VERSION ""

NS_ :

BS_:

BU_: CAMERA_ALL ALM_DX ALM_SX CAMERA_DEFAULT LOGBOX CAMERA_POS0 CAMERA_POS1 CAMERA_POS2 CAMERA_POS3 CAMERA_POS4 CAMERA_POS5 CAMERA_POS6 CAMERA_POS7 SVS RUR RUF RUC BC _TESTER BMS3_ADB BMS0_ADB BMS4_ADB BMS5_ADB BMS6_ADB

BO_ 2566850046 _BMS0_ADB_BatterySummaryStatus: 8 BMS0_ADB
 SG_ BMS0_ADB_BatSumS_serial_number : 0|24@1+ (1,0) [0|16777214] "-"  BC,LOGBOX
 SG_ BMS0_ADB_BatSumS_Reserved_01 : 24|8@1+ (1,0) [0|255] "-"  LOGBOX
 SG_ BMS0_ADB_BatSumS_State_of_Charge : 32|8@1+ (1,0) [0|100] "%"  LOGBOX,BC
 SG_ BMS0_ADB_BatSumS_State_of_Health : 40|8@1+ (1,0) [0|2] "-"  LOGBOX,BC
 SG_ BMS0_ADB_BatSumS_Temp_Alarm : 48|2@1+ (1,0) [0|3] "-"  LOGBOX,BC
 SG_ BMS0_ADB_BatSumS_DischargeDis : 50|1@1+ (1,0) [0|1] "-"  LOGBOX,BC
 SG_ BMS0_ADB_BatSumS_ChargingDisable : 51|1@1+ (1,0) [0|1] "-"  LOGBOX,BC
 SG_ BMS0_ADB_BatSumS_HeaterEnabled : 52|1@1+ (1,0) [0|1] "-"  LOGBOX,BC
 SG_ BMS0_ADB_BatSumS_BypassEnabled : 53|1@1+ (1,0) [0|1] "-"  LOGBOX,BC
 SG_ BMS0_ADB_BatSumS_Voltage_Alarm : 56|1@1+ (1,0) [0|1] "-"  LOGBOX,BC
 SG_ BMS0_ADB_BatSumS_Reserved_04 : 54|2@1+ (1,0) [0|3] "-"  LOGBOX
 SG_ BMS0_ADB_BatSumS_Reserved_05 : 57|1@1+ (1,0) [0|1] "-"  LOGBOX,BC
 SG_ BMS0_ADB_BatSumS_Reserved_06 : 58|1@1+ (1,0) [0|1] "-"  LOGBOX
 SG_ BMS0_ADB_BatSumS_Reserved_07 : 59|1@1+ (1,0) [0|1] "-"  LOGBOX
 SG_ BMS0_ADB_BatSumS_Reserved_08 : 60|1@1+ (1,0) [0|1] "-"  LOGBOX
 SG_ BMS0_ADB_BatSumS_Reserved_09 : 61|1@1+ (1,0) [0|1] "-"  LOGBOX
 SG_ BMS0_ADB_BatSumS_Reserved_10 : 62|1@1+ (1,0) [0|1] "-"  LOGBOX
 SG_ BMS0_ADB_BatSumS_Reserved_11 : 63|1@1+ (1,0) [0|1] "-"  LOGBOX

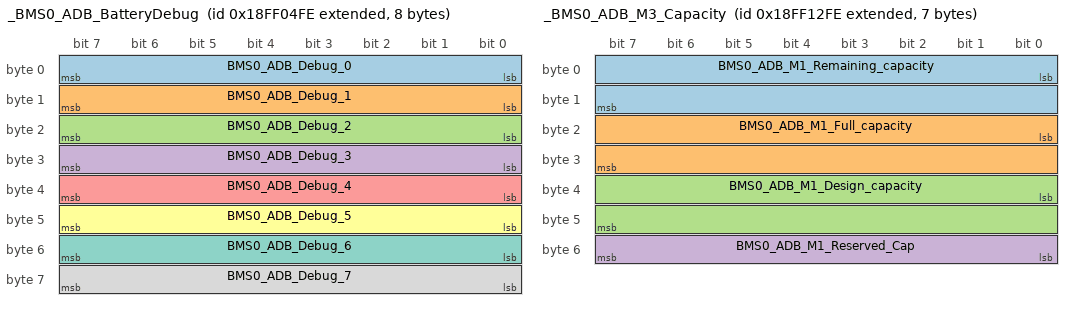
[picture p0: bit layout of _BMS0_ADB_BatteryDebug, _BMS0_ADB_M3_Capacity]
BO_ 2566849790 _BMS0_ADB_BatteryDebug: 8 BMS0_ADB
 SG_ BMS0_ADB_Debug_0 : 0|8@1+ (1,0) [0|255] "-"  LOGBOX
 SG_ BMS0_ADB_Debug_1 : 8|8@1+ (1,0) [0|255] "-"  LOGBOX
 SG_ BMS0_ADB_Debug_2 : 16|8@1+ (1,0) [0|255] "-"  LOGBOX
 SG_ BMS0_ADB_Debug_3 : 24|8@1+ (1,0) [0|255] "-"  LOGBOX
 SG_ BMS0_ADB_Debug_4 : 32|8@1+ (1,0) [0|255] "-"  LOGBOX
 SG_ BMS0_ADB_Debug_5 : 40|8@1+ (1,0) [0|255] "-"  LOGBOX
 SG_ BMS0_ADB_Debug_6 : 48|8@1+ (1,0) [0|255] "-"  LOGBOX
 SG_ BMS0_ADB_Debug_7 : 56|8@1+ (1,0) [0|255] "-"  LOGBOX

BO_ 2566853374 _BMS0_ADB_M3_Capacity: 7 BMS0_ADB
 SG_ BMS0_ADB_M1_Remaining_capacity : 0|16@1+ (0.01,0) [0|642.55] "Ah"  LOGBOX
 SG_ BMS0_ADB_M1_Full_capacity : 16|16@1+ (0.01,0) [0|642.55] "Ah"  LOGBOX
 SG_ BMS0_ADB_M1_Design_capacity : 32|16@1+ (0.01,0) [0|642.55] "Ah"  LOGBOX
 SG_ BMS0_ADB_M1_Reserved_Cap : 48|8@1+ (1,0) [255|255] "-"  LOGBOX

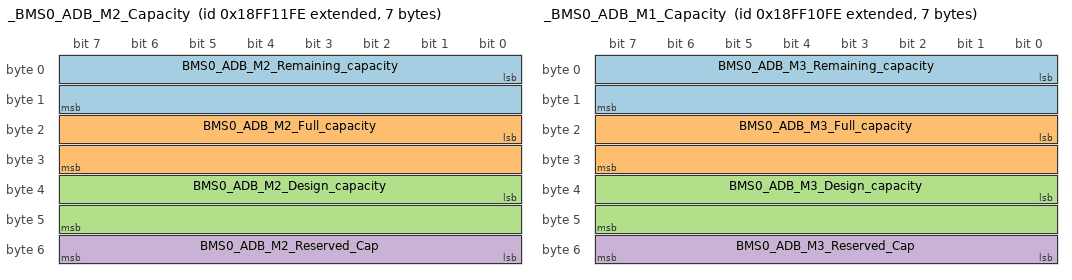
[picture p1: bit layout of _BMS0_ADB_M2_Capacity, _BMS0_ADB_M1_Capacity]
BO_ 2566853118 _BMS0_ADB_M2_Capacity: 7 BMS0_ADB
 SG_ BMS0_ADB_M2_Remaining_capacity : 0|16@1+ (0.01,0) [0|642.55] "Ah"  LOGBOX
 SG_ BMS0_ADB_M2_Full_capacity : 16|16@1+ (0.01,0) [0|642.55] "Ah"  LOGBOX
 SG_ BMS0_ADB_M2_Design_capacity : 32|16@1+ (0.01,0) [0|642.55] "Ah"  LOGBOX
 SG_ BMS0_ADB_M2_Reserved_Cap : 48|8@1+ (1,0) [255|255] "-"  LOGBOX

BO_ 2566852862 _BMS0_ADB_M1_Capacity: 7 BMS0_ADB
 SG_ BMS0_ADB_M3_Remaining_capacity : 0|16@1+ (0.01,0) [0|642.55] "Ah"  LOGBOX
 SG_ BMS0_ADB_M3_Full_capacity : 16|16@1+ (0.01,0) [0|642.55] "Ah"  LOGBOX
 SG_ BMS0_ADB_M3_Design_capacity : 32|16@1+ (0.01,0) [0|642.55] "Ah"  LOGBOX
 SG_ BMS0_ADB_M3_Reserved_Cap : 48|8@1+ (1,0) [255|255] "-"  LOGBOX

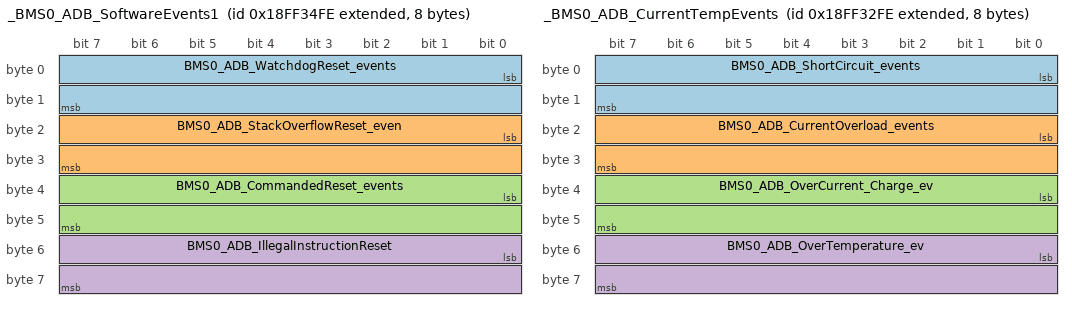
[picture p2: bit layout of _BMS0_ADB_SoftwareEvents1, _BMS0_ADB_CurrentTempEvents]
BO_ 2566862078 _BMS0_ADB_SoftwareEvents1: 8 BMS0_ADB
 SG_ BMS0_ADB_WatchdogReset_events : 0|16@1+ (1,0) [0|64255] "-"  LOGBOX
 SG_ BMS0_ADB_StackOverflowReset_even : 16|16@1+ (1,0) [0|64255] "-"  LOGBOX
 SG_ BMS0_ADB_CommandedReset_events : 32|16@1+ (1,0) [0|64255] "-"  LOGBOX
 SG_ BMS0_ADB_IllegalInstructionReset : 48|16@1+ (1,0) [0|64255] "-"  LOGBOX

BO_ 2566861822 _BMS0_ADB_VoltageEvents: 4 BMS0_ADB
 SG_ BMS0_ADB_OverVoltage_events : 0|16@1+ (1,0) [0|64255] "-"  LOGBOX
 SG_ BMS0_ADB_UnderVoltage_events : 16|16@1+ (1,0) [0|64255] "-"  LOGBOX

BO_ 2566861566 _BMS0_ADB_CurrentTempEvents: 8 BMS0_ADB
 SG_ BMS0_ADB_ShortCircuit_events : 0|16@1+ (1,0) [0|64255] "-"  LOGBOX
 SG_ BMS0_ADB_CurrentOverload_events : 16|16@1+ (1,0) [0|64255] "-"  LOGBOX
 SG_ BMS0_ADB_OverCurrent_Charge_ev : 32|16@1+ (1,0) [0|64255] "-"  LOGBOX
 SG_ BMS0_ADB_OverTemperature_ev : 48|16@1+ (1,0) [0|64255] "-"  LOGBOX

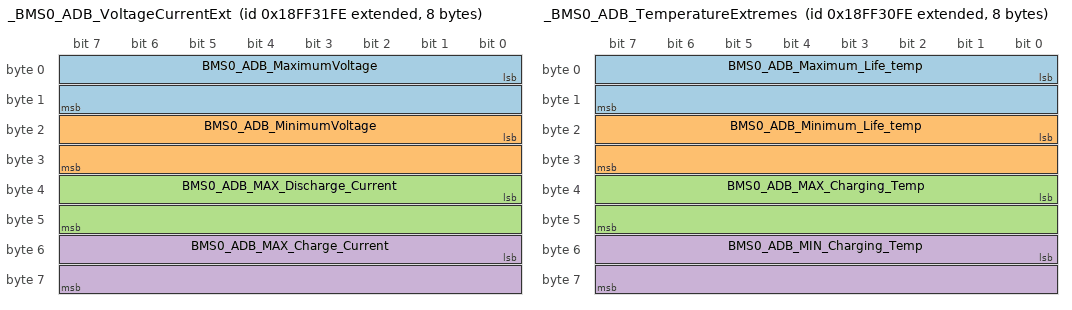
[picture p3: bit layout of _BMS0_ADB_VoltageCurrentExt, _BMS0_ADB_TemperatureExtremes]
BO_ 2566861310 _BMS0_ADB_VoltageCurrentExt: 8 BMS0_ADB
 SG_ BMS0_ADB_MaximumVoltage : 0|16@1+ (0.001,0) [0|64255] "V"  LOGBOX
 SG_ BMS0_ADB_MinimumVoltage : 16|16@1+ (0.001,0) [0|64255] "V"  LOGBOX
 SG_ BMS0_ADB_MAX_Discharge_Current : 32|16@1+ (0.1,0) [0|6425.5] "A"  LOGBOX
 SG_ BMS0_ADB_MAX_Charge_Current : 48|16@1+ (0.1,0) [0|6425.5] "A"  LOGBOX

BO_ 2566861054 _BMS0_ADB_TemperatureExtremes: 8 BMS0_ADB
 SG_ BMS0_ADB_Maximum_Life_temp : 0|16@1+ (0.1,-100) [-100|200] "°C"  LOGBOX
 SG_ BMS0_ADB_Minimum_Life_temp : 16|16@1+ (0.1,-100) [-100|200] "°C"  LOGBOX
 SG_ BMS0_ADB_MAX_Charging_Temp : 32|16@1+ (0.1,-100) [-100|200] "°C"  LOGBOX
 SG_ BMS0_ADB_MIN_Charging_Temp : 48|16@1+ (0.1,-100) [-100|200] "°C"  LOGBOX

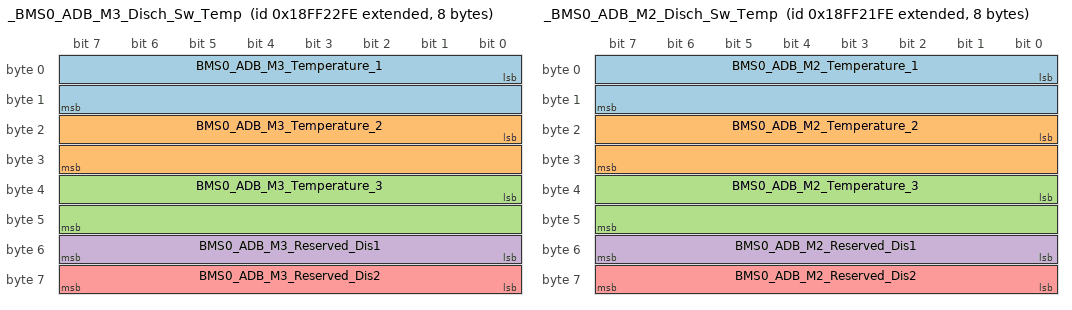
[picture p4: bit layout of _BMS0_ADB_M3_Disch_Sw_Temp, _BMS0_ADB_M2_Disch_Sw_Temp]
BO_ 2566857470 _BMS0_ADB_M3_Disch_Sw_Temp: 8 BMS0_ADB
 SG_ BMS0_ADB_M3_Temperature_1 : 0|16@1+ (0.1,-100) [-100|200] "°C"  LOGBOX
 SG_ BMS0_ADB_M3_Temperature_2 : 16|16@1+ (0.1,-100) [-100|200] "°C"  LOGBOX
 SG_ BMS0_ADB_M3_Temperature_3 : 32|16@1+ (0.1,-100) [-100|200] "°C"  LOGBOX
 SG_ BMS0_ADB_M3_Reserved_Dis1 : 48|8@1+ (1,0) [255|255] "-"  LOGBOX
 SG_ BMS0_ADB_M3_Reserved_Dis2 : 56|8@1+ (1,0) [255|255] "-"  LOGBOX

BO_ 2566857214 _BMS0_ADB_M2_Disch_Sw_Temp: 8 BMS0_ADB
 SG_ BMS0_ADB_M2_Temperature_1 : 0|16@1+ (0.1,-100) [-100|200] "°C"  LOGBOX
 SG_ BMS0_ADB_M2_Temperature_2 : 16|16@1+ (0.1,-100) [-100|200] "°C"  LOGBOX
 SG_ BMS0_ADB_M2_Temperature_3 : 32|16@1+ (0.1,-100) [-100|200] "°C"  LOGBOX
 SG_ BMS0_ADB_M2_Reserved_Dis1 : 48|8@1+ (1,0) [255|255] "-"  LOGBOX
 SG_ BMS0_ADB_M2_Reserved_Dis2 : 56|8@1+ (1,0) [255|255] "-"  LOGBOX

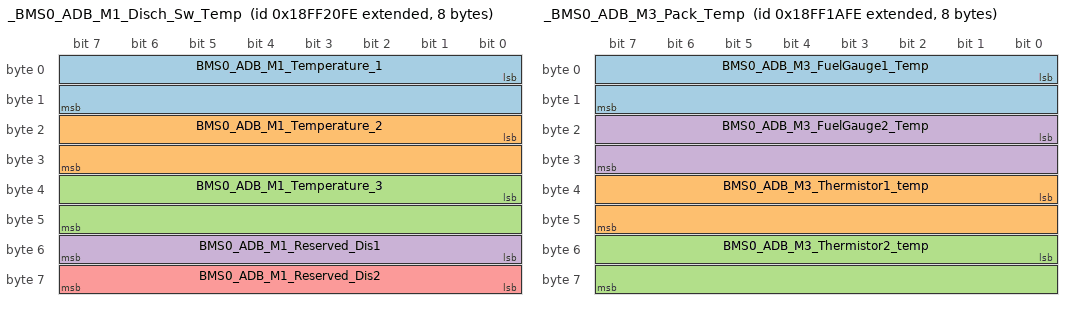
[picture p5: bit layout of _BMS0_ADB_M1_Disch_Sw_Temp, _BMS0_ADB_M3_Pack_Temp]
BO_ 2566856958 _BMS0_ADB_M1_Disch_Sw_Temp: 8 BMS0_ADB
 SG_ BMS0_ADB_M1_Temperature_1 : 0|16@1+ (0.1,-100) [-100|200] "°C"  LOGBOX
 SG_ BMS0_ADB_M1_Temperature_2 : 16|16@1+ (0.1,-100) [-100|200] "°C"  LOGBOX
 SG_ BMS0_ADB_M1_Temperature_3 : 32|16@1+ (0.1,-100) [-100|200] "°C"  LOGBOX
 SG_ BMS0_ADB_M1_Reserved_Dis1 : 48|8@1+ (1,0) [255|255] "-"  LOGBOX
 SG_ BMS0_ADB_M1_Reserved_Dis2 : 56|8@1+ (1,0) [255|255] "-"  LOGBOX

BO_ 2566855422 _BMS0_ADB_M3_Pack_Temp: 8 BMS0_ADB
 SG_ BMS0_ADB_M3_FuelGauge1_Temp : 0|16@1+ (0.1,-100) [-100|200] "°C"  LOGBOX
 SG_ BMS0_ADB_M3_Thermistor1_temp : 32|16@1+ (0.1,-100) [-100|200] "-"  LOGBOX
 SG_ BMS0_ADB_M3_Thermistor2_temp : 48|16@1+ (0.1,-100) [-100|200] "-"  LOGBOX
 SG_ BMS0_ADB_M3_FuelGauge2_Temp : 16|16@1+ (0.1,-100) [-100|200] "°C"  LOGBOX

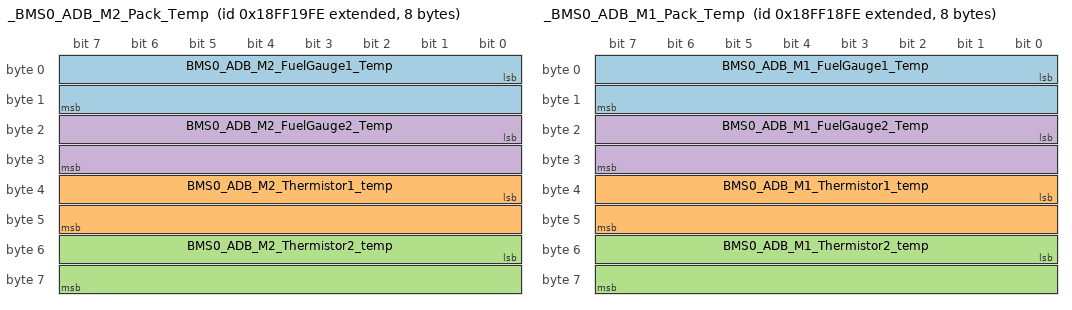
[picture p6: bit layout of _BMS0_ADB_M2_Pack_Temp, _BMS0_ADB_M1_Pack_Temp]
BO_ 2566855166 _BMS0_ADB_M2_Pack_Temp: 8 BMS0_ADB
 SG_ BMS0_ADB_M2_FuelGauge1_Temp : 0|16@1+ (0.1,-100) [-100|200] "°C"  LOGBOX
 SG_ BMS0_ADB_M2_Thermistor1_temp : 32|16@1+ (0.1,-100) [-100|200] "-"  LOGBOX
 SG_ BMS0_ADB_M2_Thermistor2_temp : 48|16@1+ (0.1,-100) [-100|200] "-"  LOGBOX
 SG_ BMS0_ADB_M2_FuelGauge2_Temp : 16|16@1+ (0.1,-100) [-100|200] "°C"  LOGBOX

BO_ 2566854910 _BMS0_ADB_M1_Pack_Temp: 8 BMS0_ADB
 SG_ BMS0_ADB_M1_FuelGauge1_Temp : 0|16@1+ (0.1,-100) [-100|200] "°C"  LOGBOX
 SG_ BMS0_ADB_M1_Thermistor1_temp : 32|16@1+ (0.1,-100) [-100|200] "-"  LOGBOX
 SG_ BMS0_ADB_M1_Thermistor2_temp : 48|16@1+ (0.1,-100) [-100|200] "-"  LOGBOX
 SG_ BMS0_ADB_M1_FuelGauge2_Temp : 16|16@1+ (0.1,-100) [-100|200] "°C"  LOGBOX

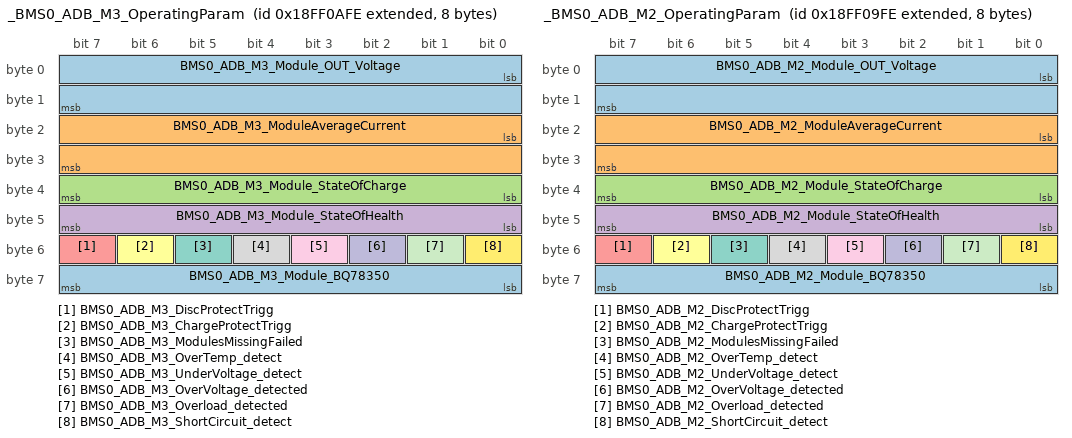
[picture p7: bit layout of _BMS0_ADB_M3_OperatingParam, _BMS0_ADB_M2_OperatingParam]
BO_ 2566851326 _BMS0_ADB_M3_OperatingParam: 8 BMS0_ADB
 SG_ BMS0_ADB_M3_Module_OUT_Voltage : 0|16@1+ (0.001,0) [0|64255] "V"  LOGBOX
 SG_ BMS0_ADB_M3_ModuleAverageCurrent : 16|16@1+ (0.1,-5500) [-5500|925.5] "A"  LOGBOX
 SG_ BMS0_ADB_M3_Module_StateOfCharge : 32|8@1+ (1,0) [0|100] "%"  LOGBOX
 SG_ BMS0_ADB_M3_Module_StateOfHealth : 40|8@1+ (1,0) [0|2] "-"  LOGBOX
 SG_ BMS0_ADB_M3_DiscProtectTrigg : 55|1@1+ (1,0) [0|1] "-"  LOGBOX
 SG_ BMS0_ADB_M3_ChargeProtectTrigg : 54|1@1+ (1,0) [0|1] "-"  LOGBOX
 SG_ BMS0_ADB_M3_ModulesMissingFailed : 53|1@1+ (1,0) [0|1] "-"  LOGBOX
 SG_ BMS0_ADB_M3_OverTemp_detect : 52|1@1+ (1,0) [0|1] "-"  LOGBOX
 SG_ BMS0_ADB_M3_UnderVoltage_detect : 51|1@1+ (1,0) [0|1] "-"  LOGBOX
 SG_ BMS0_ADB_M3_OverVoltage_detected : 50|1@1+ (1,0) [0|1] "-"  LOGBOX
 SG_ BMS0_ADB_M3_Overload_detected : 49|1@1+ (1,0) [0|1] "-"  LOGBOX
 SG_ BMS0_ADB_M3_ShortCircuit_detect : 48|1@1+ (1,0) [0|1] "-"  LOGBOX
 SG_ BMS0_ADB_M3_Module_BQ78350 : 56|8@1+ (1,0) [0|2] "-"  LOGBOX

BO_ 2566851070 _BMS0_ADB_M2_OperatingParam: 8 BMS0_ADB
 SG_ BMS0_ADB_M2_Module_OUT_Voltage : 0|16@1+ (0.001,0) [0|64255] "V"  LOGBOX
 SG_ BMS0_ADB_M2_ModuleAverageCurrent : 16|16@1+ (0.1,-5500) [-5500|925.5] "A"  LOGBOX
 SG_ BMS0_ADB_M2_Module_StateOfCharge : 32|8@1+ (1,0) [0|100] "%"  LOGBOX
 SG_ BMS0_ADB_M2_Module_StateOfHealth : 40|8@1+ (1,0) [0|2] "-"  LOGBOX
 SG_ BMS0_ADB_M2_DiscProtectTrigg : 55|1@1+ (1,0) [0|1] "-"  LOGBOX
 SG_ BMS0_ADB_M2_ChargeProtectTrigg : 54|1@1+ (1,0) [0|1] "-"  LOGBOX
 SG_ BMS0_ADB_M2_ModulesMissingFailed : 53|1@1+ (1,0) [0|1] "-"  LOGBOX
 SG_ BMS0_ADB_M2_OverTemp_detect : 52|1@1+ (1,0) [0|1] "-"  LOGBOX
 SG_ BMS0_ADB_M2_UnderVoltage_detect : 51|1@1+ (1,0) [0|1] "-"  LOGBOX
 SG_ BMS0_ADB_M2_OverVoltage_detected : 50|1@1+ (1,0) [0|1] "-"  LOGBOX
 SG_ BMS0_ADB_M2_Overload_detected : 49|1@1+ (1,0) [0|1] "-"  LOGBOX
 SG_ BMS0_ADB_M2_ShortCircuit_detect : 48|1@1+ (1,0) [0|1] "-"  LOGBOX
 SG_ BMS0_ADB_M2_Module_BQ78350 : 56|8@1+ (1,0) [0|2] "-"  LOGBOX

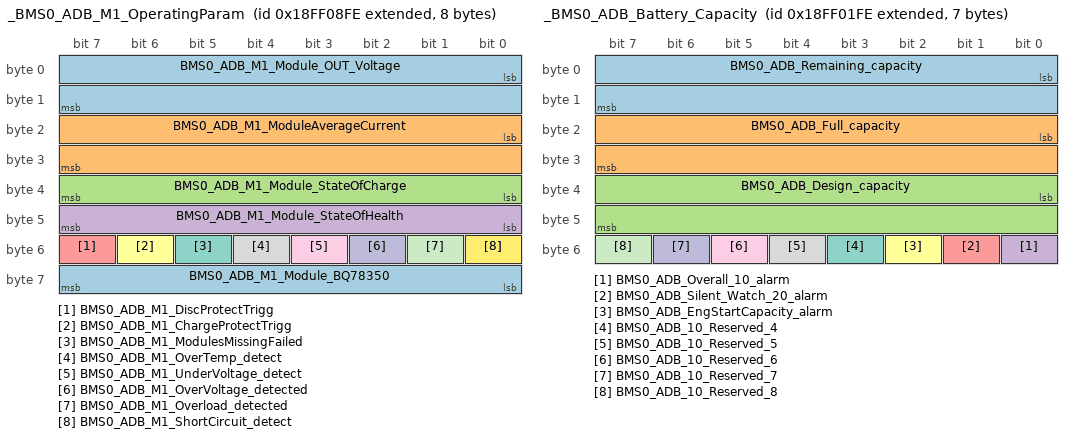
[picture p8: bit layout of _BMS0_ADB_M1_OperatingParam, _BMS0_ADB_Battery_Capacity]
BO_ 2566850814 _BMS0_ADB_M1_OperatingParam: 8 BMS0_ADB
 SG_ BMS0_ADB_M1_Module_OUT_Voltage : 0|16@1+ (0.001,0) [0|64255] "V"  LOGBOX
 SG_ BMS0_ADB_M1_ModuleAverageCurrent : 16|16@1+ (0.1,-5500) [-5500|925.5] "A"  LOGBOX
 SG_ BMS0_ADB_M1_Module_StateOfCharge : 32|8@1+ (1,0) [0|100] "%"  LOGBOX
 SG_ BMS0_ADB_M1_Module_StateOfHealth : 40|8@1+ (1,0) [0|2] "-"  LOGBOX
 SG_ BMS0_ADB_M1_DiscProtectTrigg : 55|1@1+ (1,0) [0|1] "-"  LOGBOX
 SG_ BMS0_ADB_M1_ChargeProtectTrigg : 54|1@1+ (1,0) [0|1] "-"  LOGBOX
 SG_ BMS0_ADB_M1_ModulesMissingFailed : 53|1@1+ (1,0) [0|1] "-"  LOGBOX
 SG_ BMS0_ADB_M1_OverTemp_detect : 52|1@1+ (1,0) [0|1] "-"  LOGBOX
 SG_ BMS0_ADB_M1_UnderVoltage_detect : 51|1@1+ (1,0) [0|1] "-"  LOGBOX
 SG_ BMS0_ADB_M1_OverVoltage_detected : 50|1@1+ (1,0) [0|1] "-"  LOGBOX
 SG_ BMS0_ADB_M1_Overload_detected : 49|1@1+ (1,0) [0|1] "-"  LOGBOX
 SG_ BMS0_ADB_M1_ShortCircuit_detect : 48|1@1+ (1,0) [0|1] "-"  LOGBOX
 SG_ BMS0_ADB_M1_Module_BQ78350 : 56|8@1+ (1,0) [0|2] "-"  LOGBOX

BO_ 2566849534 _BMS0_ADB_BatteryID: 6 BMS0_ADB
 SG_ BMS0_ADB_Battery_serial_number : 0|24@1+ (1,0) [0|16777214] "-"  LOGBOX
 SG_ BMS0_ADB_FirmwareVersionMajor : 24|8@1+ (1,0) [0|255] "-"  LOGBOX
 SG_ BMS0_ADB_FirmwareVersionMinor : 32|8@1+ (1,0) [0|255] "-"  LOGBOX
 SG_ BMS0_ADB_Firmware_Revision : 40|8@1+ (1,0) [0|255] "-"  LOGBOX

BO_ 2566849278 _BMS0_ADB_BatteryTemperature: 6 BMS0_ADB
 SG_ BMS0_ADB_Maximum_Temperature : 0|16@1+ (0.1,-100) [-100|200] "°C"  LOGBOX
 SG_ BMS0_ADB_Minimum_Temperature : 16|16@1+ (0.1,-100) [-100|200] "°C"  LOGBOX
 SG_ BMS0_ADB_Average_Temperature : 32|16@1+ (0.1,-100) [-100|200] "°C"  LOGBOX

BO_ 2566849022 _BMS0_ADB_Battery_Capacity: 7 BMS0_ADB
 SG_ BMS0_ADB_Remaining_capacity : 0|16@1+ (0.01,0) [0|642.55] "Ah"  LOGBOX
 SG_ BMS0_ADB_Full_capacity : 16|16@1+ (0.01,0) [0|642.55] "Ah"  LOGBOX
 SG_ BMS0_ADB_Design_capacity : 32|16@1+ (0.01,0) [0|642.55] "Ah"  LOGBOX
 SG_ BMS0_ADB_Overall_10_alarm : 48|1@1+ (1,0) [0|1] "-"  LOGBOX
 SG_ BMS0_ADB_Silent_Watch_20_alarm : 49|1@1+ (1,0) [0|1] "-"  LOGBOX
 SG_ BMS0_ADB_EngStartCapacity_alarm : 50|1@1+ (1,0) [0|1] "-"  LOGBOX
 SG_ BMS0_ADB_10_Reserved_4 : 51|1@1+ (1,0) [0|0] "-"  LOGBOX
 SG_ BMS0_ADB_10_Reserved_5 : 52|1@1+ (1,0) [0|0] "-"  LOGBOX
 SG_ BMS0_ADB_10_Reserved_6 : 53|1@1+ (1,0) [0|0] "-"  LOGBOX
 SG_ BMS0_ADB_10_Reserved_7 : 54|1@1+ (1,0) [0|0] "-"  LOGBOX
 SG_ BMS0_ADB_10_Reserved_8 : 55|1@1+ (1,0) [0|0] "-"  LOGBOX

BO_ 2566848766 _BMS0_ADB_BatteryOperatingParam: 8 BMS0_ADB
 SG_ BMS0_ADB_Batt_OUT_Voltage : 0|16@1+ (0.001,0) [0|64255] "V"  LOGBOX
 SG_ BMS0_ADB_Batt_Average_Current : 16|16@1+ (0.1,-5500) [-5500|925.5] "A"  LOGBOX
 SG_ BMS0_ADB_Batt_StsOfCharge : 32|8@1+ (1,0) [0|100] "%"  LOGBOX
 SG_ BMS0_ADB_Batt_StsOfHealth : 40|8@1+ (1,0) [0|2] "-"  LOGBOX
 SG_ BMS0_ADB_Batt_PS8_discharge_prot : 55|1@1+ (1,0) [0|1] "-"  LOGBOX
 SG_ BMS0_ADB_Batt_PS7_charge_prot : 54|1@1+ (1,0) [0|1] "-"  LOGBOX
 SG_ BMS0_ADB_Batt_PS6_mod_failed : 53|1@1+ (1,0) [0|1] "-"  LOGBOX
 SG_ BMS0_ADB_Batt_PS5_over_temp : 52|1@1+ (1,0) [0|1] "-"  LOGBOX
 SG_ BMS0_ADB_Batt_PS4_under_voltage : 51|1@1+ (1,0) [0|1] "-"  LOGBOX
 SG_ BMS0_ADB_Batt_PS3_over_voltage : 50|1@1+ (1,0) [0|1] "-"  LOGBOX
 SG_ BMS0_ADB_Batt_PS2_overload : 49|1@1+ (1,0) [0|1] "-"  LOGBOX
 SG_ BMS0_ADB_Batt_PS1_short_circuit : 48|1@1+ (1,0) [0|1] "-"  LOGBOX
 SG_ BMS0_ADB_Batt_OS_8_sleep_mode : 63|1@1+ (1,0) [0|1] "-"  LOGBOX
 SG_ BMS0_ADB_Batt_OS_7_emerg_used : 62|1@1+ (1,0) [0|1] "-"  LOGBOX
 SG_ BMS0_ADB_Batt_OS_6_emergency : 61|1@1+ (1,0) [0|1] "-"  LOGBOX
 SG_ BMS0_ADB_Batt_OS_45_charge_level : 59|2@1+ (1,0) [0|3] "-"  LOGBOX
 SG_ BMS0_ADB_Batt_OS_3_charge_cont : 58|1@1+ (1,0) [0|1] "-"  LOGBOX
 SG_ BMS0_ADB_Batt_OS_2_heater_cont : 57|1@1+ (1,0) [0|1] "-"  LOGBOX
 SG_ BMS0_ADB_Batt_OS_1_master_prot : 56|1@1+ (1,0) [0|1] "-"  LOGBOX

BO_ 2566804222 _BMS0_ADB_VEP_3: 8 BMS0_ADB
 SG_ _nu_BMS0_ADB_AlternatorCurrent : 0|16@1+ (0.05,-1600) [-1600|1612.75] "A"  LOGBOX
 SG_ BMS0_ADB_NetBattery_Current : 16|16@1+ (0.05,-1600) [-1600|1612.75] "A"  LOGBOX

BO_ 2566803710 _BMS0_ADB_Battery_1_Temp: 8 BMS0_ADB
 SG_ BMS0_ADB_Battery1_Temperature : 0|8@1+ (1,-40) [-40|210] "°C"  LOGBOX
 SG_ _nu_BMS0_ADB_Battery2_Temp : 8|8@1+ (1,-40) [-40|210] "°C"  LOGBOX

BO_ 2566698750 _BMS0_ADB_VEP_5: 8 BMS0_ADB
 SG_ BMS0_ADB_SLI_BattPack_StOfCharge : 0|16@1+ (0.0025,0) [0|1606375] "%"  LOGBOX
 SG_ BMS0_ADB_SLI_BattPack_Capacity : 16|16@1+ (1,0) [0|64255] "Ah"  LOGBOX
 SG_ BMS0_ADB_SLI_BattPack_Health : 32|8@1+ (0.5,0) [0|100] "%"  LOGBOX

BO_ 2566862334 _BMS0_ADB_SoftwareEvents2: 8 BMS0_ADB
 SG_ BMS0_ADB_HardMCLRReset_events : 0|16@1+ (1,0) [0|64255] "-"  LOGBOX
 SG_ BMS0_ADB_LowVoltageReset_events : 16|16@1+ (1,0) [0|64255] "-"  LOGBOX
 SG_ BMS0_ADB_PORReset_events : 32|16@1+ (1,0) [0|64255] "-"  LOGBOX
 SG_ BMS0_ADB_BrownOutReset_events : 48|16@1+ (1,0) [0|64255] "-"  LOGBOX

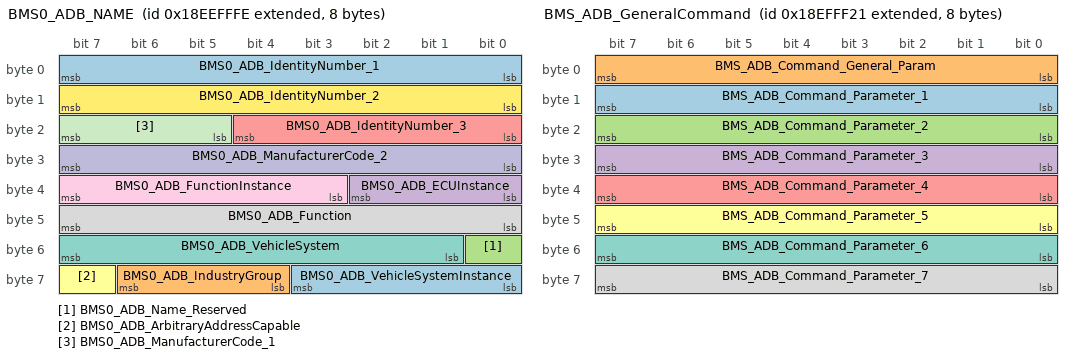
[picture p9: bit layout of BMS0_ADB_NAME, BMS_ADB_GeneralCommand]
BO_ 2565799934 BMS0_ADB_NAME: 8 BMS0_ADB
 SG_ BMS0_ADB_VehicleSystemInstance : 56|4@1+ (1,0) [0|15] "-"  LOGBOX,BC
 SG_ BMS0_ADB_IndustryGroup : 60|3@1+ (1,0) [0|7] "-"  LOGBOX,BC
 SG_ BMS0_ADB_Name_Reserved : 48|1@1+ (1,0) [0|1] "-"  LOGBOX,BC
 SG_ BMS0_ADB_ECUInstance : 32|3@1+ (1,0) [0|7] "-"  LOGBOX,BC
 SG_ BMS0_ADB_IdentityNumber_3 : 16|5@1+ (1,0) [0|31] "-"  LOGBOX,BC
 SG_ BMS0_ADB_ArbitraryAddressCapable : 63|1@1+ (1,0) [0|1] "-"  LOGBOX,BC
 SG_ BMS0_ADB_VehicleSystem : 49|7@1+ (1,0) [0|127] "-"  LOGBOX,BC
 SG_ BMS0_ADB_Function : 40|8@1+ (1,0) [0|255] "-"  LOGBOX,BC
 SG_ BMS0_ADB_FunctionInstance : 35|5@1+ (1,0) [0|31] "-"  LOGBOX,BC
 SG_ BMS0_ADB_ManufacturerCode_2 : 24|8@1+ (1,0) [0|255] "-"  LOGBOX,BC
 SG_ BMS0_ADB_ManufacturerCode_1 : 21|3@1+ (1,0) [0|7] "-"  LOGBOX,BC
 SG_ BMS0_ADB_IdentityNumber_2 : 8|8@1+ (1,0) [0|255] "-"  LOGBOX,BC
 SG_ BMS0_ADB_IdentityNumber_1 : 0|8@1+ (1,0) [0|255] "-"  LOGBOX,BC

BO_ 2566838305 BMS_ADB_CommandedAddress: 9 BC
 SG_ BMS_ADB_VehicleSystemInstance : 56|4@1+ (1,0) [0|15] "-"  BMS6_ADB,BMS5_ADB,BMS4_ADB,BMS3_ADB,LOGBOX,BMS0_ADB
 SG_ BMS_ADB_IndustryGroup : 60|3@1+ (1,0) [0|7] "-"  BMS6_ADB,BMS5_ADB,BMS4_ADB,BMS3_ADB,LOGBOX,BMS0_ADB
 SG_ BMS_ADB_Reserved : 48|1@1+ (1,0) [0|1] "-"  BMS6_ADB,BMS5_ADB,BMS4_ADB,BMS3_ADB,LOGBOX,BMS0_ADB
 SG_ BMS_ADB_ECUInstance : 32|3@1+ (1,0) [0|7] "-"  BMS6_ADB,BMS5_ADB,BMS4_ADB,BMS3_ADB,LOGBOX,BMS0_ADB
 SG_ BMS_ADB_IdentityNumber_3 : 16|5@1+ (1,0) [0|31] "-"  BMS6_ADB,BMS5_ADB,BMS4_ADB,BMS3_ADB,LOGBOX,BMS0_ADB
 SG_ BMS_ADB_NewSourceAddress : 64|8@1+ (1,0) [0|255] "-"  BMS6_ADB,BMS5_ADB,BMS4_ADB,BMS3_ADB,LOGBOX,BMS0_ADB
 SG_ BMS_ADB_ArbitraryAddressCapable : 63|1@1+ (1,0) [0|1] "-"  BMS6_ADB,BMS5_ADB,BMS4_ADB,BMS3_ADB,LOGBOX,BMS0_ADB
 SG_ BMS_ADB_VehicleSystem : 49|7@1+ (1,0) [0|127] "-"  BMS6_ADB,BMS5_ADB,BMS4_ADB,BMS3_ADB,LOGBOX,BMS0_ADB
 SG_ BMS_ADB_Function : 40|8@1+ (1,0) [0|255] "-"  BMS6_ADB,BMS5_ADB,BMS4_ADB,BMS3_ADB,LOGBOX,BMS0_ADB
 SG_ BMS_ADB_FunctionInstance : 35|5@1+ (1,0) [0|31] "-"  BMS6_ADB,BMS5_ADB,BMS4_ADB,BMS3_ADB,LOGBOX,BMS0_ADB
 SG_ BMS_ADB_ManufacturerCode_2 : 24|8@1+ (1,0) [0|255] "-"  BMS6_ADB,BMS5_ADB,BMS4_ADB,BMS3_ADB,LOGBOX,BMS0_ADB
 SG_ BMS_ADB_ManufacturerCode_1 : 21|3@1+ (1,0) [0|7] "-"  BMS6_ADB,BMS5_ADB,BMS4_ADB,BMS3_ADB,LOGBOX,BMS0_ADB
 SG_ BMS_ADB_IdentityNumber_2 : 8|8@1+ (1,0) [0|255] "-"  BMS6_ADB,BMS5_ADB,BMS4_ADB,BMS3_ADB,LOGBOX,BMS0_ADB
 SG_ BMS_ADB_IdentityNumber_1 : 0|8@1+ (1,0) [0|255] "-"  BMS6_ADB,BMS5_ADB,BMS4_ADB,BMS3_ADB,LOGBOX,BMS0_ADB

BO_ 2582642465 _BMS_ADB_ResetCommand: 1 BC
 SG_ BMS_ADB_ResetCommand : 0|8@1+ (1,0) [52|52] "-"  BMS6_ADB,BMS5_ADB,BMS4_ADB,BMS3_ADB,LOGBOX,BMS0_ADB

BO_ 2565865249 BMS_ADB_GeneralCommand: 8 BC
 SG_ BMS_ADB_Command_Parameter_1 : 8|8@1+ (1,0) [0|3] "-"  BMS6_ADB,BMS5_ADB,BMS4_ADB,BMS3_ADB,LOGBOX,BMS0_ADB
 SG_ BMS_ADB_Command_General_Param : 0|8@1+ (1,0) [1|3] "-"  BMS6_ADB,BMS5_ADB,BMS4_ADB,BMS3_ADB,LOGBOX,BMS0_ADB
 SG_ BMS_ADB_Command_Parameter_2 : 16|8@1+ (1,0) [0|0] "-"  BMS6_ADB,BMS5_ADB,BMS4_ADB,BMS3_ADB,LOGBOX,BMS0_ADB
 SG_ BMS_ADB_Command_Parameter_3 : 24|8@1+ (1,0) [0|0] "-"  BMS6_ADB,BMS5_ADB,BMS4_ADB,BMS3_ADB,LOGBOX,BMS0_ADB
 SG_ BMS_ADB_Command_Parameter_4 : 32|8@1+ (1,0) [0|0] "-"  BMS6_ADB,BMS5_ADB,BMS4_ADB,BMS3_ADB,LOGBOX,BMS0_ADB
 SG_ BMS_ADB_Command_Parameter_5 : 40|8@1+ (1,0) [0|0] "-"  BMS6_ADB,BMS5_ADB,BMS4_ADB,BMS3_ADB,LOGBOX,BMS0_ADB
 SG_ BMS_ADB_Command_Parameter_6 : 48|8@1+ (1,0) [0|0] "-"  BMS6_ADB,BMS5_ADB,BMS4_ADB,BMS3_ADB,LOGBOX,BMS0_ADB
 SG_ BMS_ADB_Command_Parameter_7 : 56|8@1+ (1,0) [0|0] "-"  BMS6_ADB,BMS5_ADB,BMS4_ADB,BMS3_ADB,LOGBOX,BMS0_ADB

BO_ 2565537569 BMS_ADB_PGN_REQ: 3 BC
 SG_ BMS_ADB_Pgn_Req_Byte_2 : 16|8@1+ (1,0) [0|255] "-"  BMS6_ADB,BMS5_ADB,BMS4_ADB,BMS3_ADB,LOGBOX,BMS0_ADB
 SG_ BMS_ADB_Pgn_Req_Byte_1 : 8|8@1+ (1,0) [0|255] "-"  BMS6_ADB,BMS5_ADB,BMS4_ADB,BMS3_ADB,LOGBOX,BMS0_ADB
 SG_ BMS_ADB_Pgn_Req_Byte_0 : 0|8@1+ (1,0) [0|255] "-"  BMS6_ADB,BMS5_ADB,BMS4_ADB,BMS3_ADB,LOGBOX,BMS0_ADB

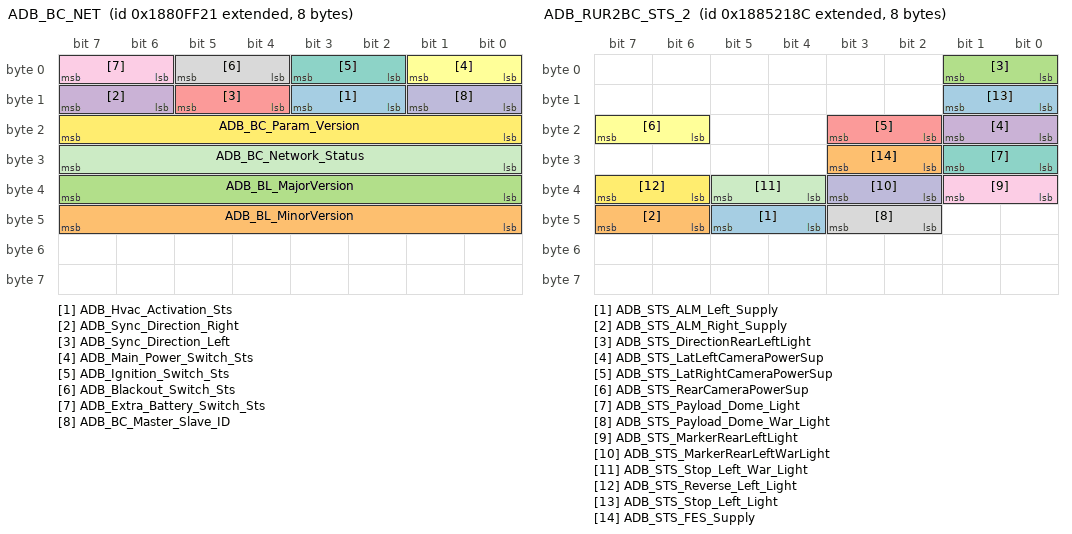
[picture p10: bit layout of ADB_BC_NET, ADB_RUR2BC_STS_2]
BO_ 2558590753 ADB_BC_NET: 8 BC
 SG_ ADB_Hvac_Activation_Sts : 10|2@1+ (1,0) [0|3] "-" Vector__XXX
 SG_ ADB_BL_MinorVersion : 40|8@1+ (1,0) [0|255] ""  RUR,LOGBOX,RUF,RUC
 SG_ ADB_BL_MajorVersion : 32|8@1+ (1,0) [0|255] ""  RUR,LOGBOX,RUF,RUC
 SG_ ADB_Sync_Direction_Right : 14|2@1+ (1,0) [0|3] "-"  RUR,LOGBOX,RUF,RUC
 SG_ ADB_Sync_Direction_Left : 12|2@1+ (1,0) [0|3] "-"  RUR,LOGBOX,RUF,RUC
 SG_ ADB_Main_Power_Switch_Sts : 0|2@1+ (1,0) [0|3] "-"  RUR,LOGBOX,RUF,RUC
 SG_ ADB_Ignition_Switch_Sts : 2|2@1+ (1,0) [0|3] "-"  RUR,LOGBOX,RUF,RUC
 SG_ ADB_Blackout_Switch_Sts : 4|2@1+ (1,0) [0|3] "-"  RUR,LOGBOX,RUF,RUC
 SG_ ADB_Extra_Battery_Switch_Sts : 6|2@1+ (1,0) [0|3] "-"  RUR,LOGBOX,RUF,RUC
 SG_ ADB_BC_Master_Slave_ID : 8|2@1+ (1,0) [0|3] "-"  RUR,LOGBOX,RUF,RUC
 SG_ ADB_BC_Network_Status : 24|8@1+ (1,0) [0|1] "-"  RUR,LOGBOX,RUF,RUC
 SG_ ADB_BC_Param_Version : 16|8@1+ (1,0) [0|255] "-"  RUR,LOGBOX,RUF,RUC

BO_ 2558861708 ADB_RUR2BC_STS_2: 8 RUR
 SG_ ADB_STS_ALM_Left_Supply : 44|2@1+ (1,0) [0|3] "-"  LOGBOX
 SG_ ADB_STS_ALM_Right_Supply : 46|2@1+ (1,0) [0|3] "-"  LOGBOX
 SG_ ADB_STS_DirectionRearLeftLight : 0|2@1+ (1,0) [0|3] "-"  LOGBOX
 SG_ ADB_STS_LatLeftCameraPowerSup : 16|2@1+ (1,0) [0|3] "-"  LOGBOX
 SG_ ADB_STS_LatRightCameraPowerSup : 18|2@1+ (1,0) [0|3] "-"  LOGBOX
 SG_ ADB_STS_RearCameraPowerSup : 22|2@1+ (1,0) [0|3] "-"  LOGBOX
 SG_ ADB_STS_Payload_Dome_Light : 24|2@1+ (1,0) [0|3] "-"  LOGBOX
 SG_ ADB_STS_Payload_Dome_War_Light : 42|2@1+ (1,0) [0|3] "-"  LOGBOX
 SG_ ADB_STS_MarkerRearLeftLight : 32|2@1+ (1,0) [0|3] "-"  LOGBOX
 SG_ ADB_STS_MarkerRearLeftWarLight : 34|2@1+ (1,0) [0|3] "-"  LOGBOX
 SG_ ADB_STS_Stop_Left_War_Light : 36|2@1+ (1,0) [0|3] "-"  LOGBOX
 SG_ ADB_STS_Reverse_Left_Light : 38|2@1+ (1,0) [0|3] "-"  LOGBOX
 SG_ ADB_STS_Stop_Left_Light : 8|2@1+ (1,0) [0|3] "-"  LOGBOX
 SG_ ADB_STS_FES_Supply : 26|2@1+ (1,0) [0|3] "-"  LOGBOX

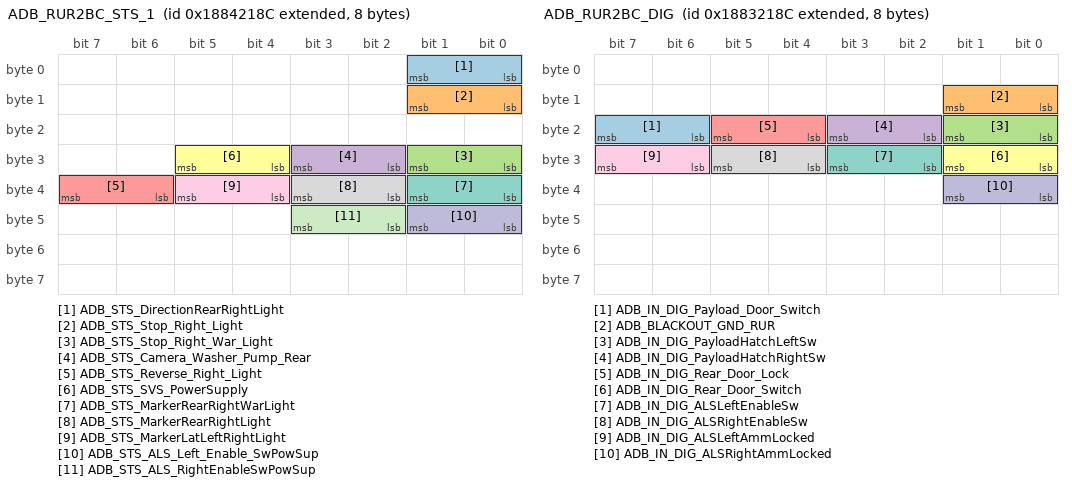
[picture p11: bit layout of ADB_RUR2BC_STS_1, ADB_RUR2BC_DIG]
BO_ 2558796172 ADB_RUR2BC_STS_1: 8 RUR
 SG_ ADB_STS_DirectionRearRightLight : 0|2@1+ (1,0) [0|3] "-"  LOGBOX
 SG_ ADB_STS_Stop_Right_Light : 8|2@1+ (1,0) [0|3] "-"  LOGBOX
 SG_ ADB_STS_Stop_Right_War_Light : 24|2@1+ (1,0) [0|3] "-"  LOGBOX
 SG_ ADB_STS_Camera_Washer_Pump_Rear : 26|2@1+ (1,0) [0|3] "-"  LOGBOX
 SG_ ADB_STS_Reverse_Right_Light : 38|2@1+ (1,0) [0|3] "-"  LOGBOX
 SG_ ADB_STS_SVS_PowerSupply : 28|2@1+ (1,0) [0|3] "-"  LOGBOX
 SG_ ADB_STS_MarkerRearRightWarLight : 32|2@1+ (1,0) [0|3] "-"  LOGBOX
 SG_ ADB_STS_MarkerRearRightLight : 34|2@1+ (1,0) [0|3] "-"  LOGBOX
 SG_ ADB_STS_MarkerLatLeftRightLight : 36|2@1+ (1,0) [0|3] "-"  LOGBOX
 SG_ ADB_STS_ALS_Left_Enable_SwPowSup : 40|2@1+ (1,0) [0|3] "-"  LOGBOX
 SG_ ADB_STS_ALS_RightEnableSwPowSup : 42|2@1+ (1,0) [0|3] "-"  LOGBOX

BO_ 2558730636 ADB_RUR2BC_DIG: 8 RUR
 SG_ ADB_IN_DIG_Payload_Door_Switch : 22|2@1+ (1,0) [0|3] "-"  SVS,LOGBOX,BC
 SG_ ADB_BLACKOUT_GND_RUR : 8|2@1+ (1,0) [0|3] "-"  LOGBOX,BC
 SG_ ADB_IN_DIG_PayloadHatchLeftSw : 16|2@1+ (1,0) [0|3] "-"  SVS,LOGBOX,BC
 SG_ ADB_IN_DIG_PayloadHatchRightSw : 18|2@1+ (1,0) [0|3] "-"  SVS,LOGBOX,BC
 SG_ ADB_IN_DIG_Rear_Door_Lock : 20|2@1+ (1,0) [0|3] "-"  LOGBOX,BC
 SG_ ADB_IN_DIG_Rear_Door_Switch : 24|2@1+ (1,0) [0|3] "-"  LOGBOX,BC
 SG_ ADB_IN_DIG_ALSLeftEnableSw : 26|2@1+ (1,0) [0|3] "-"  LOGBOX,BC
 SG_ ADB_IN_DIG_ALSRightEnableSw : 28|2@1+ (1,0) [0|3] "-"  LOGBOX,BC
 SG_ ADB_IN_DIG_ALSLeftAmmLocked : 30|2@1+ (1,0) [0|3] "-"  LOGBOX,BC
 SG_ ADB_IN_DIG_ALSRightAmmLocked : 32|2@1+ (1,0) [0|3] "-"  LOGBOX,BC

BO_ 2558665100 ADB_RUR2BC_ANA_2: 8 RUR
 SG_ ADB_IN_ANA_FuelLevelLeftRear : 40|8@1+ (4,0) [0|1000] "ohm"  LOGBOX,BC
 SG_ ADB_IN_ANA_FuelLevelRightRear : 48|8@1+ (4,0) [0|1000] "ohm"  LOGBOX,BC

BO_ 2558599564 ADB_RUR2BC_ANA_1: 8 RUR

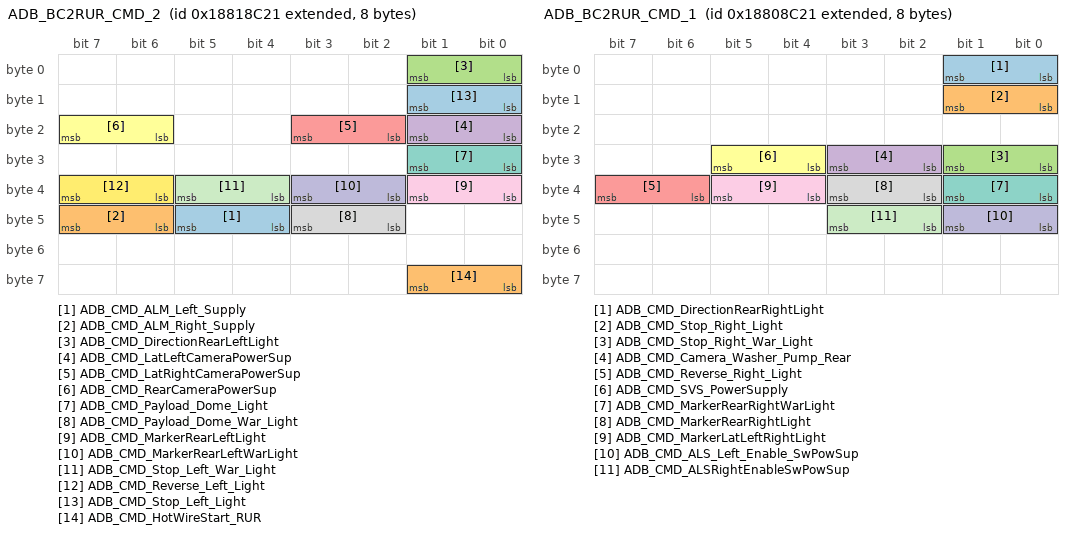
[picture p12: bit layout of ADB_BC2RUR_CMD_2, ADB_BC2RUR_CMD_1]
BO_ 2558626849 ADB_BC2RUR_CMD_2: 8 BC
 SG_ ADB_CMD_ALM_Left_Supply : 44|2@1+ (1,0) [0|3] "-"  LOGBOX,RUR
 SG_ ADB_CMD_ALM_Right_Supply : 46|2@1+ (1,0) [0|3] "-"  LOGBOX,RUR
 SG_ ADB_CMD_DirectionRearLeftLight : 0|2@1+ (1,0) [0|3] "-"  LOGBOX,RUR
 SG_ ADB_CMD_LatLeftCameraPowerSup : 16|2@1+ (1,0) [0|3] "-"  LOGBOX,RUR
 SG_ ADB_CMD_LatRightCameraPowerSup : 18|2@1+ (1,0) [0|3] "-"  LOGBOX,RUR
 SG_ ADB_CMD_RearCameraPowerSup : 22|2@1+ (1,0) [0|3] "-"  LOGBOX,RUR
 SG_ ADB_CMD_Payload_Dome_Light : 24|2@1+ (1,0) [0|3] "-"  LOGBOX,RUR
 SG_ ADB_CMD_Payload_Dome_War_Light : 42|2@1+ (1,0) [0|3] "-"  LOGBOX,RUR
 SG_ ADB_CMD_MarkerRearLeftLight : 32|2@1+ (1,0) [0|3] "-"  LOGBOX,RUR
 SG_ ADB_CMD_MarkerRearLeftWarLight : 34|2@1+ (1,0) [0|3] "-"  LOGBOX,RUR
 SG_ ADB_CMD_Stop_Left_War_Light : 36|2@1+ (1,0) [0|3] "-"  LOGBOX,RUR
 SG_ ADB_CMD_Reverse_Left_Light : 38|2@1+ (1,0) [0|3] "-"  LOGBOX,RUR
 SG_ ADB_CMD_Stop_Left_Light : 8|2@1+ (1,0) [0|3] "-"  LOGBOX,RUR
 SG_ ADB_CMD_HotWireStart_RUR : 56|2@1+ (1,0) [0|3] "-"  LOGBOX,RUR

BO_ 2558561313 ADB_BC2RUR_CMD_1: 8 BC
 SG_ ADB_CMD_DirectionRearRightLight : 0|2@1+ (1,0) [0|3] "-"  LOGBOX,RUR
 SG_ ADB_CMD_Stop_Right_Light : 8|2@1+ (1,0) [0|3] "-"  LOGBOX,RUR
 SG_ ADB_CMD_Stop_Right_War_Light : 24|2@1+ (1,0) [0|3] "-"  LOGBOX,RUR
 SG_ ADB_CMD_Camera_Washer_Pump_Rear : 26|2@1+ (1,0) [0|3] "-"  LOGBOX,RUR
 SG_ ADB_CMD_Reverse_Right_Light : 38|2@1+ (1,0) [0|3] "-"  LOGBOX,RUR
 SG_ ADB_CMD_SVS_PowerSupply : 28|2@1+ (1,0) [0|3] "-"  LOGBOX,RUR
 SG_ ADB_CMD_MarkerRearRightWarLight : 32|2@1+ (1,0) [0|3] "-"  LOGBOX,RUR
 SG_ ADB_CMD_MarkerRearRightLight : 34|2@1+ (1,0) [0|3] "-"  LOGBOX,RUR
 SG_ ADB_CMD_MarkerLatLeftRightLight : 36|2@1+ (1,0) [0|3] "-"  LOGBOX,RUR
 SG_ ADB_CMD_ALS_Left_Enable_SwPowSup : 40|2@1+ (1,0) [0|3] "-"  LOGBOX,RUR
 SG_ ADB_CMD_ALSRightEnableSwPowSup : 42|2@1+ (1,0) [0|3] "-"  LOGBOX,RUR

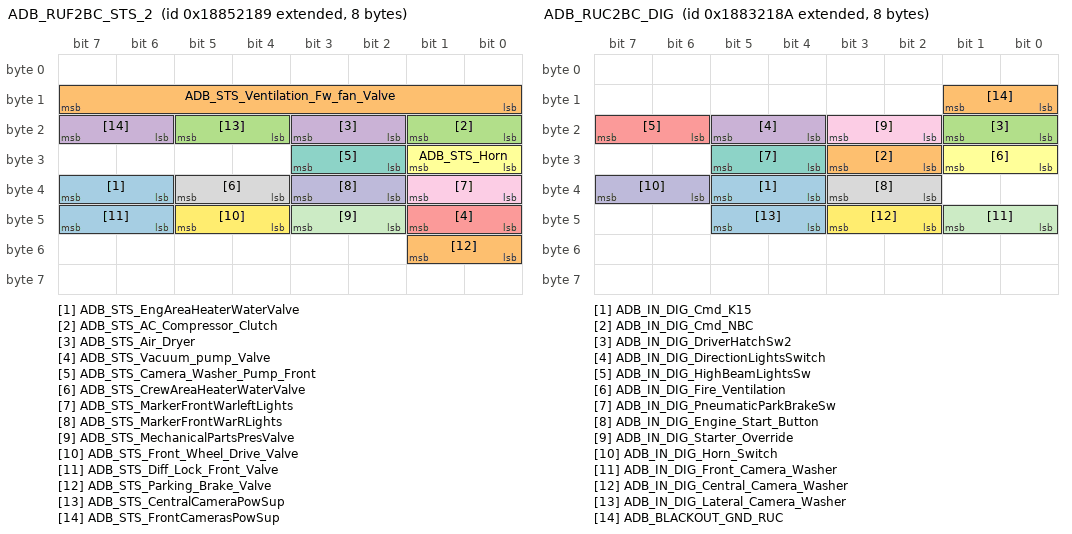
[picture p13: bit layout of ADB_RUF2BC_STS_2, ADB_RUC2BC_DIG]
BO_ 2558861705 ADB_RUF2BC_STS_2: 8 RUF
 SG_ ADB_STS_EngAreaHeaterWaterValve : 38|2@1+ (1,0) [0|3] "-"  LOGBOX
 SG_ ADB_STS_Ventilation_Fw_fan_Valve : 8|8@1+ (0.4,0) [0|100] "%"  LOGBOX
 SG_ ADB_STS_AC_Compressor_Clutch : 16|2@1+ (1,0) [0|3] "-"  LOGBOX
 SG_ ADB_STS_Air_Dryer : 18|2@1+ (1,0) [0|3] "-"  LOGBOX
 SG_ ADB_STS_Vacuum_pump_Valve : 40|2@1+ (1,0) [0|3] "-"  LOGBOX
 SG_ ADB_STS_Horn : 24|2@1+ (1,0) [0|3] "-"  LOGBOX
 SG_ ADB_STS_Camera_Washer_Pump_Front : 26|2@1+ (1,0) [0|3] "-"  LOGBOX
 SG_ ADB_STS_CrewAreaHeaterWaterValve : 36|2@1+ (1,0) [0|3] "-"  LOGBOX
 SG_ ADB_STS_MarkerFrontWarleftLights : 32|2@1+ (1,0) [0|3] "-"  LOGBOX
 SG_ ADB_STS_MarkerFrontWarRLights : 34|2@1+ (1,0) [0|3] "-"  LOGBOX
 SG_ ADB_STS_MechanicalPartsPresValve : 42|2@1+ (1,0) [0|3] "-"  LOGBOX
 SG_ ADB_STS_Front_Wheel_Drive_Valve : 44|2@1+ (1,0) [0|3] "-"  LOGBOX
 SG_ ADB_STS_Diff_Lock_Front_Valve : 46|2@1+ (1,0) [0|3] "-"  LOGBOX
 SG_ ADB_STS_Parking_Brake_Valve : 48|2@1+ (1,0) [0|3] "-"  LOGBOX
 SG_ ADB_STS_CentralCameraPowSup : 20|2@1+ (1,0) [0|3] "-"  LOGBOX
 SG_ ADB_STS_FrontCamerasPowSup : 22|2@1+ (1,0) [0|3] "-"  LOGBOX

BO_ 2558796169 ADB_RUF2BC_STS_1: 8 RUF
 SG_ ADB_STS_SteeringValve : 0|8@1+ (0.4,0) [0|100] "%"  LOGBOX
 SG_ ADB_STS_Front_Fuel_Pump_1 : 16|2@1+ (1,0) [0|3] "-"  LOGBOX
 SG_ ADB_STS_Front_Fuel_Pump_2 : 18|2@1+ (1,0) [0|3] "-"  LOGBOX
 SG_ ADB_STS_LowBeam_Left_Light : 20|2@1+ (1,0) [0|3] "-"  LOGBOX
 SG_ ADB_STS_HighBeam_Left_Light : 22|2@1+ (1,0) [0|3] "-"  LOGBOX
 SG_ ADB_STS_LowBeam_Right_Light : 24|2@1+ (1,0) [0|3] "-"  LOGBOX
 SG_ ADB_STS_HighBeam_Right_Light : 26|2@1+ (1,0) [0|3] "-"  LOGBOX
 SG_ ADB_STS_ProjectorWarLeftLights : 28|2@1+ (1,0) [0|3] "-"  LOGBOX
 SG_ ADB_STS_Fuel_Circuit_Valve : 50|2@1+ (1,0) [0|3] "-"  LOGBOX
 SG_ ADB_STS_LockAlignRelValve : 38|2@1+ (1,0) [0|3] "-"  LOGBOX
 SG_ ADB_STS_DirectionRightLatLigh : 8|2@1+ (1,0) [0|3] "-"  LOGBOX
 SG_ ADB_STS_DirectionLeftLatLight : 44|2@1+ (1,0) [0|3] "-"  LOGBOX
 SG_ ADB_STS_DirectionRightFrontLight : 32|2@1+ (1,0) [0|3] "-"  LOGBOX
 SG_ ADB_STS_DirectionLeftFrontLight : 34|2@1+ (1,0) [0|3] "-"  LOGBOX
 SG_ ADB_STS_MarkerFrontleftLights : 40|2@1+ (1,0) [0|3] "-"  LOGBOX
 SG_ ADB_STS_MarkerFrontRightLights : 42|2@1+ (1,0) [0|3] "-"  LOGBOX
 SG_ ADB_STS_Dust_Extraction_Fan : 48|2@1+ (1,0) [0|3] "-"  LOGBOX
 SG_ ADB_STS_Engine_Bay_Bilge_Pump : 52|2@1+ (1,0) [0|3] "-"  LOGBOX
 SG_ ADB_STS_Fuel_Prefilter_Heater : 54|2@1+ (1,0) [0|3] "-"  LOGBOX

BO_ 2558730634 ADB_RUC2BC_DIG: 8 RUC
 SG_ ADB_IN_DIG_Cmd_K15 : 36|2@1+ (1,0) [0|3] "-"  LOGBOX,BC
 SG_ ADB_IN_DIG_Cmd_NBC : 26|2@1+ (1,0) [0|3] "-"  LOGBOX,BC
 SG_ ADB_IN_DIG_DriverHatchSw2 : 16|2@1+ (1,0) [0|3] "-"  SVS,LOGBOX,BC
 SG_ ADB_IN_DIG_DirectionLightsSwitch : 20|2@1+ (1,0) [0|3] "-"  LOGBOX,BC
 SG_ ADB_IN_DIG_HighBeamLightsSw : 22|2@1+ (1,0) [0|3] "-"  LOGBOX,BC
 SG_ ADB_IN_DIG_Fire_Ventilation : 24|2@1+ (1,0) [0|3] "-"  LOGBOX,BC
 SG_ ADB_IN_DIG_PneumaticParkBrakeSw : 28|2@1+ (1,0) [0|3] "-"  LOGBOX,BC
 SG_ ADB_IN_DIG_Engine_Start_Button : 34|2@1+ (1,0) [0|3] "-"  SVS,LOGBOX,BC
 SG_ ADB_IN_DIG_Starter_Override : 18|2@1+ (1,0) [0|3] "-"  LOGBOX,BC
 SG_ ADB_IN_DIG_Horn_Switch : 38|2@1+ (1,0) [0|3] "-"  LOGBOX,BC
 SG_ ADB_IN_DIG_Front_Camera_Washer : 40|2@1+ (1,0) [0|3] "-"  LOGBOX,BC
 SG_ ADB_IN_DIG_Central_Camera_Washer : 42|2@1+ (1,0) [0|3] "-"  LOGBOX,BC
 SG_ ADB_IN_DIG_Lateral_Camera_Washer : 44|2@1+ (1,0) [0|3] "-"  LOGBOX,BC
 SG_ ADB_BLACKOUT_GND_RUC : 8|2@1+ (1,0) [0|3] "-"  LOGBOX,BC

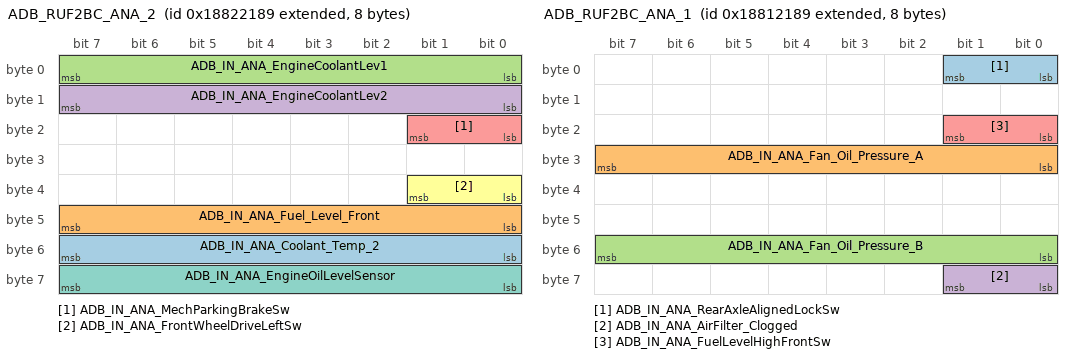
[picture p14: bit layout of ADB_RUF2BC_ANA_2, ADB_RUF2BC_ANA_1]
BO_ 2558665097 ADB_RUF2BC_ANA_2: 8 RUF
 SG_ ADB_IN_ANA_Coolant_Temp_2 : 48|8@1+ (4,0) [0|1000] "ohm"  LOGBOX,BC
 SG_ ADB_IN_ANA_Fuel_Level_Front : 40|8@1+ (4,0) [0|1000] "ohm"  LOGBOX,BC
 SG_ ADB_IN_ANA_EngineCoolantLev1 : 0|8@1+ (1,0) [0|255] "-"  LOGBOX,BC
 SG_ ADB_IN_ANA_EngineCoolantLev2 : 8|8@1+ (1,0) [0|255] "-"  LOGBOX,BC
 SG_ ADB_IN_ANA_MechParkingBrakeSw : 16|2@1+ (1,0) [0|3] "-"  LOGBOX,BC
 SG_ ADB_IN_ANA_FrontWheelDriveLeftSw : 32|2@1+ (1,0) [0|3] "-"  LOGBOX,BC
 SG_ ADB_IN_ANA_EngineOilLevelSensor : 56|8@1+ (2,0) [0|500] "mV"  LOGBOX,BC

BO_ 2558599561 ADB_RUF2BC_ANA_1: 8 RUF
 SG_ ADB_IN_ANA_RearAxleAlignedLockSw : 0|2@1+ (1,0) [0|3] "-"  LOGBOX,BC
 SG_ ADB_IN_ANA_Fan_Oil_Pressure_A : 24|8@1+ (20,0) [0|5000] "mV"  LOGBOX,BC
 SG_ ADB_IN_ANA_Fan_Oil_Pressure_B : 48|8@1+ (20,0) [0|5000] "mV"  LOGBOX,BC
 SG_ ADB_IN_ANA_AirFilter_Clogged : 56|2@1+ (1,0) [0|3] "-"  LOGBOX,BC
 SG_ ADB_IN_ANA_FuelLevelHighFrontSw : 16|2@1+ (1,0) [0|3] "-"  LOGBOX,BC

BO_ 2558626081 ADB_BC2RUF_CMD_2: 8 BC
 SG_ ADB_CMD_Ventilation_Fw_fan_Valve : 8|8@1+ (0.4,0) [0|100] "%"  LOGBOX,RUF
 SG_ ADB_CMD_AC_Compressor_Clutch : 16|2@1+ (1,0) [0|3] "-"  LOGBOX,RUF
 SG_ ADB_CMD_Air_Dryer : 18|2@1+ (1,0) [0|3] "-"  LOGBOX,RUF
 SG_ ADB_CMD_Vacuum_pump_Valve : 40|2@1+ (1,0) [0|3] "-"  LOGBOX,RUF
 SG_ ADB_CMD_Horn : 24|2@1+ (1,0) [0|3] "-"  LOGBOX,RUF
 SG_ ADB_CMD_Camera_Washer_Pump_Front : 26|2@1+ (1,0) [0|3] "-"  LOGBOX,RUF
 SG_ ADB_CMD_EngAreaHeaterWaterValve : 38|2@1+ (1,0) [0|3] "-"  LOGBOX,RUF
 SG_ ADB_CMD_CrewAreaHeaterWaterValve : 36|2@1+ (1,0) [0|3] "-"  LOGBOX,RUF
 SG_ ADB_CMD_MarkerFrontWarLeftLights : 32|2@1+ (1,0) [0|3] "-"  LOGBOX,RUF
 SG_ ADB_CMD_MarkerFrontWarRLights : 34|2@1+ (1,0) [0|3] "-"  LOGBOX,RUF
 SG_ ADB_CMD_MechanicalPartsPresValve : 42|2@1+ (1,0) [0|3] "-"  LOGBOX,RUF
 SG_ ADB_CMD_Front_Wheel_Drive_Valve : 44|2@1+ (1,0) [0|3] "-"  LOGBOX,RUF
 SG_ ADB_CMD_Diff_Lock_Front_Valve : 46|2@1+ (1,0) [0|3] "-"  LOGBOX,RUF
 SG_ ADB_CMD_MechParking_Brake_Valve : 48|2@1+ (1,0) [0|3] "-"  LOGBOX,RUF
 SG_ ADB_CMD_HotWireStart_RUF : 56|2@1+ (1,0) [0|3] "-"  LOGBOX,RUF
 SG_ ADB_CMD_CentralCameraPowSup : 20|2@1+ (1,0) [0|3] "-"  LOGBOX,RUF
 SG_ ADB_CMD_FrontCamerasPowSup : 22|2@1+ (1,0) [0|3] "-"  LOGBOX,RUF

BO_ 2558560545 ADB_BC2RUF_CMD_1: 8 BC
 SG_ ADB_CMD_SteeringValve : 0|8@1+ (1,0) [0|3] "-"  LOGBOX,RUF
 SG_ ADB_CMD_Front_Fuel_Pump_1 : 16|2@1+ (1,0) [0|3] "-"  LOGBOX,RUF
 SG_ ADB_CMD_Front_Fuel_Pump_2 : 18|2@1+ (1,0) [0|3] "-"  LOGBOX,RUF
 SG_ ADB_CMD_LowBeam_Left_Light : 20|2@1+ (1,0) [0|3] "-"  LOGBOX,RUF
 SG_ ADB_CMD_HighBeam_Left_Light : 22|2@1+ (1,0) [0|3] "-"  LOGBOX,RUF
 SG_ ADB_CMD_LowBeam_Right_Light : 24|2@1+ (1,0) [0|3] "-"  LOGBOX,RUF
 SG_ ADB_CMD_HighBeam_Right_Light : 26|2@1+ (1,0) [0|3] "-"  LOGBOX,RUF
 SG_ ADB_CMD_ProjectorWarLights : 28|2@1+ (1,0) [0|3] "-"  LOGBOX,RUF
 SG_ ADB_CMD_Fuel_Circuit_Valve : 50|2@1+ (1,0) [0|3] "-"  LOGBOX,RUF
 SG_ ADB_CMD_LockAlignRelValve : 38|2@1+ (1,0) [0|3] "-"  LOGBOX,RUF
 SG_ ADB_CMD_DirectionRightLatLigh : 8|8@1+ (1,0) [0|3] "-"  LOGBOX,RUF
 SG_ ADB_CMD_DirectionLeftLatLight : 44|2@1+ (1,0) [0|3] "-"  LOGBOX,RUF
 SG_ ADB_CMD_DirectionRightFrontLight : 32|2@1+ (1,0) [0|3] "-"  LOGBOX,RUF
 SG_ ADB_CMD_DirectionLeftFrontLight : 34|2@1+ (1,0) [0|3] "-"  LOGBOX,RUF
 SG_ ADB_CMD_MarkerFrontLeftLights : 40|2@1+ (1,0) [0|3] "-"  LOGBOX,RUF
 SG_ ADB_CMD_MarkerFrontRightLights : 42|2@1+ (1,0) [0|3] "-"  LOGBOX,RUF
 SG_ ADB_CMD_Dust_Extraction_Fan : 48|2@1+ (1,0) [0|3] "-"  LOGBOX,RUF
 SG_ ADB_CMD_Engine_Bay_Bilge_Pump : 52|2@1+ (1,0) [0|3] "-"  LOGBOX,RUF
 SG_ ADB_CMD_Fuel_Prefilter_Heater : 54|2@1+ (1,0) [0|3] "-"  LOGBOX,RUF

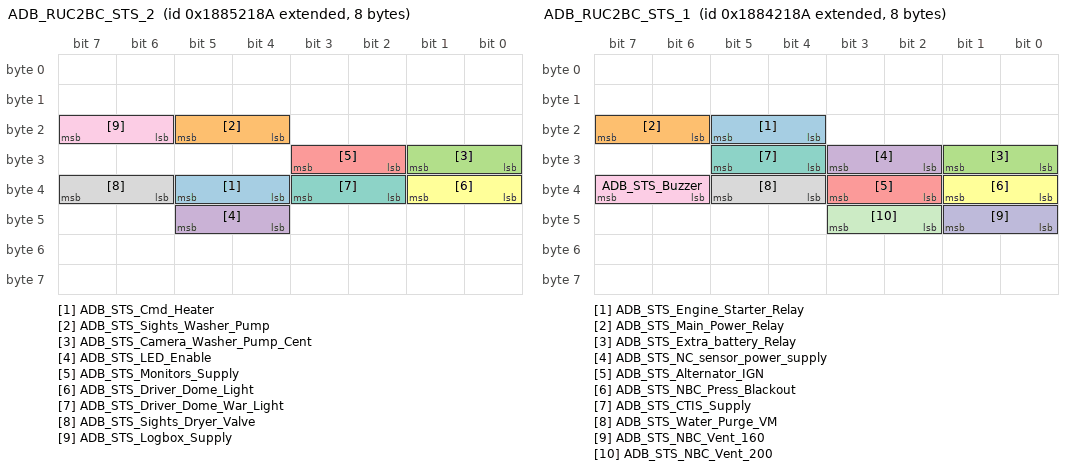
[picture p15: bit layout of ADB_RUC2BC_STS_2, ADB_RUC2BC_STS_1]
BO_ 2558861706 ADB_RUC2BC_STS_2: 8 RUC
 SG_ ADB_STS_Cmd_Heater : 36|2@1+ (1,0) [0|3] "-"  LOGBOX
 SG_ ADB_STS_Sights_Washer_Pump : 20|2@1+ (1,0) [0|3] "-"  LOGBOX
 SG_ ADB_STS_Camera_Washer_Pump_Cent : 24|2@1+ (1,0) [0|3] "-"  LOGBOX
 SG_ ADB_STS_LED_Enable : 44|2@1+ (1,0) [0|3] "-"  LOGBOX
 SG_ ADB_STS_Monitors_Supply : 26|2@1+ (1,0) [0|3] "-"  LOGBOX
 SG_ ADB_STS_Driver_Dome_Light : 32|2@1+ (1,0) [0|3] "-"  LOGBOX
 SG_ ADB_STS_Driver_Dome_War_Light : 34|2@1+ (1,0) [0|3] "-"  LOGBOX
 SG_ ADB_STS_Sights_Dryer_Valve : 38|2@1+ (1,0) [0|3] "-"  LOGBOX
 SG_ ADB_STS_Logbox_Supply : 22|2@1+ (1,0) [0|3] "-"  LOGBOX

BO_ 2558796170 ADB_RUC2BC_STS_1: 8 RUC
 SG_ ADB_STS_Engine_Starter_Relay : 20|2@1+ (1,0) [0|3] "-"  LOGBOX
 SG_ ADB_STS_Main_Power_Relay : 22|2@1+ (1,0) [0|3] "-"  LOGBOX
 SG_ ADB_STS_Extra_battery_Relay : 24|2@1+ (1,0) [0|3] "-"  LOGBOX
 SG_ ADB_STS_NC_sensor_power_supply : 26|2@1+ (1,0) [0|3] "-"  LOGBOX
 SG_ ADB_STS_Alternator_IGN : 34|2@1+ (1,0) [0|3] "-"  LOGBOX
 SG_ ADB_STS_NBC_Press_Blackout : 32|2@1+ (1,0) [0|3] "-"  LOGBOX
 SG_ ADB_STS_CTIS_Supply : 28|2@1+ (1,0) [0|3] "-"  LOGBOX
 SG_ ADB_STS_Water_Purge_VM : 36|2@1+ (1,0) [0|3] "-"  LOGBOX
 SG_ ADB_STS_Buzzer : 38|2@1+ (1,0) [0|3] "-"  LOGBOX
 SG_ ADB_STS_NBC_Vent_160 : 40|2@1+ (1,0) [0|3] "-"  LOGBOX
 SG_ ADB_STS_NBC_Vent_200 : 42|2@1+ (1,0) [0|3] "-"  LOGBOX

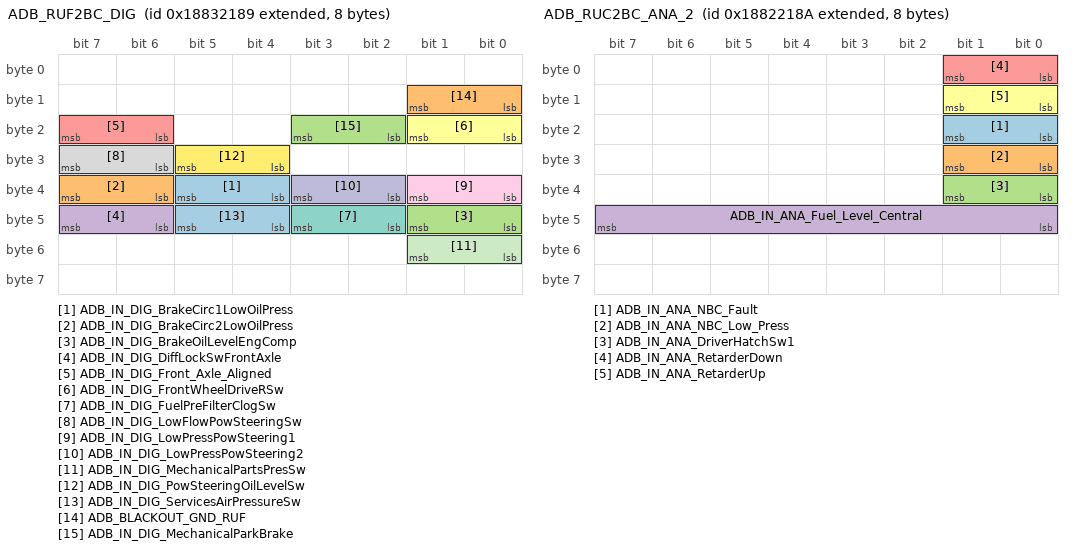
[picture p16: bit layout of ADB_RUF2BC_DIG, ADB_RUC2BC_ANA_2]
BO_ 2558730633 ADB_RUF2BC_DIG: 8 RUF
 SG_ ADB_IN_DIG_BrakeCirc1LowOilPress : 36|2@1+ (1,0) [0|3] "-"  LOGBOX,BC
 SG_ ADB_IN_DIG_BrakeCirc2LowOilPress : 38|2@1+ (1,0) [0|3] "-"  LOGBOX,BC
 SG_ ADB_IN_DIG_BrakeOilLevelEngComp : 40|2@1+ (1,0) [0|3] "-"  LOGBOX,BC
 SG_ ADB_IN_DIG_DiffLockSwFrontAxle : 46|2@1+ (1,0) [0|3] "-"  LOGBOX,BC
 SG_ ADB_IN_DIG_Front_Axle_Aligned : 22|2@1+ (1,0) [0|3] "-"  LOGBOX,BC
 SG_ ADB_IN_DIG_FrontWheelDriveRSw : 16|2@1+ (1,0) [0|3] "-"  LOGBOX,BC
 SG_ ADB_IN_DIG_FuelPreFilterClogSw : 42|2@1+ (1,0) [0|3] "-"  LOGBOX,BC
 SG_ ADB_IN_DIG_LowFlowPowSteeringSw : 30|2@1+ (1,0) [0|3] "-"  LOGBOX,BC
 SG_ ADB_IN_DIG_LowPressPowSteering1 : 32|2@1+ (1,0) [0|3] "-"  LOGBOX,BC
 SG_ ADB_IN_DIG_LowPressPowSteering2 : 34|2@1+ (1,0) [0|3] "-"  LOGBOX,BC
 SG_ ADB_IN_DIG_MechanicalPartsPresSw : 48|2@1+ (1,0) [0|3] "-"  LOGBOX,BC
 SG_ ADB_IN_DIG_PowSteeringOilLevelSw : 28|2@1+ (1,0) [0|3] "-"  LOGBOX,BC
 SG_ ADB_IN_DIG_ServicesAirPressureSw : 44|2@1+ (1,0) [0|3] "-"  LOGBOX,BC
 SG_ ADB_BLACKOUT_GND_RUF : 8|2@1+ (1,0) [0|3] "-"  LOGBOX,BC
 SG_ ADB_IN_DIG_MechanicalParkBrake : 18|2@1+ (1,0) [0|3] "-"  LOGBOX,BC

BO_ 2558665098 ADB_RUC2BC_ANA_2: 8 RUC
 SG_ ADB_IN_ANA_NBC_Fault : 16|2@1+ (1,0) [0|3] "-"  LOGBOX,BC
 SG_ ADB_IN_ANA_NBC_Low_Press : 24|2@1+ (1,0) [0|3] "-"  LOGBOX,BC
 SG_ ADB_IN_ANA_DriverHatchSw1 : 32|2@1+ (1,0) [0|3] "-"  SVS,LOGBOX,BC
 SG_ ADB_IN_ANA_Fuel_Level_Central : 40|8@1+ (4,0) [0|1000] "ohm"  LOGBOX,BC
 SG_ ADB_IN_ANA_RetarderDown : 0|2@1+ (1,0) [0|3] "-"  LOGBOX,BC
 SG_ ADB_IN_ANA_RetarderUp : 8|2@1+ (1,0) [0|3] "-"  LOGBOX,BC

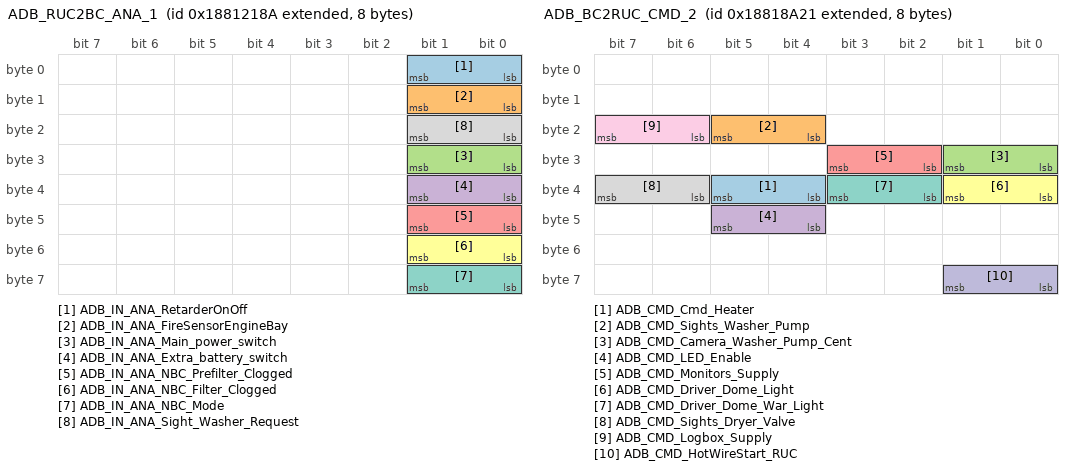
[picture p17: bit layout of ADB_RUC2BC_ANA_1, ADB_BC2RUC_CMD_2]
BO_ 2558599562 ADB_RUC2BC_ANA_1: 8 RUC
 SG_ ADB_IN_ANA_RetarderOnOff : 0|2@1+ (1,0) [0|3] "-"  LOGBOX,BC
 SG_ ADB_IN_ANA_FireSensorEngineBay : 8|2@1+ (1,0) [0|3] "-"  LOGBOX,BC
 SG_ ADB_IN_ANA_Main_power_switch : 24|2@1+ (1,0) [0|3] "-"  SVS,LOGBOX,BC
 SG_ ADB_IN_ANA_Extra_battery_switch : 32|2@1+ (1,0) [0|3] "-"  SVS,LOGBOX,BC
 SG_ ADB_IN_ANA_NBC_Prefilter_Clogged : 40|2@1+ (1,0) [0|3] "-"  LOGBOX,BC
 SG_ ADB_IN_ANA_NBC_Filter_Clogged : 48|2@1+ (1,0) [0|3] "-"  LOGBOX,BC
 SG_ ADB_IN_ANA_NBC_Mode : 56|2@1+ (1,0) [0|3] "-"  LOGBOX,BC
 SG_ ADB_IN_ANA_Sight_Washer_Request : 16|2@1+ (1,0) [0|3] "-"  LOGBOX,BC

BO_ 2558626337 ADB_BC2RUC_CMD_2: 8 BC
 SG_ ADB_CMD_Cmd_Heater : 36|2@1+ (1,0) [0|3] "-"  LOGBOX,RUC
 SG_ ADB_CMD_Sights_Washer_Pump : 20|2@1+ (1,0) [0|3] "-"  LOGBOX,RUC
 SG_ ADB_CMD_Camera_Washer_Pump_Cent : 24|2@1+ (1,0) [0|3] "-"  LOGBOX,RUC
 SG_ ADB_CMD_LED_Enable : 44|2@1+ (1,0) [0|3] "-"  LOGBOX,RUC
 SG_ ADB_CMD_Monitors_Supply : 26|2@1+ (1,0) [0|3] "-"  LOGBOX,RUC
 SG_ ADB_CMD_Driver_Dome_Light : 32|2@1+ (1,0) [0|3] "-"  LOGBOX,RUC
 SG_ ADB_CMD_Driver_Dome_War_Light : 34|2@1+ (1,0) [0|3] "-"  LOGBOX,RUC
 SG_ ADB_CMD_Sights_Dryer_Valve : 38|2@1+ (1,0) [0|3] "-"  LOGBOX,RUC
 SG_ ADB_CMD_Logbox_Supply : 22|2@1+ (1,0) [0|3] "-"  LOGBOX,RUC
 SG_ ADB_CMD_HotWireStart_RUC : 56|2@1+ (1,0) [0|3] "-"  LOGBOX,RUC

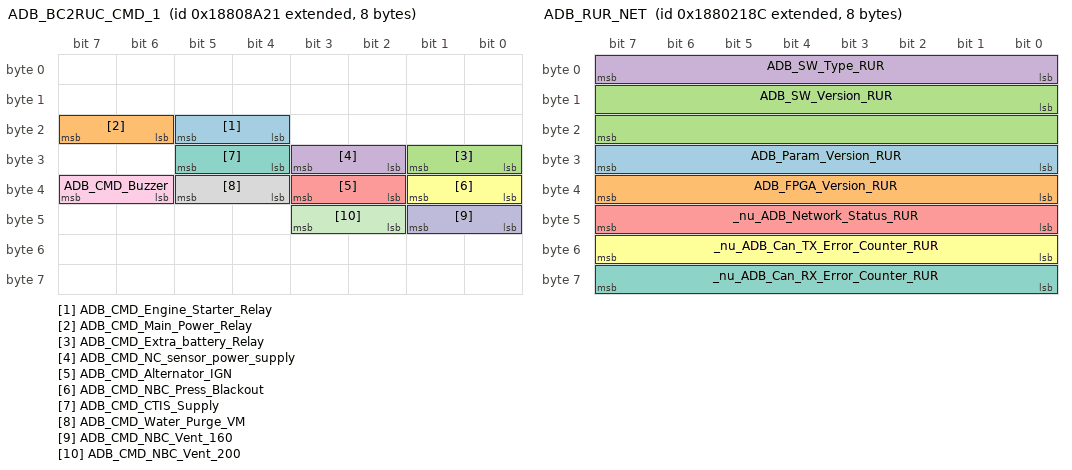
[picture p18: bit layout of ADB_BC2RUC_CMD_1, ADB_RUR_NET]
BO_ 2558560801 ADB_BC2RUC_CMD_1: 8 BC
 SG_ ADB_CMD_Engine_Starter_Relay : 20|2@1+ (1,0) [0|3] "-"  LOGBOX,RUC
 SG_ ADB_CMD_Main_Power_Relay : 22|2@1+ (1,0) [0|3] "-"  LOGBOX,RUC
 SG_ ADB_CMD_Extra_battery_Relay : 24|2@1+ (1,0) [0|3] "-"  LOGBOX,RUC
 SG_ ADB_CMD_NC_sensor_power_supply : 26|2@1+ (1,0) [0|3] "-"  LOGBOX,RUC
 SG_ ADB_CMD_Alternator_IGN : 34|2@1+ (1,0) [0|3] "-"  LOGBOX,RUC
 SG_ ADB_CMD_NBC_Press_Blackout : 32|2@1+ (1,0) [0|3] "-"  LOGBOX,RUC
 SG_ ADB_CMD_CTIS_Supply : 28|2@1+ (1,0) [0|3] "-"  LOGBOX,RUC
 SG_ ADB_CMD_Water_Purge_VM : 36|2@1+ (1,0) [0|3] "-"  LOGBOX,RUC
 SG_ ADB_CMD_Buzzer : 38|2@1+ (1,0) [0|3] "-"  LOGBOX,RUC
 SG_ ADB_CMD_NBC_Vent_160 : 40|2@1+ (1,0) [0|3] "-"  LOGBOX,RUC
 SG_ ADB_CMD_NBC_Vent_200 : 42|2@1+ (1,0) [0|3] "-"  LOGBOX,RUC

BO_ 2558534028 ADB_RUR_NET: 8 RUR
 SG_ ADB_Param_Version_RUR : 24|8@1+ (1,0) [0|255] "-"  LOGBOX,BC
 SG_ ADB_FPGA_Version_RUR : 32|8@1+ (1,0) [0|255] "-"  LOGBOX,BC
 SG_ ADB_SW_Version_RUR : 8|16@1+ (1,0) [0|65535] "-"  LOGBOX,BC
 SG_ ADB_SW_Type_RUR : 0|8@1+ (1,0) [0|255] "-"  LOGBOX,BC
 SG_ _nu_ADB_Network_Status_RUR : 40|8@1+ (1,0) [0|3] "-"  LOGBOX,BC
 SG_ _nu_ADB_Can_TX_Error_Counter_RUR : 48|8@1+ (1,0) [0|255] "-"  LOGBOX,BC
 SG_ _nu_ADB_Can_RX_Error_Counter_RUR : 56|8@1+ (1,0) [0|255] "-"  LOGBOX,BC

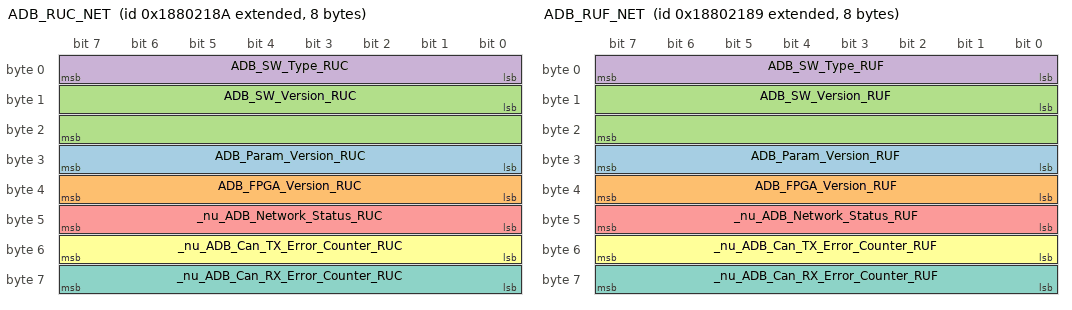
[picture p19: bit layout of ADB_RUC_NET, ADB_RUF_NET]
BO_ 2558534026 ADB_RUC_NET: 8 RUC
 SG_ ADB_Param_Version_RUC : 24|8@1+ (1,0) [0|255] "-"  LOGBOX,BC
 SG_ ADB_FPGA_Version_RUC : 32|8@1+ (1,0) [0|255] "-"  LOGBOX,BC
 SG_ ADB_SW_Version_RUC : 8|16@1+ (1,0) [0|65535] "-"  LOGBOX,BC
 SG_ ADB_SW_Type_RUC : 0|8@1+ (1,0) [0|255] "-"  LOGBOX,BC
 SG_ _nu_ADB_Network_Status_RUC : 40|8@1+ (1,0) [0|3] "-"  LOGBOX,BC
 SG_ _nu_ADB_Can_TX_Error_Counter_RUC : 48|8@1+ (1,0) [0|255] "-"  LOGBOX,BC
 SG_ _nu_ADB_Can_RX_Error_Counter_RUC : 56|8@1+ (1,0) [0|255] "-"  LOGBOX,BC

BO_ 2558534025 ADB_RUF_NET: 8 RUF
 SG_ ADB_Param_Version_RUF : 24|8@1+ (1,0) [0|255] "-"  LOGBOX,BC
 SG_ ADB_FPGA_Version_RUF : 32|8@1+ (1,0) [0|255] "-"  LOGBOX,BC
 SG_ ADB_SW_Version_RUF : 8|16@1+ (1,0) [0|65535] "-"  LOGBOX,BC
 SG_ ADB_SW_Type_RUF : 0|8@1+ (1,0) [0|255] "-"  LOGBOX,BC
 SG_ _nu_ADB_Network_Status_RUF : 40|8@1+ (1,0) [0|3] "-"  LOGBOX,BC
 SG_ _nu_ADB_Can_TX_Error_Counter_RUF : 48|8@1+ (1,0) [0|255] "-"  LOGBOX,BC
 SG_ _nu_ADB_Can_RX_Error_Counter_RUF : 56|8@1+ (1,0) [0|255] "-"  LOGBOX,BC

CM_ BO_ 2566850046 "This PGN reports a summary of the the operating parameters of the full battery: serial number, state of charge, state of health, temperature alarm, voltage alarm for the battery.";
CM_ SG_ 2566850046 BMS0_ADB_BatSumS_serial_number "This parameter contains the manufactured serial number of the battery. The lowest 21 bits of this 24 bit serial number are also used in the J1939 NAME – see 2.1.";
CM_ SG_ 2566850046 BMS0_ADB_BatSumS_Reserved_01 "Reserved";
CM_ SG_ 2566850046 BMS0_ADB_BatSumS_State_of_Charge "This parameter contains the ratio of the remaining capacity of the battery to the full capacity expressed as a percentage.";
CM_ SG_ 2566850046 BMS0_ADB_BatSumS_State_of_Health "This parameter contains a value relating to the state of health of the battery based on defined thresholds of the ratio of full capacity to design capacity.";
CM_ SG_ 2566850046 BMS0_ADB_BatSumS_Temp_Alarm "This parameter contains the temperature alarm, based on the maximum battery temperature.
0x00: No fault;
0x01: Low Temperature Alarm
0x02: High Temperature Alarm
0x03: Wrong Temperature Alarm";
CM_ SG_ 2566850046 BMS0_ADB_BatSumS_DischargeDis "This parameter indicates when the battery is not able to be discharged.
0x00: Discharge Enable;
0x01: Discharge Disable";
CM_ SG_ 2566850046 BMS0_ADB_BatSumS_ChargingDisable "This parameter indicates when the battery is not able to be discharged.
0x00: Charging Enable;
0x01: Charging Disable";
CM_ SG_ 2566850046 BMS0_ADB_BatSumS_HeaterEnabled "This parameter indicates when the heater is enabled.
0x00: Heater Disabled;
0x01: Heater Enabled";
CM_ SG_ 2566850046 BMS0_ADB_BatSumS_BypassEnabled "This parameter indicates when the bypass is enabled.
0x00: Bypass Disabled;
0x01: Bypass Enabled";
CM_ SG_ 2566850046 BMS0_ADB_BatSumS_Voltage_Alarm "This parameter indicates an over voltage condition in one or more modules.
0x00: No fault;
0x01:Over Voltage Alarm";
CM_ SG_ 2566850046 BMS0_ADB_BatSumS_Reserved_04 "Reserved";
CM_ SG_ 2566850046 BMS0_ADB_BatSumS_Reserved_05 "Reserved";
CM_ SG_ 2566850046 BMS0_ADB_BatSumS_Reserved_06 "Reserved";
CM_ SG_ 2566850046 BMS0_ADB_BatSumS_Reserved_07 "Reserved";
CM_ SG_ 2566850046 BMS0_ADB_BatSumS_Reserved_08 "Reserved";
CM_ SG_ 2566850046 BMS0_ADB_BatSumS_Reserved_09 "Reserved";
CM_ SG_ 2566850046 BMS0_ADB_BatSumS_Reserved_10 "Reserved";
CM_ SG_ 2566850046 BMS0_ADB_BatSumS_Reserved_11 "Reserved";
CM_ BO_ 2566849790 "Used for debugging purposes.";
CM_ SG_ 2566849790 BMS0_ADB_Debug_0 "Used for debugging purpose - byte 0";
CM_ SG_ 2566849790 BMS0_ADB_Debug_1 "Used for debugging purpose - byte 1";
CM_ SG_ 2566849790 BMS0_ADB_Debug_2 "Used for debugging purpose - byte 2";
CM_ SG_ 2566849790 BMS0_ADB_Debug_3 "Used for debugging purpose - byte 3";
CM_ SG_ 2566849790 BMS0_ADB_Debug_4 "Used for debugging purpose - byte 4";
CM_ SG_ 2566849790 BMS0_ADB_Debug_5 "Used for debugging purpose - byte 5";
CM_ SG_ 2566849790 BMS0_ADB_Debug_6 "Used for debugging purpose - byte 6";
CM_ SG_ 2566849790 BMS0_ADB_Debug_7 "Used for debugging purpose - byte 7";
CM_ BO_ 2566853374 "This PGN reports the remaining module capacity, the expected full module capacity and the designed module capacity for module 3.";
CM_ SG_ 2566853374 BMS0_ADB_M1_Remaining_capacity "This parameter contains the remaining capacity of the battery.";
CM_ SG_ 2566853374 BMS0_ADB_M1_Full_capacity "This parameter contains the full capacity of the battery.";
CM_ SG_ 2566853374 BMS0_ADB_M1_Design_capacity "This parameter contains the design capacity of the battery.";
CM_ SG_ 2566853374 BMS0_ADB_M1_Reserved_Cap "Reserved";
CM_ BO_ 2566853118 "This PGN reports the remaining module capacity, the expected full module capacity and the designed module capacity for module 2.";
CM_ SG_ 2566853118 BMS0_ADB_M2_Remaining_capacity "This parameter contains the remaining capacity of the battery.";
CM_ SG_ 2566853118 BMS0_ADB_M2_Full_capacity "This parameter contains the full capacity of the battery.";
CM_ SG_ 2566853118 BMS0_ADB_M2_Design_capacity "This parameter contains the design capacity of the battery.";
CM_ SG_ 2566853118 BMS0_ADB_M2_Reserved_Cap "Reserved";
CM_ BO_ 2566852862 "This PGN reports the remaining module capacity, the expected full module capacity and the designed module capacity for module 1.";
CM_ SG_ 2566852862 BMS0_ADB_M3_Remaining_capacity "This parameter contains the remaining capacity of the battery.";
CM_ SG_ 2566852862 BMS0_ADB_M3_Full_capacity "This parameter contains the full capacity of the battery.";
CM_ SG_ 2566852862 BMS0_ADB_M3_Design_capacity "This parameter contains the design capacity of the battery.";
CM_ SG_ 2566852862 BMS0_ADB_M3_Reserved_Cap "Reserved";
CM_ BO_ 2566862078 "This PGN reports the total number of software-related events that have occurred during the life of the battery.";
CM_ SG_ 2566862078 BMS0_ADB_WatchdogReset_events "This parameter contains a count of the number times the watchdog has reset the firmware due to an internal lock-up.
Data Range: 0 – 64255. A value of 64255 indicates 64255 events or more.";
CM_ SG_ 2566862078 BMS0_ADB_StackOverflowReset_even "This parameter contains a count of the number times the firmware has been reset due to a stack-overflow.
Data Range: 0 – 64255. A value of 64255 indicates 64255 events or more.";
CM_ SG_ 2566862078 BMS0_ADB_CommandedReset_events "This parameter contains a count of the number times the firmware has been reset by a CAN, USB or status button command.
Data Range: 0 – 64255. A value of 64255 indicates 64255 events or more.";
CM_ SG_ 2566862078 BMS0_ADB_IllegalInstructionReset "This parameter contains a count of the number times the firmware has been hard-reset using the status button.
Data Range: 0 – 64255. A value of 64255 indicates 64255 events or more.";
CM_ BO_ 2566861822 "This PGN reports the total number of voltage-related events that have occurred during the life of the battery.";
CM_ SG_ 2566861822 BMS0_ADB_OverVoltage_events "This parameter contains a count of the number of times an over-voltage event has occurred.";
CM_ SG_ 2566861822 BMS0_ADB_UnderVoltage_events "This parameter contains a count of the number of times an under-voltage event has occurred.";
CM_ BO_ 2566861566 "This PGN reports the total number of current and temperature-related events that have occurred during the life of the battery.";
CM_ SG_ 2566861566 BMS0_ADB_ShortCircuit_events "This parameter contains a count of the number of times the battery has been short-circuited.";
CM_ SG_ 2566861566 BMS0_ADB_CurrentOverload_events "This parameter contains a count of the number of times the battery has been overloaded.";
CM_ SG_ 2566861566 BMS0_ADB_OverCurrent_Charge_ev "This parameter contains a count of the number of times the battery’s maximum charge current has been exceeded.";
CM_ SG_ 2566861566 BMS0_ADB_OverTemperature_ev "This parameter contains a count of the number of times the battery’s maximum temperature has been exceeded.";
CM_ BO_ 2566861310 "This PGN reports on the maximum and minimum battery voltages and currents measured during the life of the battery.";
CM_ SG_ 2566861310 BMS0_ADB_MaximumVoltage "This parameter contains the maximum voltage ever measured across the battery cells.";
CM_ SG_ 2566861310 BMS0_ADB_MinimumVoltage "This parameter contains the minimum voltage ever measured across the battery cells.";
CM_ SG_ 2566861310 BMS0_ADB_MAX_Discharge_Current "This parameter contains the maximum discharge current ever measured on the battery.";
CM_ SG_ 2566861310 BMS0_ADB_MAX_Charge_Current "This parameter contains the maximum charge current ever measured on the battery.";
CM_ BO_ 2566861054 "This PGN reports on the maximum and minimum temperatures experienced during the life of the battery.";
CM_ SG_ 2566861054 BMS0_ADB_Maximum_Life_temp "This parameter contains the maximum temperature ever measured in the battery.";
CM_ SG_ 2566861054 BMS0_ADB_Minimum_Life_temp "This parameter contains the minimum temperature ever measured in the battery.";
CM_ SG_ 2566861054 BMS0_ADB_MAX_Charging_Temp "This parameter contains the maximum temperature ever measured while charging the battery.";
CM_ SG_ 2566861054 BMS0_ADB_MIN_Charging_Temp "This parameter contains the minimum temperature ever measured while charging the battery.";
CM_ BO_ 2566857470 "This PGN reports on the individual discharge switch temperatures within module 3 of the battery. The values are only valid when the discharge current exceeds 10A for the entire battery, at other times the values returned will be the J1939 unavailable value.";
CM_ SG_ 2566857470 BMS0_ADB_M3_Temperature_1 "This parameter contains the temperature of a discharge switch sensor.";
CM_ SG_ 2566857470 BMS0_ADB_M3_Temperature_2 "This parameter contains the temperature of a discharge switch sensor.";
CM_ SG_ 2566857470 BMS0_ADB_M3_Temperature_3 "This parameter contains the temperature of a discharge switch sensor.";
CM_ SG_ 2566857470 BMS0_ADB_M3_Reserved_Dis1 "Reserved";
CM_ SG_ 2566857470 BMS0_ADB_M3_Reserved_Dis2 "Reserved";
CM_ BO_ 2566857214 "This PGN reports on the individual discharge switch temperatures within module 2 of the battery. The values are only valid when the discharge current exceeds 10A for the entire battery, at other times the values returned will be the J1939 unavailable value.";
CM_ SG_ 2566857214 BMS0_ADB_M2_Temperature_1 "This parameter contains the temperature of a discharge switch sensor.";
CM_ SG_ 2566857214 BMS0_ADB_M2_Temperature_2 "This parameter contains the temperature of a discharge switch sensor.";
CM_ SG_ 2566857214 BMS0_ADB_M2_Temperature_3 "This parameter contains the temperature of a discharge switch sensor.";
CM_ SG_ 2566857214 BMS0_ADB_M2_Reserved_Dis1 "Reserved";
CM_ SG_ 2566857214 BMS0_ADB_M2_Reserved_Dis2 "Reserved";
CM_ BO_ 2566856958 "This PGN reports on the individual discharge switch temperatures within module 1 of the battery. The values are only valid when the discharge current exceeds 10A for the entire battery, at other times the values returned will be the J1939 unavailable value.";
CM_ SG_ 2566856958 BMS0_ADB_M1_Temperature_1 "This parameter contains the temperature of a discharge switch sensor.";
CM_ SG_ 2566856958 BMS0_ADB_M1_Temperature_2 "This parameter contains the temperature of a discharge switch sensor.";
CM_ SG_ 2566856958 BMS0_ADB_M1_Temperature_3 "This parameter contains the temperature of a discharge switch sensor.";
CM_ SG_ 2566856958 BMS0_ADB_M1_Reserved_Dis1 "Reserved";
CM_ SG_ 2566856958 BMS0_ADB_M1_Reserved_Dis2 "Reserved";
CM_ BO_ 2566855422 "This PGN reports on the individual temperatures measured within module 3 of the battery.";
CM_ SG_ 2566855422 BMS0_ADB_M3_FuelGauge1_Temp "This parameter contains the temperature measured by the module’s fuel gauge IC.";
CM_ SG_ 2566855422 BMS0_ADB_M3_Thermistor1_temp "This parameter contains the temperature measured by one of the module’s Thermistors.";
CM_ SG_ 2566855422 BMS0_ADB_M3_Thermistor2_temp "This parameter contains the temperature measured by one of the module’s Thermistors.";
CM_ SG_ 2566855422 BMS0_ADB_M3_FuelGauge2_Temp "This parameter contains the temperature measured by the module’s fuel gauge IC.";
CM_ BO_ 2566855166 "This PGN reports on the individual temperatures measured within module 2 of the battery.";
CM_ SG_ 2566855166 BMS0_ADB_M2_FuelGauge1_Temp "This parameter contains the temperature measured by the module’s fuel gauge IC.";
CM_ SG_ 2566855166 BMS0_ADB_M2_Thermistor1_temp "This parameter contains the temperature measured by one of the module’s Thermistors.";
CM_ SG_ 2566855166 BMS0_ADB_M2_Thermistor2_temp "This parameter contains the temperature measured by one of the module’s Thermistors.";
CM_ SG_ 2566855166 BMS0_ADB_M2_FuelGauge2_Temp "This parameter contains the temperature measured by the module’s fuel gauge IC.";
CM_ BO_ 2566854910 "This PGN reports on the individual temperatures measured within module 1 of the battery.";
CM_ SG_ 2566854910 BMS0_ADB_M1_FuelGauge1_Temp "This parameter contains the temperature measured by the module’s fuel gauge IC.";
CM_ SG_ 2566854910 BMS0_ADB_M1_Thermistor1_temp "This parameter contains the temperature measured by one of the module’s Thermistors.";
CM_ SG_ 2566854910 BMS0_ADB_M1_Thermistor2_temp "This parameter contains the temperature measured by one of the module’s Thermistors.";
CM_ SG_ 2566854910 BMS0_ADB_M1_FuelGauge2_Temp "This parameter contains the temperature measured by the module’s fuel gauge IC.";
CM_ BO_ 2566851326 "This PGN reports the operating parameters of module 3 within the battery: output voltage, average current (charge or discharge), the percentage state of charge, a state of health indication and the protection status of the module.";
CM_ SG_ 2566851326 BMS0_ADB_M3_Module_OUT_Voltage "This parameter contains the output voltage of the module.";
CM_ SG_ 2566851326 BMS0_ADB_M3_ModuleAverageCurrent "This parameter contains the charge (positive) or discharge (negative) current of the module averaged over 1 second.";
CM_ SG_ 2566851326 BMS0_ADB_M3_Module_StateOfCharge "This parameter contains the ratio of the remaining capacity of the module to the full capacity of the module expressed as a percentage.";
CM_ SG_ 2566851326 BMS0_ADB_M3_Module_StateOfHealth "This parameter contains a value relating to the state of health of the module based on defined thresholds of the ratio of full capacity to design capacity.";
CM_ SG_ 2566851326 BMS0_ADB_M3_DiscProtectTrigg "This parameter contains the current protection status of the module.
Discharge protection triggered";
CM_ SG_ 2566851326 BMS0_ADB_M3_ChargeProtectTrigg "This parameter contains the current protection status of the module.
Charge protection triggered";
CM_ SG_ 2566851326 BMS0_ADB_M3_ModulesMissingFailed "This parameter contains the current protection status of the module.
Modules missing/failed";
CM_ SG_ 2566851326 BMS0_ADB_M3_OverTemp_detect "This parameter contains the current protection status of the module.
Over-temperature detected";
CM_ SG_ 2566851326 BMS0_ADB_M3_UnderVoltage_detect "This parameter contains the current protection status of the module.
Under-voltage detected";
CM_ SG_ 2566851326 BMS0_ADB_M3_OverVoltage_detected "This parameter contains the current protection status of the module.
Over-voltage detected";
CM_ SG_ 2566851326 BMS0_ADB_M3_Overload_detected "This parameter contains the current protection status of the module.
Overload detected";
CM_ SG_ 2566851326 BMS0_ADB_M3_ShortCircuit_detect "This parameter contains the current protection status of the module.
Short circuit detected";
CM_ SG_ 2566851326 BMS0_ADB_M3_Module_BQ78350 "This parameter contains selected data from the BQ78350 status.
Each bit indicates a different alarm (bit 1 indicates extra 1, bit 2 indicates extra 2 …) where 0 indicates no fault and 1 indicates missing, failed or protection triggered";
CM_ BO_ 2566851070 "This PGN reports the operating parameters of module 2 within the battery: output voltage, average current (charge or discharge), the percentage state of charge, a state of health indication and the protection status of the module.";
CM_ SG_ 2566851070 BMS0_ADB_M2_Module_OUT_Voltage "This parameter contains the output voltage of the module.";
CM_ SG_ 2566851070 BMS0_ADB_M2_ModuleAverageCurrent "This parameter contains the charge (positive) or discharge (negative) current of the module averaged over 1 second.";
CM_ SG_ 2566851070 BMS0_ADB_M2_Module_StateOfCharge "This parameter contains the ratio of the remaining capacity of the module to the full capacity of the module expressed as a percentage.";
CM_ SG_ 2566851070 BMS0_ADB_M2_Module_StateOfHealth "This parameter contains a value relating to the state of health of the module based on defined thresholds of the ratio of full capacity to design capacity.";
CM_ SG_ 2566851070 BMS0_ADB_M2_DiscProtectTrigg "This parameter contains the current protection status of the module.
Discharge protection triggered";
CM_ SG_ 2566851070 BMS0_ADB_M2_ChargeProtectTrigg "This parameter contains the current protection status of the module.
Charge protection triggered";
CM_ SG_ 2566851070 BMS0_ADB_M2_ModulesMissingFailed "This parameter contains the current protection status of the module.
Modules missing/failed";
CM_ SG_ 2566851070 BMS0_ADB_M2_OverTemp_detect "This parameter contains the current protection status of the module.
Over-temperature detected";
CM_ SG_ 2566851070 BMS0_ADB_M2_UnderVoltage_detect "This parameter contains the current protection status of the module.
Under-voltage detected";
CM_ SG_ 2566851070 BMS0_ADB_M2_OverVoltage_detected "This parameter contains the current protection status of the module.
Over-voltage detected";
CM_ SG_ 2566851070 BMS0_ADB_M2_Overload_detected "This parameter contains the current protection status of the module.
Overload detected";
CM_ SG_ 2566851070 BMS0_ADB_M2_ShortCircuit_detect "This parameter contains the current protection status of the module.
Short circuit detected";
CM_ SG_ 2566851070 BMS0_ADB_M2_Module_BQ78350 "This parameter contains selected data from the BQ78350 status.
Each bit indicates a different alarm (bit 1 indicates extra 1, bit 2 indicates extra 2 …) where 0 indicates no fault and 1 indicates missing, failed or protection triggered";
CM_ BO_ 2566850814 "This PGN reports the operating parameters of module 1 within the battery: output voltage, average current (charge or discharge), the percentage state of charge, a state of health indication and the protection status of the module.";
CM_ SG_ 2566850814 BMS0_ADB_M1_Module_OUT_Voltage "This parameter contains the output voltage of the module.";
CM_ SG_ 2566850814 BMS0_ADB_M1_ModuleAverageCurrent "This parameter contains the charge (positive) or discharge (negative) current of the module averaged over 1 second.";
CM_ SG_ 2566850814 BMS0_ADB_M1_Module_StateOfCharge "This parameter contains the ratio of the remaining capacity of the module to the full capacity of the module expressed as a percentage.";
CM_ SG_ 2566850814 BMS0_ADB_M1_Module_StateOfHealth "This parameter contains a value relating to the state of health of the module based on defined thresholds of the ratio of full capacity to design capacity.";
CM_ SG_ 2566850814 BMS0_ADB_M1_DiscProtectTrigg "This parameter contains the current protection status of the module.
Discharge protection triggered";
CM_ SG_ 2566850814 BMS0_ADB_M1_ChargeProtectTrigg "This parameter contains the current protection status of the module.
Charge protection triggered";
CM_ SG_ 2566850814 BMS0_ADB_M1_ModulesMissingFailed "This parameter contains the current protection status of the module.
Modules missing/failed";
CM_ SG_ 2566850814 BMS0_ADB_M1_OverTemp_detect "This parameter contains the current protection status of the module.
Over-temperature detected";
CM_ SG_ 2566850814 BMS0_ADB_M1_UnderVoltage_detect "This parameter contains the current protection status of the module.
Under-voltage detected";
CM_ SG_ 2566850814 BMS0_ADB_M1_OverVoltage_detected "This parameter contains the current protection status of the module.
Over-voltage detected";
CM_ SG_ 2566850814 BMS0_ADB_M1_Overload_detected "This parameter contains the current protection status of the module.
Overload detected";
CM_ SG_ 2566850814 BMS0_ADB_M1_ShortCircuit_detect "This parameter contains the current protection status of the module.
Short circuit detected";
CM_ SG_ 2566850814 BMS0_ADB_M1_Module_BQ78350 "This parameter contains selected data from the BQ78350 status.
Each bit indicates a different alarm (bit 1 indicates extra 1, bit 2 indicates extra 2 …) where 0 indicates no fault and 1 indicates missing, failed or protection triggered";
CM_ BO_ 2566849534 "This PGN reports the battery’s serial and firmware version numbers.";
CM_ SG_ 2566849534 BMS0_ADB_Battery_serial_number "This parameter contains the manufactured serial number of the battery. The lowest 21 bits of this 24 bit serial number are also used in the J1939 NAME – see 2.1.";
CM_ SG_ 2566849534 BMS0_ADB_FirmwareVersionMajor "This parameter contains the major number of the firmware version, i.e. where the firmware has a version XX.YY.ZZZ it represents XX.";
CM_ SG_ 2566849534 BMS0_ADB_FirmwareVersionMinor "This parameter contains the major number of the firmware version, i.e. where the firmware has a version XX.YY.ZZZ it represents YY.";
CM_ SG_ 2566849534 BMS0_ADB_Firmware_Revision "This parameter contains the major number of the firmware version, i.e. where the firmware has a version XX.YY.ZZZ it represents ZZZ.";
CM_ BO_ 2566849278 "This PGN reports the battery temperature. The battery contains a number of temperature sensors which are summarised in this PGN by reporting the maximum, the minimum and the average of all the sensors.";
CM_ SG_ 2566849278 BMS0_ADB_Maximum_Temperature "This parameter contains the highest temperature currently measured within the battery.";
CM_ SG_ 2566849278 BMS0_ADB_Minimum_Temperature "This parameter contains the lowest temperature currently measured within the battery.";
CM_ SG_ 2566849278 BMS0_ADB_Average_Temperature "This parameter contains the average of all the temperatures currently measured within the battery.";
CM_ BO_ 2566849022 "This PGN reports the remaining battery capacity, the expected full battery capacity and the designed battery capacity. If the capacity falls below a defined percentage of the design capacity, the battery enters an alarm state and broadcasts this PGN within 100ms of the event and then repeatedly at 1000ms intervals until the capacity moves above the alarm threshold.";
CM_ SG_ 2566849022 BMS0_ADB_Remaining_capacity "This parameter contains the remaining capacity of the battery.";
CM_ SG_ 2566849022 BMS0_ADB_Full_capacity "This parameter contains the full capacity of the battery.";
CM_ SG_ 2566849022 BMS0_ADB_Design_capacity "This parameter contains the design capacity of the battery.";
CM_ SG_ 2566849022 BMS0_ADB_Overall_10_alarm "This parameter contains fields indicating which, if any, capacity alarm thresholds have been triggered.
Overall – less than 10% of design capacity remaining";
CM_ SG_ 2566849022 BMS0_ADB_Silent_Watch_20_alarm "This parameter contains fields indicating which, if any, capacity alarm thresholds have been triggered.
Silent watch – less than 20% silent watch threshold";
CM_ SG_ 2566849022 BMS0_ADB_EngStartCapacity_alarm "This parameter contains fields indicating which, if any, capacity alarm thresholds have been triggered.
Engine start – capacity below engine start threshold";
CM_ SG_ 2566849022 BMS0_ADB_10_Reserved_4 "Not used";
CM_ SG_ 2566849022 BMS0_ADB_10_Reserved_5 "Not used";
CM_ SG_ 2566849022 BMS0_ADB_10_Reserved_6 "Not used";
CM_ SG_ 2566849022 BMS0_ADB_10_Reserved_7 "Not used";
CM_ SG_ 2566849022 BMS0_ADB_10_Reserved_8 "Not used";
CM_ BO_ 2566848766 "This PGN reports the normal operating parameters of the battery: output voltage, average current (charge or discharge), the percentage state of charge and a state of health indication.
The PGN is broadcast at 1000ms intervals or can be requested.";
CM_ SG_ 2566848766 BMS0_ADB_Batt_OUT_Voltage "This parameter contains the output voltage of the battery.
It only specifies the voltage of the internal modules that are available for discharge: any module which is in over-temperature or under-voltage protection is not included in this figure because it has been internally disconnected.";
CM_ SG_ 2566848766 BMS0_ADB_Batt_Average_Current "This parameter contains the charge (positive) or discharge (negative) current of the battery averaged over 1 second.";
CM_ SG_ 2566848766 BMS0_ADB_Batt_StsOfCharge "This parameter contains the ratio of the remaining capacity of the battery to the full capacity expressed as a percentage.";
CM_ SG_ 2566848766 BMS0_ADB_Batt_StsOfHealth "This parameter contains a value relating to the state of health of the battery based on defined thresholds of the ratio of full capacity to design capacity.";
CM_ SG_ 2566848766 BMS0_ADB_Batt_PS8_discharge_prot "This parameter contains the current protection status of the battery.
Discharge protection triggered.";
CM_ SG_ 2566848766 BMS0_ADB_Batt_PS7_charge_prot "This parameter contains the current protection status of the battery.
Charge protection triggered.";
CM_ SG_ 2566848766 BMS0_ADB_Batt_PS6_mod_failed "This parameter contains the current protection status of the battery.
1 or more modules missing/failed.";
CM_ SG_ 2566848766 BMS0_ADB_Batt_PS5_over_temp "This parameter contains the current protection status of the battery.
Over-temperature detected.";
CM_ SG_ 2566848766 BMS0_ADB_Batt_PS4_under_voltage "This parameter contains the current protection status of the battery.
Under-voltage detected.";
CM_ SG_ 2566848766 BMS0_ADB_Batt_PS3_over_voltage "This parameter contains the current protection status of the battery.
Over-voltage detected.";
CM_ SG_ 2566848766 BMS0_ADB_Batt_PS2_overload "This parameter contains the current protection status of the battery.
Overload detected.";
CM_ SG_ 2566848766 BMS0_ADB_Batt_PS1_short_circuit "This parameter contains the current protection status of the battery.
Short circuit detected.";
CM_ SG_ 2566848766 BMS0_ADB_Batt_OS_8_sleep_mode "This parameter contains the status bits indicating the current state of the emergency load-dump, emergency override, heater and charger controls along with the master protection status bit.
Sleep mode pending (1 = sleep pending, 0 = awake)";
CM_ SG_ 2566848766 BMS0_ADB_Batt_OS_7_emerg_used "This parameter contains the status bits indicating the current state of the emergency load-dump, emergency override, heater and charger controls along with the master protection status bit.
Emergency override used (1= used, 0 = never used)";
CM_ SG_ 2566848766 BMS0_ADB_Batt_OS_6_emergency "This parameter contains the status bits indicating the current state of the emergency load-dump, emergency override, heater and charger controls along with the master protection status bit.
Emergency override (1 = active, 0 = inactive)";
CM_ SG_ 2566848766 BMS0_ADB_Batt_OS_45_charge_level "This parameter contains the status bits indicating the current state of the emergency load-dump, emergency override, heater and charger controls along with the master protection status bit.
Charge level (0 = off, 1 = 25%, 2 = 50%, 3 = full)";
CM_ SG_ 2566848766 BMS0_ADB_Batt_OS_3_charge_cont "This parameter contains the status bits indicating the current state of the emergency load-dump, emergency override, heater and charger controls along with the master protection status bit.
Charge control (1 = on, 0 = off)";
CM_ SG_ 2566848766 BMS0_ADB_Batt_OS_2_heater_cont "This parameter contains the status bits indicating the current state of the emergency load-dump, emergency override, heater and charger controls along with the master protection status bit.
Heater control (1 = on, 0 = off)";
CM_ SG_ 2566848766 BMS0_ADB_Batt_OS_1_master_prot "This parameter contains the status bits indicating the current state of the emergency load-dump, emergency override, heater and charger controls along with the master protection status bit.
Master protect (1 = protect, 0 = off)";
CM_ BO_ 2566804222 "This contains high resolution/range parameters reported from the alternator or power generation components.";
CM_ SG_ 2566804222 _nu_BMS0_ADB_AlternatorCurrent "SPN 1795 Alternator Current (High Range/Resolution)
This parameter indicates the amount of electrical current output from the alternator of the main vehicle. Alternator Current
(SPN 115) has a lower range and resolution.";
CM_ SG_ 2566804222 BMS0_ADB_NetBattery_Current "SPN 2579 Net Battery Current (High Range/Resolution)
Net flow of electrical current into/out-of the battery or batteries. This parameter is the high range and resolution of SPN
114 - Net Battery Current.";
CM_ BO_ 2566803710 "Contains battery temperature information.";
CM_ SG_ 2566803710 BMS0_ADB_Battery1_Temperature "Temperature of the battery 1. The relation to physical location is determined by the equipment manufacturer.";
CM_ SG_ 2566803710 _nu_BMS0_ADB_Battery2_Temp "Temperature of the battery 2. The relation to physical location is determined by the equipment manufacturer.";
CM_ BO_ 2566698750 "PGN containing vehicle electrical power information for the battery pack used for starting, lighting, and ignition.";
CM_ SG_ 2566698750 BMS0_ADB_SLI_BattPack_StOfCharge "5981
SLI Battery Pack State of Charge
Indicates the remaining charge of the battery pack used for starting the engine, for lighting, and for ignition (SLI). 0% means no charge remaining, 100% means full capacity at the battery pack's current state of health.   See SPN 5464 for hybrid battery pack.";
CM_ SG_ 2566698750 BMS0_ADB_SLI_BattPack_Capacity "5982
SLI Battery Pack Capacity
Original or rated total reserve capacity of the battery pack used for starting the engine, for lighting, and for ignition (SLI).";
CM_ SG_ 2566698750 BMS0_ADB_SLI_BattPack_Health "5983
SLI Battery Pack Health
Capacity of the battery pack relative to its original specification for the battery pack used for starting the engine, for lighting, and for ignition (SLI). 0% means battery pack is not capable of holding any charge, 100% means battery pack is capable of holding its original full capacity.";
CM_ BO_ 2566862334 "This PGN reports the total number of software-related events that have occurred during the life of the battery.";
CM_ SG_ 2566862334 BMS0_ADB_HardMCLRReset_events "This parameter contains a count of the number times the MCLR has reset the firmware due to a hardware reset pulse, this may be due to the external watchdog.
Data Range: 0 – 64255. A value of 64255 indicates 64255 events or more.";
CM_ SG_ 2566862334 BMS0_ADB_LowVoltageReset_events "TThis parameter contains a count of the number times the firmware has been reset due to the processor detecting a low supply voltage.
Data Range: 0 – 64255. A value of 64255 indicates 64255 events or more.";
CM_ SG_ 2566862334 BMS0_ADB_PORReset_events "This parameter contains a count of the number times the firmware has been started from a power up condition.
Data Range: 0 – 64255. A value of 64255 indicates 64255 events or more.";
CM_ SG_ 2566862334 BMS0_ADB_BrownOutReset_events "This parameter contains a count of the number times the firmware has been restarted due to a brown-out (below 2.7V).
Data Range: 0 – 64255. A value of 64255 indicates 64255 events or more.";
CM_ BO_ 2565799934 "Generic message for send the NAME
Used only for the BMS0";
CM_ SG_ 2565799934 BMS0_ADB_VehicleSystemInstance "Vehicle System Instance";
CM_ SG_ 2565799934 BMS0_ADB_IndustryGroup "Industry Group";
CM_ SG_ 2565799934 BMS0_ADB_Name_Reserved "Reserved";
CM_ SG_ 2565799934 BMS0_ADB_ECUInstance "ECU Instance";
CM_ SG_ 2565799934 BMS0_ADB_IdentityNumber_3 "Most significant 5 bits of Identity Number";
CM_ SG_ 2565799934 BMS0_ADB_ArbitraryAddressCapable "Arbitrary Address Capable";
CM_ SG_ 2565799934 BMS0_ADB_VehicleSystem "Vehicle System";
CM_ SG_ 2565799934 BMS0_ADB_Function "Function";
CM_ SG_ 2565799934 BMS0_ADB_FunctionInstance "Function Instance";
CM_ SG_ 2565799934 BMS0_ADB_ManufacturerCode_2 "Most significant 8 bits of Manufacturer Code";
CM_ SG_ 2565799934 BMS0_ADB_ManufacturerCode_1 "Least significant 3 bits of Manufacturer Code";
CM_ SG_ 2565799934 BMS0_ADB_IdentityNumber_2 "Second byte of Identity Number";
CM_ SG_ 2565799934 BMS0_ADB_IdentityNumber_1 "Least significant byte of Identity Number";
CM_ BO_ 2566838305 "Generic message for update the address";
CM_ SG_ 2566838305 BMS_ADB_VehicleSystemInstance "Vehicle System InstanceVehicle System Instance";
CM_ SG_ 2566838305 BMS_ADB_IndustryGroup "Industry GroupIndustry Group";
CM_ SG_ 2566838305 BMS_ADB_Reserved "ReservedReserved";
CM_ SG_ 2566838305 BMS_ADB_ECUInstance "ECU InstanceECU Instance";
CM_ SG_ 2566838305 BMS_ADB_IdentityNumber_3 "Most significant 5 bits of Identity NumberMost significant 5 bits of Identity Number";
CM_ SG_ 2566838305 BMS_ADB_NewSourceAddress "New source addressNew source address";
CM_ SG_ 2566838305 BMS_ADB_ArbitraryAddressCapable "Arbitrary Address CapableArbitrary Address Capable";
CM_ SG_ 2566838305 BMS_ADB_VehicleSystem "Vehicle SystemVehicle System";
CM_ SG_ 2566838305 BMS_ADB_Function "FunctionFunction";
CM_ SG_ 2566838305 BMS_ADB_FunctionInstance "Function InstanceFunction Instance";
CM_ SG_ 2566838305 BMS_ADB_ManufacturerCode_2 "Most significant 8 bits of Manufacturer CodeMost significant 8 bits of Manufacturer Code";
CM_ SG_ 2566838305 BMS_ADB_ManufacturerCode_1 "Least significant 3 bits of Manufacturer CodeLeast significant 3 bits of Manufacturer Code";
CM_ SG_ 2566838305 BMS_ADB_IdentityNumber_2 "Second byte of Identity NumberSecond byte of Identity Number";
CM_ SG_ 2566838305 BMS_ADB_IdentityNumber_1 "Least significant byte of Identity NumberLeast significant byte of Identity Number";
CM_ BO_ 2582642465 "This PGN is used as a command to reset all devices within the battery in order to clear any faults (if possible), however if the fault conditions are still present then they will recur immediately. ";
CM_ SG_ 2582642465 BMS_ADB_ResetCommand "Reset command parameters
This parameter contains the command to reset the battery. The parameter must contain the value specified otherwise the reset will not be performed.
Data Range: 52h – ASCII ‘R’, all other values reserved";
CM_ BO_ 2565865249 "This PGN is used to control features of the battery.";
CM_ SG_ 2565865249 BMS_ADB_Command_Parameter_1 "This parameter contains the control values for the General Command specified above. ";
CM_ SG_ 2565865249 BMS_ADB_Command_General_Param "This parameter contains the command to be executed by the battery.
Data Range:
1 Heater command
2 Charger current command
3 Sleep command
4 Bypass command
5-199 Reserved
200-250 Battery low level control commands (TBD e.g. charger params).";
CM_ SG_ 2565865249 BMS_ADB_Command_Parameter_2 "Reserved";
CM_ SG_ 2565865249 BMS_ADB_Command_Parameter_3 "Reserved";
CM_ SG_ 2565865249 BMS_ADB_Command_Parameter_4 "Reserved";
CM_ SG_ 2565865249 BMS_ADB_Command_Parameter_5 "Reserved";
CM_ SG_ 2565865249 BMS_ADB_Command_Parameter_6 "Reserved";
CM_ SG_ 2565865249 BMS_ADB_Command_Parameter_7 "Reserved";
CM_ BO_ 2565537569 "Message used to require the 'on request' messages";
CM_ SG_ 2565537569 BMS_ADB_Pgn_Req_Byte_2 "The signal shall be set by the BODY to define the Pgn Requets Byte 2.";
CM_ SG_ 2565537569 BMS_ADB_Pgn_Req_Byte_1 "The signal shall be set by the BODY to define the Pgn Requets Byte 1.";
CM_ SG_ 2565537569 BMS_ADB_Pgn_Req_Byte_0 "The signal shall be set by the BODY to define the Pgn Requets Byte 0.";
CM_ BO_ 2558590753 "BC_2_NET Message";
CM_ SG_ 2558590753 ADB_Hvac_Activation_Sts "This signal indicates the user's request of HVAC activation.";
CM_ SG_ 2558590753 ADB_BL_MinorVersion "This signal contains the BL minor version";
CM_ SG_ 2558590753 ADB_BL_MajorVersion "This signal contains the BL major version";
CM_ SG_ 2558590753 ADB_Sync_Direction_Right "Direction and stop blinking syncronization";
CM_ SG_ 2558590753 ADB_Sync_Direction_Left "Direction and stop blinking syncronization";
CM_ SG_ 2558590753 ADB_Main_Power_Switch_Sts "The signal shall be set by the BODY to define the user's request to system power on/off done by pressing the Main Power Switch.";
CM_ SG_ 2558590753 ADB_Ignition_Switch_Sts "This signal indicates the user's request of Ignition on/off.";
CM_ SG_ 2558590753 ADB_Blackout_Switch_Sts "The signal define whether the Blackout mode is active or not.";
CM_ SG_ 2558590753 ADB_Extra_Battery_Switch_Sts "The signal shall be set by the BODY to define the user's request to system power on/off done by pressing the Start Power Switch.";
CM_ SG_ 2558590753 ADB_BC_Master_Slave_ID "Used to indicate the BODY role: MASTER or SLAVE";
CM_ SG_ 2558590753 ADB_BC_Network_Status "Network Status
The signal shall be set by the BODY to define the status of the system.
- Normal indicates that the system is active;
- Ready To Sleep indicates that the system is ready for the shutdown;";
CM_ SG_ 2558590753 ADB_BC_Param_Version "Versione dei parametri";
CM_ BO_ 2558861708 "This message contains the feedback of the commands sent from the BC to the RUR";
CM_ SG_ 2558861708 ADB_STS_ALM_Left_Supply "J6_OUT_2A_HS_LS_0 (high side)
ALM_Left Supply";
CM_ SG_ 2558861708 ADB_STS_ALM_Right_Supply "J6_OUT_2A_HS_LS_1 (high side)
ALM_Right Supply";
CM_ SG_ 2558861708 ADB_STS_DirectionRearLeftLight "PIN = J6_OUT_2A_PWM_HS_0 (high side)
Direction_Rear_Left_Light";
CM_ SG_ 2558861708 ADB_STS_LatLeftCameraPowerSup "PIN = J6_OUT_6A_HS_0(high side)
Lateral Left Camera Power Supply";
CM_ SG_ 2558861708 ADB_STS_LatRightCameraPowerSup "PIN = J6_OUT_6A_HS_1 (high side)
Lateral Right Camera Power Supply";
CM_ SG_ 2558861708 ADB_STS_RearCameraPowerSup "PIN = J6_OUT_4A_HS_1 (high side)
Rear Camera Power Supply";
CM_ SG_ 2558861708 ADB_STS_Payload_Dome_Light "PIN = J6_OUT_4A_HS_2 (high side)
Payload_Dome_Light (0,6A x2)
P/N = 6014 9472 ";
CM_ SG_ 2558861708 ADB_STS_Payload_Dome_War_Light "PIN = J6_OUT_2A_HS_5 (high side)
Payload_Dome_War_Light (0,6A)";
CM_ SG_ 2558861708 ADB_STS_MarkerRearLeftLight "PIN = J6_OUT_2A_HS_0 (high side)
Marker_Rear_Left_Light (0,2A)";
CM_ SG_ 2558861708 ADB_STS_MarkerRearLeftWarLight "PIN = J6_OUT_2A_HS_1 (high side)
Marker_Rear_Left_War_Light (0,2A)";
CM_ SG_ 2558861708 ADB_STS_Stop_Left_War_Light "PIN = J6_OUT_2A_HS_2 (high side)
Stop_Left_War_Light (0,2A)";
CM_ SG_ 2558861708 ADB_STS_Reverse_Left_Light "PIN = J6_OUT_2A_HS_3 (high side)
Reverse_Left_Light";
CM_ SG_ 2558861708 ADB_STS_Stop_Left_Light "PIN = J6_OUT_2A_PWM_HS_1 (high side)
Stop_Left_Light (1A)";
CM_ SG_ 2558861708 ADB_STS_FES_Supply "J6_OUT_4A_HS_3 (high side)
FES Supply";
CM_ BO_ 2558796172 "This message contains the feedback of the commands sent from the BC to the RUR";
CM_ SG_ 2558796172 ADB_STS_DirectionRearRightLight "PIN = J5_OUT_2A_PWM_HS_0 (high side)
Direction_Rear_Right_Light";
CM_ SG_ 2558796172 ADB_STS_Stop_Right_Light "PIN = J5_OUT_2A_PWM_HS_1 (high side)
Stop_Right_Light";
CM_ SG_ 2558796172 ADB_STS_Stop_Right_War_Light "PIN = J5_OUT_4A_HS_2 (high side)
Stop_Right_War_Light (1A)";
CM_ SG_ 2558796172 ADB_STS_Camera_Washer_Pump_Rear "PIN = J5_OUT_4A_HS_3 (high side)
Camera_Washer_Pump_Rear";
CM_ SG_ 2558796172 ADB_STS_Reverse_Right_Light "PIN = J5_OUT_2A_HS_3
Reverse_Right_Light";
CM_ SG_ 2558796172 ADB_STS_SVS_PowerSupply "PIN = J5_OUT_4A_HS_4 (high side)
SVS_PowerSupply";
CM_ SG_ 2558796172 ADB_STS_MarkerRearRightWarLight "PIN = J5_OUT_2A_HS_0 (high side)
Marker_Rear_Right_War_Light (0,2A)";
CM_ SG_ 2558796172 ADB_STS_MarkerRearRightLight "PIN = J5_OUT_2A_HS_1 (high side)
Marker_Rear_Right_Light (0,2A)";
CM_ SG_ 2558796172 ADB_STS_MarkerLatLeftRightLight "PIN = J5_OUT_2A_HS_2 (high side)
Marker_Lat_Left_Right_Light (0,4A)";
CM_ SG_ 2558796172 ADB_STS_ALS_Left_Enable_SwPowSup "J5_OUT_2A_HS_LS_0 (high side)
ALS Left Enable Switch Power Supply";
CM_ SG_ 2558796172 ADB_STS_ALS_RightEnableSwPowSup "J5_OUT_2A_HS_LS_1 (high side)
ALS Right Enable Switch Power Supply";
CM_ BO_ 2558730636 "This message contains the digital signal status of the RUR";
CM_ SG_ 2558730636 ADB_IN_DIG_Payload_Door_Switch "PIN = J3_IN_GEN_16
CONFIGURATION =  Z12(L=CLOSE ; M=FAULT ; H=OPEN)
REMOTE REMOTE SIGNAL = Payload_Door_Switch
P/N = 50403 9187";
CM_ SG_ 2558730636 ADB_BLACKOUT_GND_RUR "PIN = J1_IN_LS_BLACKOUT
CONFIGURATION = LS(L=NORMAL; H=BLACKOUT)
REMOTE REMOTE SIGNAL = BLACKOUT
P/N = da interruttore plancia NO";
CM_ SG_ 2558730636 ADB_IN_DIG_PayloadHatchLeftSw "PIN = J3_IN_GEN_13
CONFIGURATION =  Z12(L=CLOSE ; M=FAULT ; H=OPEN)
REMOTE SIGNAL = Payload_Hatch_Left_Switch
P/N = 580133 5672

The signal shall be used by the BODY to know whether the loading left door is open or closed.";
CM_ SG_ 2558730636 ADB_IN_DIG_PayloadHatchRightSw "PIN = J3_IN_GEN_14
CONFIGURATION =  Z12(L=CLOSE ; M=FAULT ; H=OPEN)
REMOTE SIGNAL = Payload_Hatch_Right_Switch
P/N = 580133 5672

The signal shall be used by the BODY to know whether the loading right door is open or closed.";
CM_ SG_ 2558730636 ADB_IN_DIG_Rear_Door_Lock "PIN = J3_IN_GEN_15
CONFIGURATION =  HS24(L=UNLOCKED ; H=LOCKED)
REMOTE SIGNAL = Rear_Door_Lock

The signal shall be used by the BODY to know whether the rear door is locked or unlocked.";
CM_ SG_ 2558730636 ADB_IN_DIG_Rear_Door_Switch "PIN = J3_IN_GEN_17
CONFIGURATION =  Z12(L=CLOSE ; H=OPEN)
REMOTE SIGNAL = Rear_Door_Switch
P/N = 50417 2726

The signal shall be used by the BODY to know whether the rear door is open or closed.";
CM_ SG_ 2558730636 ADB_IN_DIG_ALSLeftEnableSw "PIN = J3_IN_GEN_18
CONFIGURATION =  Z12(L=CLOSE ; M=FAULT ; H=OPEN)
REMOTE SIGNAL = ALS_Left_Enable_Switch

The signal shall be used by the BODY to know whether the ALS Left is enabled.";
CM_ SG_ 2558730636 ADB_IN_DIG_ALSRightEnableSw "PIN = J3_IN_GEN_19
CONFIGURATION =  Z12(L=CLOSE ; M=FAULT ; H=OPEN)
REMOTE SIGNAL = ALS_Right_Enable_Switch

The signal shall be used by the BODY to know whether the ALS Left is enabled.";
CM_ SG_ 2558730636 ADB_IN_DIG_ALSLeftAmmLocked "PIN = J3_IN_GEN_20
CONFIGURATION =  Z12(L=CLOSE ; M=FAULT ; H=OPEN)
REMOTE SIGNAL = ALS Left Ammunition Locked Switch

The signal shall be used by the BODY to know whether the ALS  Left Ammunition is Locked.";
CM_ SG_ 2558730636 ADB_IN_DIG_ALSRightAmmLocked "PIN = J3_IN_GEN_21
CONFIGURATION =  Z12(L=CLOSE ; M=FAULT ; H=OPEN)
REMOTE SIGNAL = ALS Right Ammunition Locked Switch

The signal shall be used by the BODY to know whether the ALS  Right Ammunition is Locked.";
CM_ BO_ 2558665100 "This message cointains the analog signal status of the RUR";
CM_ SG_ 2558665100 ADB_IN_ANA_FuelLevelLeftRear "PIN = J3_IN_ANA_RES_0
CONFIGURATION = RES
REMOTE SIGNAL = Fuel_Level_Left_Rear

The signal shall be used by the BODY to know the Rear Left Tank Fuel Level current raw value [mV].";
CM_ SG_ 2558665100 ADB_IN_ANA_FuelLevelRightRear "PIN = J3_IN_ANA_RES_1
CONFIGURATION = RES
REMOTE SIGNAL = Fuel_Level_Right_Rear

The signal shall be used by the BODY to know the Rear Right Tank Fuel Level current raw value [mV].";
CM_ BO_ 2558599564 "This message cointains the analog signal status of the RUR";
CM_ BO_ 2558626849 "This message contains the commands sent from the BC to the RUR";
CM_ SG_ 2558626849 ADB_CMD_ALM_Left_Supply "J6_OUT_2A_HS_LS_0 (high side)
ALM Left Supply

This signal is used to command the ALM Left Supply";
CM_ SG_ 2558626849 ADB_CMD_ALM_Right_Supply "J6_OUT_2A_HS_LS_1 (high side)
ALM Right Supply

This signal is used to command the ALM Right Supply";
CM_ SG_ 2558626849 ADB_CMD_DirectionRearLeftLight "PIN = J6_OUT_2A_PWM_HS_0 (high side)
Direction_Rear_Left_Light

The signal shall be set by the BODY to define the Direction Rear Left light activation/deactivation request.";
CM_ SG_ 2558626849 ADB_CMD_LatLeftCameraPowerSup "PIN = J6_OUT_6A_HS_0(high side)
Lateral Left Camera Power Supply

The signal shall be set by the BODY to define the Lateral Left Camera Power Supply activation/deactivation request.";
CM_ SG_ 2558626849 ADB_CMD_LatRightCameraPowerSup "PIN = J6_OUT_6A_HS_1 (high side)
Lateral Right Camera Power Supply

The signal shall be set by the BODY to define the Lateral Right Camera Power Supply activation/deactivation request.";
CM_ SG_ 2558626849 ADB_CMD_RearCameraPowerSup "PIN = J6_OUT_4A_HS_1 (high side)
Rear Camera Power Supply

The signal shall be set by the BODY to define the Rear Camera Power Supply activation/deactivation request.";
CM_ SG_ 2558626849 ADB_CMD_Payload_Dome_Light "PIN = J6_OUT_4A_HS_2 (high side)
Payload_Dome_Light (0,6A x2)
P/N = 6014 9472 

The signal shall be set by the BODY to define the Payload Dome light activation/deactivation request.";
CM_ SG_ 2558626849 ADB_CMD_Payload_Dome_War_Light "PIN = J6_OUT_2A_HS_5 (high side)
Payload_Dome_War_Light (0,6A)

The signal shall be set by the BODY to define the War Payload Dome light activation/deactivation request.";
CM_ SG_ 2558626849 ADB_CMD_MarkerRearLeftLight "PIN = J6_OUT_2A_HS_0 (high side)
Marker_Rear_Left_Light (0,2A)

The signal shall be set by the BODY to define the Marker Rear Left light activation/deactivation request.";
CM_ SG_ 2558626849 ADB_CMD_MarkerRearLeftWarLight "PIN = J6_OUT_2A_HS_1 (high side)
Marker_Rear_Left_War_Light (0,2A)

The signal shall be set by the BODY to define the War Marker Rear Left light activation/deactivation request.";
CM_ SG_ 2558626849 ADB_CMD_Stop_Left_War_Light "PIN = J6_OUT_2A_HS_2 (high side)
Stop_Left_War_Light (0,2A)

The signal shall be set by the BODY to define the War Stop Left Light activation/deactivation request.";
CM_ SG_ 2558626849 ADB_CMD_Reverse_Left_Light "PIN = J6_OUT_2A_HS_3 (high side)
Reverse_Left_Light

The signal shall be set by the BODY to define the Reverse Left light activation/deactivation request.";
CM_ SG_ 2558626849 ADB_CMD_Stop_Left_Light "PIN = J6_OUT_2A_PWM_HS_1 (high side)
Stop_Left_Light (1A)

The signal shall be set by the BODY to define the Stop Left Light activation/deactivation request.";
CM_ SG_ 2558626849 ADB_CMD_HotWireStart_RUR "J3__IN_ANA_HOTWIRE_START
Attivazione misura hotwire";
CM_ BO_ 2558561313 "This message contains the commands sent from the BC to the RUR";
CM_ SG_ 2558561313 ADB_CMD_DirectionRearRightLight "PIN = J5_OUT_2A_PWM_HS_0 (high side)
Direction_Rear_Right_Light

The signal shall be set by the BODY to define the Direction Rear Right light activation/deactivation request.";
CM_ SG_ 2558561313 ADB_CMD_Stop_Right_Light "PIN = J5_OUT_2A_PWM_HS_1 (high side)
Stop_Right_Light

The signal shall be set by the BODY to define the Stop Right Light activation/deactivation request.";
CM_ SG_ 2558561313 ADB_CMD_Stop_Right_War_Light "PIN = J5_OUT_4A_HS_2 (high side)
Stop_Right_War_Light (1A)

The signal shall be set by the BODY to define the War Stop Left Light activation/deactivation request.";
CM_ SG_ 2558561313 ADB_CMD_Camera_Washer_Pump_Rear "PIN = J5_OUT_4A_HS_3 (high side)
Camera_Washer_Pump_Rear

The signal shall be set by the BODY to define the Central Camera Washer Pump activation/deactivation request.";
CM_ SG_ 2558561313 ADB_CMD_Reverse_Right_Light "PIN = J5_OUT_2A_HS_3
Reverse_Right_Light

The signal shall be set by the BODY to define the Reverse Right light activation/deactivation request.";
CM_ SG_ 2558561313 ADB_CMD_SVS_PowerSupply "PIN = J5_OUT_4A_HS_4 (high side)
SVS Power Supply

The signal shall be set by the BODY to define the SVS Power Supply activation/deactivation request.";
CM_ SG_ 2558561313 ADB_CMD_MarkerRearRightWarLight "PIN = J5_OUT_2A_HS_0 (high side)
Marker_Rear_Right_War_Light (0,2A)

The signal shall be set by the BODY to define the War Marker Rear Right light activation/deactivation request.";
CM_ SG_ 2558561313 ADB_CMD_MarkerRearRightLight "PIN = J5_OUT_2A_HS_1 (high side)
Marker_Rear_Right_Light (0,2A)

The signal shall be set by the BODY to define the Marker Rear Right light activation/deactivation request.";
CM_ SG_ 2558561313 ADB_CMD_MarkerLatLeftRightLight "PIN = J5_OUT_2A_HS_2 (high side)
Marker_Lat_Left_Right_Light (0,4A)

The signal shall be set by the BODY to define the Marker Lateral Left and Right light activation/deactivation request.";
CM_ SG_ 2558561313 ADB_CMD_ALS_Left_Enable_SwPowSup "J5_OUT_2A_HS_LS_0 (high side)
ALS Left Enable Switch Power Supply

The signal shall be set by the BODY to define the ALS Left Enable Switch Power Supply activation/deactivation request.";
CM_ SG_ 2558561313 ADB_CMD_ALSRightEnableSwPowSup "J5_OUT_2A_HS_LS_1 (high side)
ALS Right Enable Switch Power Supply

The signal shall be set by the BODY to define the ALS Right Enable Switch Power Supply activation/deactivation request.";
CM_ BO_ 2558861705 "This message contains the feedback of the commands sent from the BC to the RUF";
CM_ SG_ 2558861705 ADB_STS_EngAreaHeaterWaterValve "PIN = J6_OUT_2A_HS_3 (high side)
EngArea_Heater_Water_Valve
P/N = 6019 1192";
CM_ SG_ 2558861705 ADB_STS_Ventilation_Fw_fan_Valve "PIN = J6_OUT_2A_PWM_HS_1 (pwm)
Ventilation forward fan Valve (0,6A)
Solenoide REXROTH mod.EP4 per pompa Tipo A4VG";
CM_ SG_ 2558861705 ADB_STS_AC_Compressor_Clutch "PIN = J6_OUT_6A_HS_0 (high side)
AC_Compressor_Clutch (4,2A?)";
CM_ SG_ 2558861705 ADB_STS_Air_Dryer "PIN = J6_OUT_6A_HS_1 (high side)
Air_Dryer
P/N = 504078821";
CM_ SG_ 2558861705 ADB_STS_Vacuum_pump_Valve "PIN = J6_OUT_2A_HS_4 (high side)
Vacuum_pump_Valve 
P/N = 6014 3333";
CM_ SG_ 2558861705 ADB_STS_Horn "PIN = J6_OUT_4A_HS_2 (high side)
Horn (2,5A)
P/N = 50422 8904";
CM_ SG_ 2558861705 ADB_STS_Camera_Washer_Pump_Front "PIN = J6_OUT_4A_HS_3 (high side)
Cameras_Washer_Pump_Front (2A x 2) VM
P/N = 504044534";
CM_ SG_ 2558861705 ADB_STS_CrewAreaHeaterWaterValve "PIN = J6_OUT_2A_HS_2 (high side)
CrewArea_Heater_Water_Valve (1,4A)
P/N = 6019 1192";
CM_ SG_ 2558861705 ADB_STS_MarkerFrontWarleftLights "PIN = J6_OUT_2A_HS_0 (high side)
Marker_Front_War_left_Lights";
CM_ SG_ 2558861705 ADB_STS_MarkerFrontWarRLights "PIN = J6_OUT_2A_HS_1 (high side)
Marker_Front_War_right_Lights";
CM_ SG_ 2558861705 ADB_STS_MechanicalPartsPresValve "PIN = J6_OUT_2A_HS_5 (high side)
Mechanical parts pressuriz _Valve (0,5A)
P/N = 6014 3333";
CM_ SG_ 2558861705 ADB_STS_Front_Wheel_Drive_Valve "PIN = J6_OUT_2A_HS_LS_0 (high side)
Front_Wheel_Drive_Valve (0,5A)
P/N = 6014 3333";
CM_ SG_ 2558861705 ADB_STS_Diff_Lock_Front_Valve "PIN = J6_OUT_2A_HS_LS_1 (high side)
Diff_Lock_Front_Valve (0,5A)
P/N = 6014 3333";
CM_ SG_ 2558861705 ADB_STS_Parking_Brake_Valve "PIN = J6_OUT_2A_HS_OR_IN_J6 (high side)
Parking_Brake_Valve(0,5 A)
P/N = 6014 3333";
CM_ SG_ 2558861705 ADB_STS_CentralCameraPowSup "PIN = J6_OUT_4A_HS_0 (high side)
Central Camera Power Supply";
CM_ SG_ 2558861705 ADB_STS_FrontCamerasPowSup "PIN = J6_OUT_4A_HS_1 (high side)
Frontal Cameras Power Supply";
CM_ BO_ 2558796169 "This message contains the feedback of the commands sent from the BC to the RUF";
CM_ SG_ 2558796169 ADB_STS_SteeringValve "PIN = J5_OUT_2A_PWM_HS_0 (pwm)
Steering_Valve
60143334 (steering)";
CM_ SG_ 2558796169 ADB_STS_Front_Fuel_Pump_1 "PIN = J5_OUT_6A_HS_0 (high side)
Fuel_Pump (10A)
P/N = 504142920";
CM_ SG_ 2558796169 ADB_STS_Front_Fuel_Pump_2 "PIN = J5_OUT_6A_HS_1 (high side)
Fuel_Pump (10A)
P/N = 504142920";
CM_ SG_ 2558796169 ADB_STS_LowBeam_Left_Light "PIN = J5_OUT_4A_HS_0 (high side)
LowBeam_Left_Light (3A)";
CM_ SG_ 2558796169 ADB_STS_HighBeam_Left_Light "PIN = J5_OUT_4A_HS_1 (high side)
HighBeam_Left_Light (3A)";
CM_ SG_ 2558796169 ADB_STS_LowBeam_Right_Light "PIN = J5_OUT_4A_HS_2 (high side)
LowBeam_Right_Light (3A)";
CM_ SG_ 2558796169 ADB_STS_HighBeam_Right_Light "PIN = J5_OUT_4A_HS_3 (high side)
HighBeam_Right_Light (3A)";
CM_ SG_ 2558796169 ADB_STS_ProjectorWarLeftLights "PIN = J5_OUT_4A_HS_4 (high side)
Projector_War_left_Lights (1A)";
CM_ SG_ 2558796169 ADB_STS_Fuel_Circuit_Valve "PIN = J4_OUT_20A_HS_1 (high side)
Fuel_Circuit_Valve";
CM_ SG_ 2558796169 ADB_STS_LockAlignRelValve "PIN = J5_OUT_2A_HS_3 (high side)
Lock_Align_Release_Valve
5801591625 (lock)";
CM_ SG_ 2558796169 ADB_STS_DirectionRightLatLigh "PIN = J5_OUT_2A_PWM_HS_1 (high side)
Direction_Right_Lateral_Light (1A)";
CM_ SG_ 2558796169 ADB_STS_DirectionLeftLatLight "PIN = J5_OUT_2A_HS_OR_IN_J5 (high side)
Direction_Left_Lateral_Light (1A)";
CM_ SG_ 2558796169 ADB_STS_DirectionRightFrontLight "PIN = J5_OUT_2A_HS_0 (high side)
Direction_Right_Front_Light";
CM_ SG_ 2558796169 ADB_STS_DirectionLeftFrontLight "PIN = J5_OUT_2A_HS_1 (high side)
Direction_Left_Front_Light";
CM_ SG_ 2558796169 ADB_STS_MarkerFrontleftLights "PIN = J5_OUT_2A_HS_LS_0 (high side)
Marker_Front_left_Lights (0,4A)";
CM_ SG_ 2558796169 ADB_STS_MarkerFrontRightLights "PIN = J5_OUT_2A_HS_LS_1 (high side)
Marker_Front_right_Lights (0,4A)";
CM_ SG_ 2558796169 ADB_STS_Dust_Extraction_Fan "PIN = J4_OUT_20A_HS_0 (high side)
Dust_Extraction_Fan
P/N = 5801802847";
CM_ SG_ 2558796169 ADB_STS_Engine_Bay_Bilge_Pump "PIN = J4_OUT_20A_HS_OR_IN_0 (high side)
Engine_Bay_Bilge_Pump (20A)
P/N = 60145936";
CM_ SG_ 2558796169 ADB_STS_Fuel_Prefilter_Heater "PIN = J4_OUT_20A_HS_OR_IN_1 (high side)
Fuel_Prefilter_Heater (15A)";
CM_ BO_ 2558730634 "This message cointains the digital signal status of the RUC";
CM_ SG_ 2558730634 ADB_IN_DIG_Cmd_K15 "PIN = J3_IN_GEN_23
CONFIGURATION = HS(L=OFF; H=ON)
REMOTE SIGNAL = Cmd_K15
P/N = da interruttore plancia NO

The signal shall be used by the BODY to perform the comparison with the wired signal coming from the Key Switch.";
CM_ SG_ 2558730634 ADB_IN_DIG_Cmd_NBC "PIN = J3_IN_GEN_18
CONFIGURATION = HS(L=OFF; H=ON)
REMOTE SIGNAL = Cmd_K15
P/N = da interruttore plancia NO

The signal shall be used by the BODY to know the NBC direct input status.";
CM_ SG_ 2558730634 ADB_IN_DIG_DriverHatchSw2 "PIN = J3_IN_GEN_13
CONFIGURATION =  Z12(L=CLOSE ; M=FAULT ; H=OPEN)
REMOTE SIGNAL = Driver_Hatch_Switch_2
P/N = 50403 9187

The signal shall be used by the BODY to know whether the Driver door is open or closed.";
CM_ SG_ 2558730634 ADB_IN_DIG_DirectionLightsSwitch "PIN = J3_IN_GEN_15
CONFIGURATION =  Z12(L=RIGHT ; M=IDLE ; H=LEFT)
REMOTE SIGNAL = Direction_Lights_Switch   
P/N = 50414 3729

The signal shall be used by the BODY to know the user's request of Direction lights activation/deactivation.";
CM_ SG_ 2558730634 ADB_IN_DIG_HighBeamLightsSw "PIN = J3_IN_GEN_16
CONFIGURATION =  Z12(L=HIGH_BEAM ; M=IDLE ; H=FLASH)
REMOTE SIGNAL = HighBeam_Lights_Switch 
P/N = 50414 3729

This signal contains the user's request of High Beam and Flash High Beam lights activation/deactivation.";
CM_ SG_ 2558730634 ADB_IN_DIG_Fire_Ventilation "PIN = J3_IN_GEN_17
CONFIGURATION = HS12(L=ALARM, H=NO_ALARM)
REMOTE SIGNAL = Fire_Ventilation 
P/N = 580131 3542

The signal shall be used by the BODY to know whether a crew area fire alarm has been detected.";
CM_ SG_ 2558730634 ADB_IN_DIG_PneumaticParkBrakeSw "PIN = J3_IN_GEN_19
CONFIGURATION = LS(L=NOT_BRAKED ; H=BRAKED)
REMOTE SIGNAL = Pneumatic_ParkBrake_Switch
P/N = 9849 3530

The signal shall be used by the BODY to know the current Pneumatic Park Brake Switch Status read by the sensor.";
CM_ SG_ 2558730634 ADB_IN_DIG_Engine_Start_Button "PIN = J3_IN_GEN_22 
CONFIGURATION = HS24(L=RELEASED ; H=PRESSED)
REMOTE SIGNAL = Engine_Start_Button
P/N = 475 3088 

The signal shall be used by the BODY to know the status of the Cranking Switch.";
CM_ SG_ 2558730634 ADB_IN_DIG_Starter_Override "PIN = J3_IN_GEN_14 
CONFIGURATION = HS24(L=RELEASED ; H=PRESSED)
REMOTE SIGNAL = Starter_Override

The signal shall be used by the BODY to know the status of the Override Switch.";
CM_ SG_ 2558730634 ADB_IN_DIG_Horn_Switch "PIN = J3_IN_GEN_24
CONFIGURATION = HS24(L=IDLE ; H=ACTIVE)
REMOTE SIGNAL = Horn_Switch
P/N = 50414 3729

The signal shall be used by the BODY to know the user's request of Horn sound activation/deactivation.";
CM_ SG_ 2558730634 ADB_IN_DIG_Front_Camera_Washer "PIN = J3_IN_GEN_25
CONFIGURATION = HS24(L = REQUEST ON; H = REQUEST OFF)
REMOTE SIGNAL = Front_Camera_Washer_Request

The signal shall be used by the BODY to know the user's request of front camera washer activation/deactivation.";
CM_ SG_ 2558730634 ADB_IN_DIG_Central_Camera_Washer "PIN = J3_IN_GEN_26
CONFIGURATION = HS24(L = REQUEST ON; H = REQUEST OFF)
REMOTE SIGNAL = Central_Camera_Washer_Request

The signal shall be used by the BODY to know the user's request of front central washer activation/deactivation.";
CM_ SG_ 2558730634 ADB_IN_DIG_Lateral_Camera_Washer "PIN = J3_IN_GEN_27
CONFIGURATION = HS24(L = REQUEST ON; H = REQUEST OFF)
REMOTE SIGNAL = Lateral_Camera_Washer_Request

The signal shall be used by the BODY to know the user's request of rear camera washer activation/deactivation.";
CM_ SG_ 2558730634 ADB_BLACKOUT_GND_RUC "PIN = J1_IN_LS_BLACKOUT
CONFIGURATION = LS(L=NORMAL; H=BLACKOUT)
REMOTE SIGNAL = BLACKOUT
P/N = da interruttore plancia NO";
CM_ BO_ 2558665097 "This message cointains the analog signal status of the RUF";
CM_ SG_ 2558665097 ADB_IN_ANA_Coolant_Temp_2 "PIN = J3_IN_GEN_4
CONFIGURATION = ANA05
REMOTE SIGNAL = Coolant_Temp_2

Temperature of liquid found in engine cooling system.
See also SPN 110";
CM_ SG_ 2558665097 ADB_IN_ANA_Fuel_Level_Front "PIN = J3_IN_ANA_RES_0
CONFIGURATION = RES
REMOTE SIGNAL = Fuel_Level_Front

The signal shall be used by the BODY to know the Front Tank Fuel Level current raw value [mV].";
CM_ SG_ 2558665097 ADB_IN_ANA_EngineCoolantLev1 "PIN = J3_IN_GEN_8
CONFIGURATION = ANA24
REMOTE SIGNAL = Engine_Coolant_Level_1
P/N = 5801484630

The signal shall be used by the BODY to know the status of the Engine Coolant Level Sensor 1.";
CM_ SG_ 2558665097 ADB_IN_ANA_EngineCoolantLev2 "PIN = J3_IN_GEN_9
CONFIGURATION = ANA24
REMOTE SIGNAL = Engine_Coolant_Level_2
P/N = 5801484630

The signal shall be used by the BODY to know the status of the Engine Coolant Level Sensor 1.";
CM_ SG_ 2558665097 ADB_IN_ANA_MechParkingBrakeSw "PIN = J3_IN_GEN_10
CONFIGURATION = LS(L=NOT BRAKED; H=BRAKED)
REMOTE SIGNAL = Parking_Brake_Switch (on gear)
P/N = da definire";
CM_ SG_ 2558665097 ADB_IN_ANA_FrontWheelDriveLeftSw "PIN = J3_IN_GEN_12
CONFIGURATION = LS(L=ENGAGED ; H=NOT_ENGAGED)
REMOTE SIGNAL = Front_wheel_drive_left_Switch
P/N = 60155072

The signal shall be used by the BODY to know whether the Front Left Wheel Drive is engaged or not .";
CM_ SG_ 2558665097 ADB_IN_ANA_EngineOilLevelSensor "PIN = J3_IN_ANA_HOTWIRE_POS
CONFIGURATION = HOTW
REMOTE SIGNAL = Engine Oil Level Sensor
P/N = 99451545 EZ (vd. 500324137)

The signal shall be used by the BODY to know the Engine Oil Level Sensor Status value [mV].";
CM_ BO_ 2558599561 "This message cointains the analog signal status of the RUF";
CM_ SG_ 2558599561 ADB_IN_ANA_RearAxleAlignedLockSw "PIN = J3_IN_GEN_0
CONFIGURATION = LS(L=ALIGNED, H = NOT ALIGNED)
REMOTE SIGNAL = Rear_axle_aligned_locked_Switch
P/N = 60144771

The signal shall be used by the BODY to know whether the Rear Axle is aligned or not.";
CM_ SG_ 2558599561 ADB_IN_ANA_Fan_Oil_Pressure_A "PIN = J3_IN_GEN_3
CONFIGURATION = ANA05(20 [mv/bit] ; MAX=5V)
REMOTE SIGNAL = Fan_Oil_Pressure_A (forward)
P/N = 5801655012

The signal shall be used to define the Cooling Fan Oil Pressure current value (Forward)";
CM_ SG_ 2558599561 ADB_IN_ANA_Fan_Oil_Pressure_B "PIN = J3_IN_GEN_6
CONFIGURATION = ANA05(20 [mv/bit] ; MAX=5V)
REMOTE SIGNAL = Fan_Oil_Pressure_B (reverse)
P/N = 5801655012

The signal shall be used to define the Cooling Fan Oil Pressure current value (Reverse)";
CM_ SG_ 2558599561 ADB_IN_ANA_AirFilter_Clogged "PIN = J3_IN_GEN_7
CONFIGURATION = LS(L = NORMAL; H = CLOGGED)
REMOTE SIGNAL = AirFilter_Clogged
P/N = 5801673651

The signal shall be used by the BODY to know whether the Engine Air Filter is clogged or not.";
CM_ SG_ 2558599561 ADB_IN_ANA_FuelLevelHighFrontSw "PIN = J3_IN_GEN_2
CONFIGURATION =  Z12(L=OK ; H=HIGH_FUEL ; M=FAULT)
REMOTE SIGNAL = Fuel_Level_High_Front

The signal shall be used by the BODY to know when the front tank level is high or not.";
CM_ BO_ 2558626081 "This message contains the commands sent from the BC to the RUF";
CM_ SG_ 2558626081 ADB_CMD_Ventilation_Fw_fan_Valve "PIN = J6_OUT_2A_PWM_HS_1 (pwm)
Ventilation forward fan Valve (0,6A)
Solenoide REXROTH mod.EP4 per pompa Tipo A4VG

The signal shall be used to require the Cooling Fan Valve Request (Forward)";
CM_ SG_ 2558626081 ADB_CMD_AC_Compressor_Clutch "PIN = J6_OUT_6A_HS_0 (high side)
AC_Compressor_Clutch (4,2A?)

The signal shall be set by the BODY to define the Compressor Clutch activation/deactivation request to the RUF.";
CM_ SG_ 2558626081 ADB_CMD_Air_Dryer "PIN = J6_OUT_6A_HS_1 (high side)
Air_Dryer
P/N = 504078821

The signal shall be set by the BODY to define the request of the Air Dryer activation or deactivation.";
CM_ SG_ 2558626081 ADB_CMD_Vacuum_pump_Valve "PIN = J6_OUT_2A_HS_4 (high side)
Vacuum_pump_Valve 
P/N = 6014 3333

The signal shall be set by the BODY to define the Vacuum Pump activation/deactivation request.";
CM_ SG_ 2558626081 ADB_CMD_Horn "PIN = J6_OUT_4A_HS_2 (high side)
Horn (2,5A)
P/N = 50422 8904

The signal shall be set by the BODY to define the Horn sound activation/deactivation request.";
CM_ SG_ 2558626081 ADB_CMD_Camera_Washer_Pump_Front "PIN = J6_OUT_4A_HS_3 (high side)
Cameras_Washer_Pump_Front (2A x 2) VM
P/N = 504044534

The signal shall be set by the BODY to define the Central Camera Washer Pump activation/deactivation request.";
CM_ SG_ 2558626081 ADB_CMD_EngAreaHeaterWaterValve "PIN = J6_OUT_2A_HS_3 (high side)
EngArea_Heater_Water_Valve
P/N = 6019 1192

The signal shall be set by the BODY to define the Engine Area Water Heater Heater Valve activation/deactivation request to the RUF.";
CM_ SG_ 2558626081 ADB_CMD_CrewAreaHeaterWaterValve "PIN = J6_OUT_2A_HS_2 (high side)
CrewArea_Heater_Water_Valve (1,4A)
P/N = 6019 1192

The signal shall be set by the BODY to define the Crew Area Water Heater Valve activation/deactivation request to the RUF.";
CM_ SG_ 2558626081 ADB_CMD_MarkerFrontWarLeftLights "PIN = J6_OUT_2A_HS_0 (high side)
Marker_Front_War_left_Lights

The signal shall be set by the BODY to define the War Marker Front Left light activation/deactivation request.";
CM_ SG_ 2558626081 ADB_CMD_MarkerFrontWarRLights "PIN = J6_OUT_2A_HS_1 (high side)
Marker_Front_War_right_Lights

The signal shall be set by the BODY to define the War Marker Front Right light activation/deactivation request.";
CM_ SG_ 2558626081 ADB_CMD_MechanicalPartsPresValve "PIN = J6_OUT_2A_HS_5 (high side)
Mechanical parts pressuriz _Valve (0,5A)
P/N = 6014 3333

The signal shall be set by the BODY to define the Ford Mode activation/deactivation request to the RUF.";
CM_ SG_ 2558626081 ADB_CMD_Front_Wheel_Drive_Valve "PIN = J6_OUT_2A_HS_LS_0 (high side)
Front_Wheel_Drive_Valve (0,5A)
P/N = 6014 3333

The signal shall be set by the BODY to define the All Wheel Drive mode activation/deactivation request to the RUF.";
CM_ SG_ 2558626081 ADB_CMD_Diff_Lock_Front_Valve "PIN = J6_OUT_2A_HS_LS_1 (high side)
Diff_Lock_Front_Valve (0,5A)
P/N = 6014 3333

The signal shall be set by the BODY to define the Differential Lock mode activation/deactivation request to the RUF.";
CM_ SG_ 2558626081 ADB_CMD_MechParking_Brake_Valve "PIN = J6_OUT_2A_HS_OR_IN_J6 (high side)
Parking_Brake_Valve(0,5 A)
P/N = 6014 3333";
CM_ SG_ 2558626081 ADB_CMD_HotWireStart_RUF "J3__IN_ANA_HOTWIRE_START
Attivazione misura hotwire";
CM_ SG_ 2558626081 ADB_CMD_CentralCameraPowSup "PIN = J6_OUT_4A_HS_0 (high side)
Central Camera Power Supply

The signal is used for the power supply of the central camera.";
CM_ SG_ 2558626081 ADB_CMD_FrontCamerasPowSup "PIN = J6_OUT_4A_HS_1 (high side)
Frontal Cameras Power Supply

The signal is used for the power supply of the frontal cameras.";
CM_ BO_ 2558560545 "This message contains the commands sent from the BC to the RUF";
CM_ SG_ 2558560545 ADB_CMD_SteeringValve "PIN = J5_OUT_2A_PWM_HS_0 (high side)
Steering_Valve
60143334 (steering)

The signal shall be set by the BODY to define the Fourth Axle Steering mode activation/deactivation request to the RUF.";
CM_ SG_ 2558560545 ADB_CMD_Front_Fuel_Pump_1 "PIN = J5_OUT_6A_HS_0 (high side)
Fuel_Pump (10A)
P/N = 504142920

The signal shall be set by the BODY to define the request of the Front Fuel Pump 1 activation or deactivation.";
CM_ SG_ 2558560545 ADB_CMD_Front_Fuel_Pump_2 "PIN = J5_OUT_6A_HS_1 (high side)
Fuel_Pump (10A)
P/N = 504142920

The signal shall be set by the BODY to define the request of the Front Fuel Pump 2 activation or deactivation.";
CM_ SG_ 2558560545 ADB_CMD_LowBeam_Left_Light "PIN = J5_OUT_4A_HS_0 (high side)
LowBeam_Left_Light (3A)

The signal shall be set by the BODY to define the Low Beam Left light activation/deactivation request.";
CM_ SG_ 2558560545 ADB_CMD_HighBeam_Left_Light "PIN = J5_OUT_4A_HS_1 (high side)
HighBeam_Left_Light (3A)

The signal shall be set by the BODY to define the High Beam Left light activation/deactivation request.";
CM_ SG_ 2558560545 ADB_CMD_LowBeam_Right_Light "PIN = J5_OUT_4A_HS_2 (high side)
LowBeam_Right_Light (3A)

The signal shall be set by the BODY to define the Low Beam Right light activation/deactivation request.";
CM_ SG_ 2558560545 ADB_CMD_HighBeam_Right_Light "PIN = J5_OUT_4A_HS_3 (high side)
HighBeam_Right_Light (3A)

The signal shall be set by the BODY to define the High Beam Right light activation/deactivation request.";
CM_ SG_ 2558560545 ADB_CMD_ProjectorWarLights "PIN = J5_OUT_4A_HS_4 (high side)
Projector_War_Lights (1A)

The signal shall be set by the BODY to define the War Projector Left activation/deactivation request.";
CM_ SG_ 2558560545 ADB_CMD_Fuel_Circuit_Valve "PIN = J4_OUT_20A_HS_1 (high side)
Fuel_Circuit_Valve

The signal shall be set by the BODY to define the request of Transfer Fuel Pump activation/deactivation.";
CM_ SG_ 2558560545 ADB_CMD_LockAlignRelValve "PIN = J5_OUT_2A_HS_3 (high side)
Lock_Align_Release_Valve
5801591625 (lock)

The signal shall be set by the BODY to define the Fourth Axle Steering mode activation/deactivation request to the RUF.";
CM_ SG_ 2558560545 ADB_CMD_DirectionRightLatLigh "PIN = J5_OUT_2A_PWM_HS_1 (high side)
Direction_Right_Lateral_Light (1A)

The signal shall be set by the BODY to define the Direction Lateral Right light activation/deactivation request.";
CM_ SG_ 2558560545 ADB_CMD_DirectionLeftLatLight "PIN = J5_OUT_2A_HS_OR_IN_J5 (high side)
Direction_Left_Lateral_Light (1A)

The signal shall be set by the BODY to define the Direction Lateral Left light activation/deactivation request.";
CM_ SG_ 2558560545 ADB_CMD_DirectionRightFrontLight "PIN = J5_OUT_2A_HS_0 (high side)
Direction_Right_Front_Light

The signal shall be set by the BODY to define the Direction Front Right light activation/deactivation request.";
CM_ SG_ 2558560545 ADB_CMD_DirectionLeftFrontLight "PIN = J5_OUT_2A_HS_1 (high side)
Direction_Left_Front_Light

The signal shall be set by the BODY to define the Direction Front Left light activation/deactivation request.";
CM_ SG_ 2558560545 ADB_CMD_MarkerFrontLeftLights "PIN = J5_OUT_2A_HS_LS_0 (high side)
Marker_Front_left_Lights (0,4A)

The signal shall be set by the BODY to define the Marker Front Left light activation/deactivation request.";
CM_ SG_ 2558560545 ADB_CMD_MarkerFrontRightLights "PIN = J5_OUT_2A_HS_LS_1 (high side)
Marker_Front_right_Lights (0,4A)

The signal shall be set by the BODY to define the Marker Front Right light activation/deactivation request.";
CM_ SG_ 2558560545 ADB_CMD_Dust_Extraction_Fan "PIN = J4_OUT_20A_HS_0 (high side)
Dust_Extraction_Fan
P/N = 5801802847

The signal shall be set by the BODY to define the Dust Extraction Fan activation/deactivation request.";
CM_ SG_ 2558560545 ADB_CMD_Engine_Bay_Bilge_Pump "PIN = J4_OUT_20A_HS_OR_IN_0 (high side)
Engine_Bay_Bilge_Pump (20A)
P/N = 60145936

The signal shall be set by the BODY to define the Engine Bay Bilge Pump activation/deactivation request to the RUF.";
CM_ SG_ 2558560545 ADB_CMD_Fuel_Prefilter_Heater "PIN = J4_OUT_20A_HS_OR_IN_1 (high side)
Fuel_Prefilter_Heater (15A)

The signal shall be set by the BODY to define the request of the Fuel Prefilter Heater activation or deactivation.";
CM_ BO_ 2558861706 "This message contains the feedback of the commands sent from the BC to the RUC";
CM_ SG_ 2558861706 ADB_STS_Cmd_Heater "PIN = J6_OUT_2A_HS_2
Cmd_Heater";
CM_ SG_ 2558861706 ADB_STS_Sights_Washer_Pump "PIN = J6_OUT_4A_HS_0 (high side)
Sights_Washer_Pump (2A) VM
P/N = 504044534";
CM_ SG_ 2558861706 ADB_STS_Camera_Washer_Pump_Cent "PIN = J6_OUT_4A_HS_2(high side)
Camera_Washer_Pump_Central (2A) VM
P/N = 504044534";
CM_ SG_ 2558861706 ADB_STS_LED_Enable "PIN = J6_OUT_2A_HS_LS_0 (high side)
LED Enable
";
CM_ SG_ 2558861706 ADB_STS_Monitors_Supply "PIN = J6_OUT_4A_HS_3 (high side)
Driver Monitors Supply";
CM_ SG_ 2558861706 ADB_STS_Driver_Dome_Light "PIN = J6_OUT_2A_HS_0 (high side)
Driver_Dome_Light 
P/N = 6014 9472 ";
CM_ SG_ 2558861706 ADB_STS_Driver_Dome_War_Light "PIN = J6_OUT_2A_HS_1 (high side)
Driver_Dome_War_Light ";
CM_ SG_ 2558861706 ADB_STS_Sights_Dryer_Valve "PIN = J6_OUT_2A_HS_3 (high side)
Sights_Dryer_Valve (0,5A) VM
P/N = 6014 3333";
CM_ SG_ 2558861706 ADB_STS_Logbox_Supply "PIN =J6_OUT_4A_HS_1 (high side)
Logbox_Supply";
CM_ BO_ 2558796170 "This message contains the feedback of the commands sent from the BC to the RUC";
CM_ SG_ 2558796170 ADB_STS_Engine_Starter_Relay "PIN = J5_OUT_4A_HS_0 (high side)
Engine_Starter_Relay
P/N = 504361301";
CM_ SG_ 2558796170 ADB_STS_Main_Power_Relay "PIN = J5_OUT_4A_HS_1 (high side)
Main_Power_Relay (0,5A)
P/N = 504264646";
CM_ SG_ 2558796170 ADB_STS_Extra_battery_Relay "PIN = J5_OUT_4A_HS_2 (high side)
Extra_battery_Relay (0,5A)
P/N = 504264646";
CM_ SG_ 2558796170 ADB_STS_NC_sensor_power_supply "PIN = J5_OUT_4A_HS_3 (high side)
NC_sensor_power_supply
P/N 5801949954";
CM_ SG_ 2558796170 ADB_STS_Alternator_IGN "PIN = J5_OUT_2A_HS_1 (high side)
Alternator_IGN";
CM_ SG_ 2558796170 ADB_STS_NBC_Press_Blackout "PIN = J5_OUT_2A_HS_0 (high side)
NBC_Press_Blackout";
CM_ SG_ 2558796170 ADB_STS_CTIS_Supply "PIN = J5_OUT_4A_HS_4 (high side)
CTIS_Supply (??A) VM
P/N = 5801726076";
CM_ SG_ 2558796170 ADB_STS_Water_Purge_VM "PIN = J5_OUT_2A_HS_2 (high side)
Water_Purge VM";
CM_ SG_ 2558796170 ADB_STS_Buzzer "PIN = J5_OUT_2A_HS_3 (high side)
Buzzer
P/N = 475 2891";
CM_ SG_ 2558796170 ADB_STS_NBC_Vent_160 "PIN = J5_OUT_2A_HS_LS_0 (Low side)
NBC_Vent_160";
CM_ SG_ 2558796170 ADB_STS_NBC_Vent_200 "PIN = J5_OUT_2A_HS_LS_1 (Low side)
NBC_Vent_200";
CM_ BO_ 2558730633 "This message cointains the digital signal status of the RUF";
CM_ SG_ 2558730633 ADB_IN_DIG_BrakeCirc1LowOilPress "PIN = J3_IN_GEN_23
CONFIGURATION =  Z12(L=PRESS_OK; H=LOW_PRESS; M=FAULT)
REMOTE SIGNAL = Brake_Circ1_Low_Oil_Press
P/N = 60167281

The signal shall be used by the BODY to know Brakes Oil Pressure Switch Status in the Cicuit 1.";
CM_ SG_ 2558730633 ADB_IN_DIG_BrakeCirc2LowOilPress "PIN = J3_IN_GEN_24
CONFIGURATION =  Z12(L=PRESS_OK; H=LOW_PRESS; M=FAULT)
REMOTE SIGNAL = Brake_Circ2_Low_Oil_Press
P/N = 60167281

The signal shall be used by the BODY to know Brakes Oil Pressure Switch Status in the Cicuit 2.";
CM_ SG_ 2558730633 ADB_IN_DIG_BrakeOilLevelEngComp "PIN = J3_IN_GEN_25
CONFIGURATION = LS(L=NO_ALARM; H=ALARM )
REMOTE SIGNAL = Brake_Oil_Level _Engine_compartment
P/N = 504229146

The signal shall be used by the BODY to know Brakes Oil Level Status.";
CM_ SG_ 2558730633 ADB_IN_DIG_DiffLockSwFrontAxle "PIN = J3_IN_GEN_28
CONFIGURATION = LS(L=ENGAGED; H=NOT_ENGAGED)
REMOTE SIGNAL = Differential locking switch front axle
P/N = 60155072

The signal shall be used by the BODY to know whether the Differential Lock is engaged or not .";
CM_ SG_ 2558730633 ADB_IN_DIG_Front_Axle_Aligned "PIN = J3_IN_GEN_16
CONFIGURATION = LS(L=NOT_ALIGNED ; H=ALIGNED)
REMOTE SIGNAL = Front_Axle_Aligned
P/N = 504214568

The signal shall be used by the BODY to know whether the Front Axle is aligned or not.";
CM_ SG_ 2558730633 ADB_IN_DIG_FrontWheelDriveRSw "PIN = J3_IN_GEN_13
CONFIGURATION = LS(L=ENGAGED ; H=NOT_ENGAGED)
REMOTE SIGNAL = Front_wheel_drive_right_Switch
P/N = 60155072

The signal shall be used by the BODY to know whether the Front Right Wheel Drive is engaged or not .";
CM_ SG_ 2558730633 ADB_IN_DIG_FuelPreFilterClogSw "PIN = J3_IN_GEN_26
CONFIGURATION = LS(L= NO ALARM; H = ALARM)
REMOTE SIGNAL = Fuel Pre_Filter_Clogged_Switch
P/N = PREFILTRO NUOVO UFI

The signal shall be used by the BODY to know whether the Fuel Filter is clogged or not.";
CM_ SG_ 2558730633 ADB_IN_DIG_LowFlowPowSteeringSw "PIN = J3_IN_GEN_20
CONFIGURATION = LS(L=ALARM; H=NO_ALARM)
REMOTE SIGNAL = Low_Flow_PowerSteering_Switch
P/N = 60146290

The signal shall be used by the BODY to know Power Steering Oil Flow Status.";
CM_ SG_ 2558730633 ADB_IN_DIG_LowPressPowSteering1 "PIN = J3_IN_GEN_21
CONFIGURATION = LS(L=ALARM; H=NO_ALARM)
REMOTE SIGNAL = Low_Pressure_PowerSteering_Circ1
P/N = su guida 5801297967

The signal shall be used by the BODY to know Power Steering Oil Pressure Switch 1 Status.";
CM_ SG_ 2558730633 ADB_IN_DIG_LowPressPowSteering2 "PIN = J3_IN_GEN_22 
CONFIGURATION = LS(L=ALARM; H=NO_ALARM)
REMOTE SIGNAL = Low_Pressure_PowerSteering_circ2

The signal shall be used by the BODY to know Power Steering Oil Pressure Switch 2 Status.";
CM_ SG_ 2558730633 ADB_IN_DIG_MechanicalPartsPresSw "PIN = J3_IN_GEN_29 (40mA)
CONFIGURATION = LS(L=PRESSURE_OK; H=NO_PRESSURE)
REMOTE SIGNAL = Mechanical_Parts_Pressur_Switch 
P/N = 60153565

The signal shall be used by the BODY to know the status of the Mechanical Parts Pressurization Switch.";
CM_ SG_ 2558730633 ADB_IN_DIG_PowSteeringOilLevelSw "PIN = J3_IN_GEN_19
CONFIGURATION = LS(L=LEVEL OK; H=LOW LEVEL)
REMOTE SIGNAL = PowerSteering_Oil_Level_Switch
P/N = 8188036

The signal shall be used by the BODY to know Power Steering Oil Level Status.";
CM_ SG_ 2558730633 ADB_IN_DIG_ServicesAirPressureSw "PIN = J3_IN_GEN_27
CONFIGURATION = LS(L=LOW_PRESSURE; H=PRESSURE_OK)
REMOTE SIGNAL = Services_Air_Pressure_Switch
P/N = 60153565

The signal shall be used by the BODY to know whether the Service Air Pressure is high or low.";
CM_ SG_ 2558730633 ADB_BLACKOUT_GND_RUF "PIN = J1_IN_LS_BLACKOUT
CONFIGURATION = LS(L=NORMAL; H=BLACKOUT)
REMOTE SIGNAL = BLACKOUT_GND
P/N = da interruttore plancia NO";
CM_ SG_ 2558730633 ADB_IN_DIG_MechanicalParkBrake "PIN = J3_IN_GEN_14
CONFIGURATION = LS(L=REQUESTED ; H=NOT_REQUESTED)
REMOTE SIGNAL = Pneumatic_ParkBrake_Switch
P/N = 9849 3530

The signal shall be used by the BODY to know the current Pneumatic Park Brake Switch Status read by the sensor.";
CM_ BO_ 2558665098 "This message cointains the analog signal status of the RUC";
CM_ SG_ 2558665098 ADB_IN_ANA_NBC_Fault "PIN = J3_IN_GEN_10
CONFIGURATION = LS(LOW (continous) = BLOCKED; 
LOW (alternate) = OVERTEMPERATURE)
REMOTE SIGNAL = NBC_Fault";
CM_ SG_ 2558665098 ADB_IN_ANA_NBC_Low_Press "PIN = J3_IN_GEN_11
CONFIGURATION = HS(L=OK ; H=LOW PRESSURE)
REMOTE SIGNAL = NBC_Low_Press";
CM_ SG_ 2558665098 ADB_IN_ANA_DriverHatchSw1 "PIN = J3_IN_GEN_12
CONFIGURATION =  Z12(L=CLOSE ; M=FAULT ; H=OPEN)
REMOTE SIGNAL = Driver_Hatch_Switch_1
P/N = 50403 9187

The signal shall be used by the BODY to know whether the Driver door is open or closed.";
CM_ SG_ 2558665098 ADB_IN_ANA_Fuel_Level_Central "PIN = J3_IN_ANA_RES_0
CONFIGURATION = RES(4 [ohm/bit] ; MAX=1000ohm)
REMOTE SIGNAL = Fuel_Level_Central

The signal shall be used by the BODY to know the Central Tank Fuel Level current raw value [mV].";
CM_ SG_ 2558665098 ADB_IN_ANA_RetarderDown "PIN = J3_IN_GEN_8
CONFIGURATION = HS(L=REQUESTED ON ; H=REQUESTED OFF)
REMOTE SIGNAL = Retarder_Request_Down

This signal is used to detect if the retarder down pushbutton has been pressed.";
CM_ SG_ 2558665098 ADB_IN_ANA_RetarderUp "PIN = J3_IN_GEN_9
CONFIGURATION = HS(L=REQUESTED ON ; H=REQUESTED OFF)

REMOTE SIGNAL = Retarder_Request_Up

This signal is used to detect if the retarder up pushbutton has been pressed.";
CM_ BO_ 2558599562 "This message cointains the analog signal status of the RUC";
CM_ SG_ 2558599562 ADB_IN_ANA_RetarderOnOff "PIN = J3_IN_GEN_0
CONFIGURATION = LS(L = REQUEST ON; H = REQUEST OFF)
REMOTE SIGNAL = Retarder_Request_OnOff

This signal is used to detect if the retarder on/off pushbutton has been pressed.";
CM_ SG_ 2558599562 ADB_IN_ANA_FireSensorEngineBay "PIN = J3_IN_GEN_1
CONFIGURATION = HS12(L=NO ALARM, H = ALARM)
REMOTE SIGNAL = Fire_Sensor_Engine_Bay
P/N = 580131 3542

The signal shall be used by the BODY to know whether a engine bay fire alarm has been detected.";
CM_ SG_ 2558599562 ADB_IN_ANA_Main_power_switch "PIN = J3_IN_GEN_3
CONFIGURATION = HS24(float=NOT_ACTIVE; H=ACTIVE)
REMOTE SIGNAL = Main_power_switch

The signal shall be used by the BODY to perform the comparison with the wired signal coming from the Main PowerSwitch.";
CM_ SG_ 2558599562 ADB_IN_ANA_Extra_battery_switch "PIN = J3_IN_GEN_4
CONFIGURATION = HS24(float=NOT_ACTIVE; H=ACTIVE)
REMOTE SIGNAL = Extra_battery_switch

The signal shall be used by the BODY to perform the comparison with the wired signal coming from the Start PowerSwitch.";
CM_ SG_ 2558599562 ADB_IN_ANA_NBC_Prefilter_Clogged "PIN = J3_IN_GEN_5
CONFIGURATION = LS
REMOTE SIGNAL = NBC_Prefilter_Clogged

This signal indicates the the NBC prefilter is clogged.";
CM_ SG_ 2558599562 ADB_IN_ANA_NBC_Filter_Clogged "PIN = J3_IN_GEN_6
CONFIGURATION = LS
REMOTE SIGNAL = NBC_Filter_Clogged

This signal indicates the the NBC filter is clogged.";
CM_ SG_ 2558599562 ADB_IN_ANA_NBC_Mode "PIN = J3_IN_GEN_7
CONFIGURATION = LS(L = NBC MODE ON; H = OFF)
REMOTE SIGNAL = NBC_Mode

This signal indicates if the NBC filter cartridges are present or not";
CM_ SG_ 2558599562 ADB_IN_ANA_Sight_Washer_Request "PIN = J3_IN_GEN_2
CONFIGURATION = HS24(L = REQUEST ON; H = REQUEST OFF)
REMOTE SIGNAL = Camera_Washer_Request

The signal shall be used by the BODY to know whether the camera washer request pushbutton are pressed.";
CM_ BO_ 2558626337 "This message contains the commands sent from the BC to the RUC";
CM_ SG_ 2558626337 ADB_CMD_Cmd_Heater "PIN = J6_OUT_2A_HS_2
Cmd_Heater

The signal shall be set by the BODY to define the Hydronic Heater activation/deactivation request to the RUC.";
CM_ SG_ 2558626337 ADB_CMD_Sights_Washer_Pump "PIN = J6_OUT_4A_HS_0 (high side)
Sights_Washer_Pump (2A) VM
P/N = 504044534

The signal shall be set by the BODY to define the Sight Washer Pump activation/deactivation request to the RUC.";
CM_ SG_ 2558626337 ADB_CMD_Camera_Washer_Pump_Cent "PIN = J6_OUT_4A_HS_2 (high side)
Camera_Washer_Pump_Central (2A) VM
P/N = 504044534

The signal shall be set by the BODY to define the Central Camera Washer Pump activation/deactivation request.";
CM_ SG_ 2558626337 ADB_CMD_LED_Enable "PIN = J6_OUT_2A_HS_LS_0 (high side)
LED Enable

This signal is used to enable the LEDs on the driver area";
CM_ SG_ 2558626337 ADB_CMD_Monitors_Supply "PIN = J6_OUT_4A_HS_3 (high side)
Driver Monitors Supply

This signal is used to command the Driver Monitors Supply";
CM_ SG_ 2558626337 ADB_CMD_Driver_Dome_Light "PIN = J6_OUT_2A_HS_0 (high side)
Driver_Dome_Light 
P/N = 6014 9472 

The signal shall be set by the BODY to define the driver dome light activation/deactivation request.";
CM_ SG_ 2558626337 ADB_CMD_Driver_Dome_War_Light "PIN = J6_OUT_2A_HS_1 (high side)
Driver_Dome_War_Light 

The signal shall be set by the BODY to define the driver dome war light activation/deactivation request.";
CM_ SG_ 2558626337 ADB_CMD_Sights_Dryer_Valve "PIN = J6_OUT_2A_HS_3 (high side)
Sights_Dryer_Valve (0,5A) VM
P/N = 6014 3333

The signal shall be set by the BODY to define the Sight Dryer Valve activation/deactivation request to the RUC.";
CM_ SG_ 2558626337 ADB_CMD_Logbox_Supply "PIN =J6_OUT_4A_HS_1 (high side)
Logbox_Supply

This signal is used to command the LOGBOX Supply";
CM_ SG_ 2558626337 ADB_CMD_HotWireStart_RUC "J3__IN_ANA_HOTWIRE_START
Attivazione misura hotwire";
CM_ BO_ 2558560801 "This message contains the commands sent from the BC to the RUC";
CM_ SG_ 2558560801 ADB_CMD_Engine_Starter_Relay "PIN = J5_OUT_4A_HS_0 (high side)
Engine_Starter_Relay
P/N = 504361301

The signal shall be set by the BODY to define the Cranking request.";
CM_ SG_ 2558560801 ADB_CMD_Main_Power_Relay "PIN = J5_OUT_4A_HS_1 (high side)
Main_Power_Relay (0,5A)
P/N = 504264646

The signal shall be set by the BODY to define the request to open/close the Main Power Relè.";
CM_ SG_ 2558560801 ADB_CMD_Extra_battery_Relay "PIN = J5_OUT_4A_HS_2 (high side)
Extra_battery_Relay (0,5A)
P/N = 504264646

The signal shall be set by the BODY to define the request to open/close the Start Power Relè.";
CM_ SG_ 2558560801 ADB_CMD_NC_sensor_power_supply "PIN = J5_OUT_4A_HS_3 (high side)
NC_sensor_power_supply
P/N = 5801949954

This signal indicates the command for switch the NC power supply ON.";
CM_ SG_ 2558560801 ADB_CMD_Alternator_IGN "PIN = J5_OUT_2A_HS_1 (high side)
Alternator_IGN

This signal indicates the command for switch the alternator ON.";
CM_ SG_ 2558560801 ADB_CMD_NBC_Press_Blackout "PIN = J5_OUT_2A_HS_0 (high side)
NBC_Press_Blackout

This signal is used to command the NBC Bloackout";
CM_ SG_ 2558560801 ADB_CMD_CTIS_Supply "PIN = J5_OUT_4A_HS_4 (high side)
CTIS_Supply (??A) VM
P/N = 5801726076

The signal shall be set by the BODY to define the CTIS supply request to the RUC.";
CM_ SG_ 2558560801 ADB_CMD_Water_Purge_VM "PIN = J5_OUT_2A_HS_2 (high side)
Water_Purge VM

The signal shall be set by the BODY to define the request of the Water Purge activation or deactivation.";
CM_ SG_ 2558560801 ADB_CMD_Buzzer "PIN = J5_OUT_2A_HS_3 (high side)
Buzzer
P/N = 475 2891

The signal shall be set by the BODY to define the Buzzer activation/deactivation request.";
CM_ SG_ 2558560801 ADB_CMD_NBC_Vent_160 "Signal used by the BODY to define the slow/NBC mode activation/deactivation request to the RUC.
J5_OUT_2A_HS_LS_0";
CM_ SG_ 2558560801 ADB_CMD_NBC_Vent_200 "Signal used by the BODY to define the fast/NBC mode activation/deactivation request to the RUC.
J5_OUT_2A_HS_LS_1";
CM_ BO_ 2558534028 "This message contains the versions installed in the RUR";
CM_ SG_ 2558534028 ADB_Param_Version_RUR "Versione dei parametri";
CM_ SG_ 2558534028 ADB_FPGA_Version_RUR "Versione FPGA";
CM_ SG_ 2558534028 ADB_SW_Version_RUR "Versione SW";
CM_ SG_ 2558534028 ADB_SW_Type_RUR "Tipo sw - per il progetto NBC il tipo sw deve essere 2.";
CM_ SG_ 2558534028 _nu_ADB_Network_Status_RUR "Network Status";
CM_ SG_ 2558534028 _nu_ADB_Can_TX_Error_Counter_RUR "CAN error counter";
CM_ SG_ 2558534028 _nu_ADB_Can_RX_Error_Counter_RUR "CAN error counter";
CM_ BO_ 2558534026 "This message contains the versions installed in the RUC";
CM_ SG_ 2558534026 ADB_Param_Version_RUC "Versione dei parametri";
CM_ SG_ 2558534026 ADB_FPGA_Version_RUC "Versione FPGA";
CM_ SG_ 2558534026 ADB_SW_Version_RUC "Versione SW";
CM_ SG_ 2558534026 ADB_SW_Type_RUC "Tipo sw - per il progetto NBC il tipo sw deve essere 2.";
CM_ SG_ 2558534026 _nu_ADB_Network_Status_RUC "Network Status";
CM_ SG_ 2558534026 _nu_ADB_Can_TX_Error_Counter_RUC "CAN error counter";
CM_ SG_ 2558534026 _nu_ADB_Can_RX_Error_Counter_RUC "CAN error counter";
CM_ BO_ 2558534025 "This message contains the versions installed in the RUF";
CM_ SG_ 2558534025 ADB_Param_Version_RUF "Versione dei parametri";
CM_ SG_ 2558534025 ADB_FPGA_Version_RUF "Versione FPGA";
CM_ SG_ 2558534025 ADB_SW_Version_RUF "Versione SW";
CM_ SG_ 2558534025 ADB_SW_Type_RUF "Tipo sw - per il progetto NBC il tipo sw deve essere 2.";
CM_ SG_ 2558534025 _nu_ADB_Network_Status_RUF "Network Status";
CM_ SG_ 2558534025 _nu_ADB_Can_TX_Error_Counter_RUF "CAN error counter";
CM_ SG_ 2558534025 _nu_ADB_Can_RX_Error_Counter_RUF "CAN error counter";
BA_DEF_ BO_  "GenMsgCycleTimeFast" INT 0 3600000;
BA_DEF_ BO_  "GenMsgDelayTime" INT 0 3600000;
BA_DEF_ BO_  "GenMsgStartDelayTime" INT 0 10000;
BA_DEF_ BO_  "GenMsgSendType" ENUM  "cyclic","reserved","cyclicIfActive","reserved","reserved","reserved","reserved","reserved","noMsgSendType";
BA_DEF_ BO_  "GenMsgCycleTime" INT 0 3600000;
BA_DEF_ BO_  "GenMsgILSupport" ENUM  "No","Yes";
BA_DEF_ BO_  "VFrameFormat" ENUM  "StandardCAN","ExtendedCAN","reserved","J1939PG";
BA_DEF_ BO_  "GenMsgSendTypex" ENUM  "cyclic","reserved","cyclicIfActive","reserved","reserved","reserved","reserved","reserved","noMsgSendType";
BA_DEF_ BO_  "GenMsgRequestable" INT 0 1;
BA_DEF_ BO_  "GenMsgSencmype" ENUM  "cyclic","reserved","cyclicIfActive","reserved","reserved","reserved","reserved","reserved","noMsgSencmype";
BA_DEF_ BO_  "GenMsgSencmypex" ENUM  "cyclic","reserved","cyclicIfActive","reserved","reserved","reserved","reserved","reserved","noMsgSencmype";
BA_DEF_ SG_  "GenSigSendType" ENUM  "Cyclic","OnWrite","reserved","OnChange","reserved","reserved","reserved","NoSigSendType";
BA_DEF_ SG_  "GenSigStartValue" INT 0 10000;
BA_DEF_ SG_  "GenSigEVName" STRING ;
BA_DEF_ SG_  "GenSigILSupport" ENUM  "Yes","No";
BA_DEF_ SG_  "GenSigSendTypex" ENUM  "Cyclic","OnWrite","reserved","OnChange","reserved","reserved","reserved","NoSigSendType";
BA_DEF_ SG_  "GenSigSencmype" ENUM  "Cyclic","OnWrite","reserved","OnChange","reserved","reserved","reserved","NoSigSencmype";
BA_DEF_ SG_  "GenSigSencmypex" ENUM  "Cyclic","OnWrite","reserved","OnChange","reserved","reserved","reserved","NoSigSencmype";
BA_DEF_ SG_  "SigType" ENUM  "Default","Range","RangeSigned","ASCII","Discrete","Control","ReferencePGN","DTC","StringDelimiter","StringLength","StringLengthControl";
BA_DEF_DEF_  "GenMsgCycleTimeFast" 0;
BA_DEF_DEF_  "GenMsgDelayTime" 0;
BA_DEF_DEF_  "GenMsgStartDelayTime" 0;
BA_DEF_DEF_  "GenMsgSendType" "noMsgSendType";
BA_DEF_DEF_  "GenMsgCycleTime" 0;
BA_DEF_DEF_  "GenMsgILSupport" "Yes";
BA_DEF_DEF_  "VFrameFormat" "J1939PG";
BA_DEF_DEF_  "GenMsgSendTypex" "noMsgSendType";
BA_DEF_DEF_  "GenMsgRequestable" 1;
BA_DEF_DEF_  "GenMsgSencmype" "noMsgSencmype";
BA_DEF_DEF_  "GenMsgSencmypex" "noMsgSencmype";
BA_DEF_DEF_  "GenSigSendType" "NoSigSendType";
BA_DEF_DEF_  "GenSigStartValue" 0;
BA_DEF_DEF_  "GenSigEVName" "Env@Nodename_@Signame";
BA_DEF_DEF_  "GenSigILSupport" "Yes";
BA_DEF_DEF_  "GenSigSendTypex" "NoSigSendType";
BA_DEF_DEF_  "GenSigSencmype" "NoSigSencmype";
BA_DEF_DEF_  "GenSigSencmypex" "NoSigSencmype";
BA_DEF_DEF_  "SigType" "Default";
BA_ "GenMsgSendType" BO_ 2566838305 2;
BA_ "GenMsgCycleTime" BO_ 2566838305 1000;
BA_ "GenMsgSendType" BO_ 2565865249 2;
BA_ "GenMsgCycleTime" BO_ 2565865249 1000;
BA_ "GenMsgSendType" BO_ 2565537569 2;
BA_ "GenMsgCycleTime" BO_ 2565537569 1000;
BA_ "GenMsgSendType" BO_ 2558590753 0;
BA_ "GenMsgCycleTime" BO_ 2558590753 100;
BA_ "GenMsgSendType" BO_ 2558861708 0;
BA_ "GenMsgCycleTime" BO_ 2558861708 100;
BA_ "GenMsgSendType" BO_ 2558796172 0;
BA_ "GenMsgCycleTime" BO_ 2558796172 100;
BA_ "GenMsgSendType" BO_ 2558730636 0;
BA_ "GenMsgCycleTime" BO_ 2558730636 100;
BA_ "GenMsgSendType" BO_ 2558665100 0;
BA_ "GenMsgCycleTime" BO_ 2558665100 100;
BA_ "GenMsgSendType" BO_ 2558599564 0;
BA_ "GenMsgCycleTime" BO_ 2558599564 100;
BA_ "GenMsgSendType" BO_ 2558626849 0;
BA_ "GenMsgCycleTime" BO_ 2558626849 100;
BA_ "GenMsgSendType" BO_ 2558561313 0;
BA_ "GenMsgCycleTime" BO_ 2558561313 100;
BA_ "GenMsgSendType" BO_ 2558861705 0;
BA_ "GenMsgCycleTime" BO_ 2558861705 100;
BA_ "GenMsgSendType" BO_ 2558796169 0;
BA_ "GenMsgCycleTime" BO_ 2558796169 100;
BA_ "GenMsgSendType" BO_ 2558730634 0;
BA_ "GenMsgCycleTime" BO_ 2558730634 100;
BA_ "GenMsgSendType" BO_ 2558665097 0;
BA_ "GenMsgCycleTime" BO_ 2558665097 100;
BA_ "GenMsgSendType" BO_ 2558599561 0;
BA_ "GenMsgCycleTime" BO_ 2558599561 100;
BA_ "GenMsgSendType" BO_ 2558626081 0;
BA_ "GenMsgCycleTime" BO_ 2558626081 100;
BA_ "GenMsgSendType" BO_ 2558560545 0;
BA_ "GenMsgCycleTime" BO_ 2558560545 100;
BA_ "GenMsgSendType" BO_ 2558861706 0;
BA_ "GenMsgCycleTime" BO_ 2558861706 100;
BA_ "GenMsgSendType" BO_ 2558796170 0;
BA_ "GenMsgCycleTime" BO_ 2558796170 100;
BA_ "GenMsgSendType" BO_ 2558730633 0;
BA_ "GenMsgCycleTime" BO_ 2558730633 100;
BA_ "GenMsgSendType" BO_ 2558665098 0;
BA_ "GenMsgCycleTime" BO_ 2558665098 100;
BA_ "GenMsgSendType" BO_ 2558599562 0;
BA_ "GenMsgCycleTime" BO_ 2558599562 100;
BA_ "GenMsgSendType" BO_ 2558626337 0;
BA_ "GenMsgCycleTime" BO_ 2558626337 100;
BA_ "GenMsgSendType" BO_ 2558560801 0;
BA_ "GenMsgCycleTime" BO_ 2558560801 100;
BA_ "GenMsgSendType" BO_ 2558534028 0;
BA_ "GenMsgCycleTime" BO_ 2558534028 1000;
BA_ "GenMsgSendType" BO_ 2558534026 0;
BA_ "GenMsgCycleTime" BO_ 2558534026 1000;
BA_ "GenMsgSendType" BO_ 2558534025 0;
BA_ "GenMsgCycleTime" BO_ 2558534025 1000;
BA_ "GenSigStartValue" SG_ 2566853374 BMS0_ADB_M1_Reserved_Cap 255;
BA_ "GenSigStartValue" SG_ 2566853118 BMS0_ADB_M2_Reserved_Cap 255;
BA_ "GenSigStartValue" SG_ 2566852862 BMS0_ADB_M3_Reserved_Cap 255;
BA_ "GenSigStartValue" SG_ 2566861054 BMS0_ADB_Maximum_Life_temp 1000;
BA_ "GenSigStartValue" SG_ 2566861054 BMS0_ADB_Minimum_Life_temp 1000;
BA_ "GenSigStartValue" SG_ 2566861054 BMS0_ADB_MAX_Charging_Temp 1000;
BA_ "GenSigStartValue" SG_ 2566861054 BMS0_ADB_MIN_Charging_Temp 1000;
BA_ "GenSigStartValue" SG_ 2566857470 BMS0_ADB_M3_Temperature_1 60;
BA_ "GenSigStartValue" SG_ 2566857470 BMS0_ADB_M3_Temperature_2 60;
BA_ "GenSigStartValue" SG_ 2566857470 BMS0_ADB_M3_Temperature_3 60;
BA_ "GenSigStartValue" SG_ 2566857470 BMS0_ADB_M3_Reserved_Dis1 255;
BA_ "GenSigStartValue" SG_ 2566857470 BMS0_ADB_M3_Reserved_Dis2 255;
BA_ "GenSigStartValue" SG_ 2566857214 BMS0_ADB_M2_Temperature_1 60;
BA_ "GenSigStartValue" SG_ 2566857214 BMS0_ADB_M2_Temperature_2 60;
BA_ "GenSigStartValue" SG_ 2566857214 BMS0_ADB_M2_Temperature_3 60;
BA_ "GenSigStartValue" SG_ 2566857214 BMS0_ADB_M2_Reserved_Dis1 255;
BA_ "GenSigStartValue" SG_ 2566857214 BMS0_ADB_M2_Reserved_Dis2 255;
BA_ "GenSigStartValue" SG_ 2566856958 BMS0_ADB_M1_Temperature_1 60;
BA_ "GenSigStartValue" SG_ 2566856958 BMS0_ADB_M1_Temperature_2 60;
BA_ "GenSigStartValue" SG_ 2566856958 BMS0_ADB_M1_Temperature_3 60;
BA_ "GenSigStartValue" SG_ 2566856958 BMS0_ADB_M1_Reserved_Dis1 255;
BA_ "GenSigStartValue" SG_ 2566856958 BMS0_ADB_M1_Reserved_Dis2 255;
BA_ "GenSigStartValue" SG_ 2566855422 BMS0_ADB_M3_FuelGauge1_Temp 1000;
BA_ "GenSigStartValue" SG_ 2566855422 BMS0_ADB_M3_Thermistor1_temp 1000;
BA_ "GenSigStartValue" SG_ 2566855422 BMS0_ADB_M3_Thermistor2_temp 1000;
BA_ "GenSigStartValue" SG_ 2566855422 BMS0_ADB_M3_FuelGauge2_Temp 1000;
BA_ "GenSigStartValue" SG_ 2566855166 BMS0_ADB_M2_FuelGauge1_Temp 1000;
BA_ "GenSigStartValue" SG_ 2566855166 BMS0_ADB_M2_Thermistor1_temp 1000;
BA_ "GenSigStartValue" SG_ 2566855166 BMS0_ADB_M2_Thermistor2_temp 1000;
BA_ "GenSigStartValue" SG_ 2566855166 BMS0_ADB_M2_FuelGauge2_Temp 1000;
BA_ "GenSigStartValue" SG_ 2566854910 BMS0_ADB_M1_FuelGauge1_Temp 1000;
BA_ "GenSigStartValue" SG_ 2566854910 BMS0_ADB_M1_Thermistor1_temp 1000;
BA_ "GenSigStartValue" SG_ 2566854910 BMS0_ADB_M1_Thermistor2_temp 1000;
BA_ "GenSigStartValue" SG_ 2566854910 BMS0_ADB_M1_FuelGauge2_Temp 1000;
BA_ "GenSigStartValue" SG_ 2566849278 BMS0_ADB_Maximum_Temperature 1000;
BA_ "GenSigStartValue" SG_ 2566849278 BMS0_ADB_Minimum_Temperature 1000;
BA_ "GenSigStartValue" SG_ 2566849278 BMS0_ADB_Average_Temperature 1000;
BA_ "GenSigStartValue" SG_ 2566848766 BMS0_ADB_Batt_Average_Current 55;
BA_ "GenSigStartValue" SG_ 2566803710 BMS0_ADB_Battery1_Temperature 40;
BA_ "GenSigStartValue" SG_ 2566803710 _nu_BMS0_ADB_Battery2_Temp 40;
BA_ "GenSigStartValue" SG_ 2582642465 BMS_ADB_ResetCommand 52;
BA_ "GenSigStartValue" SG_ 2565865249 BMS_ADB_Command_General_Param 1;
VAL_ 2566850046 BMS0_ADB_BatSumS_State_of_Health 3 "Health_is_wrong" 2 "Health_is_good" 1 "Health_is_medium" 0 "Health_is_poor" ;
VAL_ 2566850046 BMS0_ADB_BatSumS_Temp_Alarm 3 "Wrong_Temperature_Alarm" 2 "High_Temperature_Alarm" 1 "Low_Temperature_Alarm" 0 "No_fault" ;
VAL_ 2566850046 BMS0_ADB_BatSumS_DischargeDis 1 "Discharge_Disable" 0 "Discharge_Enable" ;
VAL_ 2566850046 BMS0_ADB_BatSumS_ChargingDisable 1 "Charging_Disable" 0 "Charging_Enable" ;
VAL_ 2566850046 BMS0_ADB_BatSumS_HeaterEnabled 1 "Heater_Enabled" 0 "Heater_Disabled" ;
VAL_ 2566850046 BMS0_ADB_BatSumS_BypassEnabled 1 "Bypass_Enabled" 0 "Bypass_Disabled" ;
VAL_ 2566850046 BMS0_ADB_BatSumS_Voltage_Alarm 1 "Active" 0 "NotActive" ;
VAL_ 2566851326 BMS0_ADB_M3_Module_StateOfHealth 3 "Health_is_wrong" 2 "Health_is_good" 1 "Health_is_medium" 0 "Health_is_poor" ;
VAL_ 2566851326 BMS0_ADB_M3_DiscProtectTrigg 1 "Fault_Present" 0 "No_Fault" ;
VAL_ 2566851326 BMS0_ADB_M3_ChargeProtectTrigg 1 "Fault_Present" 0 "No_Fault" ;
VAL_ 2566851326 BMS0_ADB_M3_ModulesMissingFailed 1 "Fault_Present" 0 "No_Fault" ;
VAL_ 2566851326 BMS0_ADB_M3_OverTemp_detect 1 "Fault_Present" 0 "No_Fault" ;
VAL_ 2566851326 BMS0_ADB_M3_UnderVoltage_detect 1 "Fault_Present" 0 "No_Fault" ;
VAL_ 2566851326 BMS0_ADB_M3_OverVoltage_detected 1 "Fault_Present" 0 "No_Fault" ;
VAL_ 2566851326 BMS0_ADB_M3_Overload_detected 1 "Fault_Present" 0 "No_Fault" ;
VAL_ 2566851326 BMS0_ADB_M3_ShortCircuit_detect 1 "Fault_Present" 0 "No_Fault" ;
VAL_ 2566851070 BMS0_ADB_M2_Module_StateOfHealth 3 "Health_is_wrong" 2 "Health_is_good" 1 "Health_is_medium" 0 "Health_is_poor" ;
VAL_ 2566851070 BMS0_ADB_M2_DiscProtectTrigg 1 "Fault_Present" 0 "No_Fault" ;
VAL_ 2566851070 BMS0_ADB_M2_ChargeProtectTrigg 1 "Fault_Present" 0 "No_Fault" ;
VAL_ 2566851070 BMS0_ADB_M2_ModulesMissingFailed 1 "Fault_Present" 0 "No_Fault" ;
VAL_ 2566851070 BMS0_ADB_M2_OverTemp_detect 1 "Fault_Present" 0 "No_Fault" ;
VAL_ 2566851070 BMS0_ADB_M2_UnderVoltage_detect 1 "Fault_Present" 0 "No_Fault" ;
VAL_ 2566851070 BMS0_ADB_M2_OverVoltage_detected 1 "Fault_Present" 0 "No_Fault" ;
VAL_ 2566851070 BMS0_ADB_M2_Overload_detected 1 "Fault_Present" 0 "No_Fault" ;
VAL_ 2566851070 BMS0_ADB_M2_ShortCircuit_detect 1 "Fault_Present" 0 "No_Fault" ;
VAL_ 2566850814 BMS0_ADB_M1_Module_StateOfHealth 3 "Health_is_wrong" 2 "Health_is_good" 1 "Health_is_medium" 0 "Health_is_poor" ;
VAL_ 2566850814 BMS0_ADB_M1_DiscProtectTrigg 1 "Fault_Present" 0 "No_Fault" ;
VAL_ 2566850814 BMS0_ADB_M1_ChargeProtectTrigg 1 "Fault_Present" 0 "No_Fault" ;
VAL_ 2566850814 BMS0_ADB_M1_ModulesMissingFailed 1 "Fault_Present" 0 "No_Fault" ;
VAL_ 2566850814 BMS0_ADB_M1_OverTemp_detect 1 "Fault_Present" 0 "No_Fault" ;
VAL_ 2566850814 BMS0_ADB_M1_UnderVoltage_detect 1 "Fault_Present" 0 "No_Fault" ;
VAL_ 2566850814 BMS0_ADB_M1_OverVoltage_detected 1 "Fault_Present" 0 "No_Fault" ;
VAL_ 2566850814 BMS0_ADB_M1_Overload_detected 1 "Fault_Present" 0 "No_Fault" ;
VAL_ 2566850814 BMS0_ADB_M1_ShortCircuit_detect 1 "Fault_Present" 0 "No_Fault" ;
VAL_ 2566849022 BMS0_ADB_Overall_10_alarm 1 "Alarm_ON" 0 "Alarm_OFF" ;
VAL_ 2566849022 BMS0_ADB_Silent_Watch_20_alarm 1 "Alarm_ON" 0 "Alarm_OFF" ;
VAL_ 2566849022 BMS0_ADB_EngStartCapacity_alarm 1 "Alarm_ON" 0 "Alarm_OFF" ;
VAL_ 2566848766 BMS0_ADB_Batt_StsOfHealth 3 "Health_is_wrong" 2 "Health_is_good" 1 "Health_is_medium" 0 "Health_is_poor" ;
VAL_ 2566848766 BMS0_ADB_Batt_PS8_discharge_prot 1 "Fault_Present" 0 "No_Fault" ;
VAL_ 2566848766 BMS0_ADB_Batt_PS7_charge_prot 1 "Fault_Present" 0 "No_Fault" ;
VAL_ 2566848766 BMS0_ADB_Batt_PS6_mod_failed 1 "Fault_Present" 0 "No_Fault" ;
VAL_ 2566848766 BMS0_ADB_Batt_PS5_over_temp 1 "Fault_Present" 0 "No_Fault" ;
VAL_ 2566848766 BMS0_ADB_Batt_PS4_under_voltage 1 "Fault_Present" 0 "No_Fault" ;
VAL_ 2566848766 BMS0_ADB_Batt_PS3_over_voltage 1 "Fault_Present" 0 "No_Fault" ;
VAL_ 2566848766 BMS0_ADB_Batt_PS2_overload 1 "Fault_Present" 0 "No_Fault" ;
VAL_ 2566848766 BMS0_ADB_Batt_PS1_short_circuit 1 "Fault_Present" 0 "No_Fault" ;
VAL_ 2566848766 BMS0_ADB_Batt_OS_8_sleep_mode 1 "Sleep_pending" 0 "Awake" ;
VAL_ 2566848766 BMS0_ADB_Batt_OS_7_emerg_used 1 "used" 0 "never_used" ;
VAL_ 2566848766 BMS0_ADB_Batt_OS_6_emergency 1 "Active" 0 "NotActive" ;
VAL_ 2566848766 BMS0_ADB_Batt_OS_45_charge_level 3 "100%" 2 "50%" 1 "25%" 0 "OFF" ;
VAL_ 2566848766 BMS0_ADB_Batt_OS_3_charge_cont 1 "ON" 0 "OFF" ;
VAL_ 2566848766 BMS0_ADB_Batt_OS_2_heater_cont 1 "ON" 0 "OFF" ;
VAL_ 2566848766 BMS0_ADB_Batt_OS_1_master_prot 1 "Protect" 0 "OFF" ;
VAL_ 2582642465 BMS_ADB_ResetCommand 82 "RESET_COMMAND" ;
VAL_ 2565865249 BMS_ADB_Command_Parameter_1 3 "Charger-100%" 2 "Charger-50%" 1 "Charger-25%_or_Heater-ON" 0 "Charger-0%_or_Heater-OFF" ;
VAL_ 2565865249 BMS_ADB_Command_General_Param 4 "Bypass_Command" 3 "Sleep_Command" 2 "ChargerCurrent_Command" 1 "Heater_Command" ;
VAL_ 2558590753 ADB_Hvac_Activation_Sts 3 "NOT_VALID" 2 "ERROR" 1 "REQUIRED" 0 "NOT_REQUIRED" ;
VAL_ 2558590753 ADB_Sync_Direction_Right 3 "NOT_VALID" 2 "BLINKING" 1 "ON" 0 "OFF" ;
VAL_ 2558590753 ADB_Sync_Direction_Left 3 "NOT_VALID" 2 "BLINKING" 1 "ON" 0 "OFF" ;
VAL_ 2558590753 ADB_Main_Power_Switch_Sts 3 "NOT_VALID" 2 "ERROR" 1 "INSERTED" 0 "NOT_INSERTED" ;
VAL_ 2558590753 ADB_Ignition_Switch_Sts 3 "NOT_VALID" 2 "ERROR" 1 "INSERTED" 0 "NOT_INSERTED" ;
VAL_ 2558590753 ADB_Blackout_Switch_Sts 3 "NOT_VALID" 2 "ERROR" 1 "BLACKOUT" 0 "NO_BLACKOUT" ;
VAL_ 2558590753 ADB_Extra_Battery_Switch_Sts 3 "NOT_VALID" 2 "ERROR" 1 "INSERTED" 0 "NOT_INSERTED" ;
VAL_ 2558590753 ADB_BC_Master_Slave_ID 3 "NOT_VALID" 2 "SLAVE" 1 "MASTER" 0 "UNKNOWN" ;
VAL_ 2558590753 ADB_BC_Network_Status 3 "NOT_USED" 2 "NET_SILENT" 1 "GOTO_SLEEP" 0 "NORMAL" ;
VAL_ 2558861708 ADB_STS_ALM_Left_Supply 3 "NOT_USED" 2 "OPEN_CIRCUIT" 1 "HIGH" 0 "LOW" ;
VAL_ 2558861708 ADB_STS_ALM_Right_Supply 3 "NOT_USED" 2 "OPEN_CIRCUIT" 1 "HIGH" 0 "LOW" ;
VAL_ 2558861708 ADB_STS_DirectionRearLeftLight 3 "NOT_USED" 2 "OPEN_CIRCUIT" 1 "HIGH" 0 "LOW" ;
VAL_ 2558861708 ADB_STS_LatLeftCameraPowerSup 3 "NOT_USED" 2 "OPEN_CIRCUIT" 1 "HIGH" 0 "LOW" ;
VAL_ 2558861708 ADB_STS_LatRightCameraPowerSup 3 "NOT_USED" 2 "OPEN_CIRCUIT" 1 "HIGH" 0 "LOW" ;
VAL_ 2558861708 ADB_STS_RearCameraPowerSup 3 "NOT_USED" 2 "OPEN_CIRCUIT" 1 "HIGH" 0 "LOW" ;
VAL_ 2558861708 ADB_STS_Payload_Dome_Light 3 "NOT_USED" 2 "OPEN_CIRCUIT" 1 "HIGH" 0 "LOW" ;
VAL_ 2558861708 ADB_STS_Payload_Dome_War_Light 3 "NOT_USED" 2 "OPEN_CIRCUIT" 1 "HIGH" 0 "LOW" ;
VAL_ 2558861708 ADB_STS_MarkerRearLeftLight 3 "NOT_USED" 2 "OPEN_CIRCUIT" 1 "HIGH" 0 "LOW" ;
VAL_ 2558861708 ADB_STS_MarkerRearLeftWarLight 3 "NOT_USED" 2 "OPEN_CIRCUIT" 1 "HIGH" 0 "LOW" ;
VAL_ 2558861708 ADB_STS_Stop_Left_War_Light 3 "NOT_USED" 2 "OPEN_CIRCUIT" 1 "HIGH" 0 "LOW" ;
VAL_ 2558861708 ADB_STS_Reverse_Left_Light 3 "NOT_USED" 2 "OPEN_CIRCUIT" 1 "HIGH" 0 "LOW" ;
VAL_ 2558861708 ADB_STS_Stop_Left_Light 3 "NOT_USED" 2 "OPEN_CIRCUIT" 1 "HIGH" 0 "LOW" ;
VAL_ 2558861708 ADB_STS_FES_Supply 3 "NOT_USED" 2 "OPEN_CIRCUIT" 1 "HIGH" 0 "LOW" ;
VAL_ 2558796172 ADB_STS_DirectionRearRightLight 3 "NOT_USED" 2 "OPEN_CIRCUIT" 1 "HIGH" 0 "LOW" ;
VAL_ 2558796172 ADB_STS_Stop_Right_Light 3 "NOT_USED" 2 "OPEN_CIRCUIT" 1 "HIGH" 0 "LOW" ;
VAL_ 2558796172 ADB_STS_Stop_Right_War_Light 3 "NOT_USED" 2 "OPEN_CIRCUIT" 1 "HIGH" 0 "LOW" ;
VAL_ 2558796172 ADB_STS_Camera_Washer_Pump_Rear 3 "NOT_USED" 2 "OPEN_CIRCUIT" 1 "HIGH" 0 "LOW" ;
VAL_ 2558796172 ADB_STS_Reverse_Right_Light 3 "NOT_USED" 2 "OPEN_CIRCUIT" 1 "HIGH" 0 "LOW" ;
VAL_ 2558796172 ADB_STS_SVS_PowerSupply 3 "NOT_USED" 2 "OPEN_CIRCUIT" 1 "HIGH" 0 "LOW" ;
VAL_ 2558796172 ADB_STS_MarkerRearRightWarLight 3 "NOT_USED" 2 "OPEN_CIRCUIT" 1 "HIGH" 0 "LOW" ;
VAL_ 2558796172 ADB_STS_MarkerRearRightLight 3 "NOT_USED" 2 "OPEN_CIRCUIT" 1 "HIGH" 0 "LOW" ;
VAL_ 2558796172 ADB_STS_MarkerLatLeftRightLight 3 "NOT_USED" 2 "OPEN_CIRCUIT" 1 "HIGH" 0 "LOW" ;
VAL_ 2558796172 ADB_STS_ALS_Left_Enable_SwPowSup 3 "NOT_USED" 2 "OPEN_CIRCUIT" 1 "HIGH" 0 "LOW" ;
VAL_ 2558796172 ADB_STS_ALS_RightEnableSwPowSup 3 "NOT_USED" 2 "OPEN_CIRCUIT" 1 "HIGH" 0 "LOW" ;
VAL_ 2558730636 ADB_IN_DIG_Payload_Door_Switch 3 "NOT_AVAILABLE" 2 "FAULT" 1 "OPEN" 0 "CLOSE" ;
VAL_ 2558730636 ADB_BLACKOUT_GND_RUR 3 "NOT_AVAILABLE" 2 "NOT_USED" 1 "BLACKOUT" 0 "NO_BLACKOUT" ;
VAL_ 2558730636 ADB_IN_DIG_PayloadHatchLeftSw 3 "NOT_AVAILABLE" 2 "FAULT" 1 "OPEN" 0 "CLOSE" ;
VAL_ 2558730636 ADB_IN_DIG_PayloadHatchRightSw 3 "NOT_AVAILABLE" 2 "FAULT" 1 "OPEN" 0 "CLOSE" ;
VAL_ 2558730636 ADB_IN_DIG_Rear_Door_Lock 3 "NOT_AVAILABLE" 2 "RESERVED" 1 "LOCKED" 0 "UNLOCKED" ;
VAL_ 2558730636 ADB_IN_DIG_Rear_Door_Switch 3 "NOT_AVAILABLE" 2 "RESERVED" 1 "OPEN" 0 "CLOSE" ;
VAL_ 2558730636 ADB_IN_DIG_ALSLeftEnableSw 3 "NOT_AVAILABLE" 2 "FAULT" 1 "OPEN" 0 "CLOSE" ;
VAL_ 2558730636 ADB_IN_DIG_ALSRightEnableSw 3 "NOT_AVAILABLE" 2 "FAULT" 1 "OPEN" 0 "CLOSE" ;
VAL_ 2558730636 ADB_IN_DIG_ALSLeftAmmLocked 3 "NOT_AVAILABLE" 2 "FAULT" 1 "OPEN" 0 "CLOSE" ;
VAL_ 2558730636 ADB_IN_DIG_ALSRightAmmLocked 3 "NOT_AVAILABLE" 2 "FAULT" 1 "OPEN" 0 "CLOSE" ;
VAL_ 2558626849 ADB_CMD_ALM_Left_Supply 3 "NOT_AVAILABLE" 2 "RESERVED" 1 "ON" 0 "OFF" ;
VAL_ 2558626849 ADB_CMD_ALM_Right_Supply 3 "NOT_AVAILABLE" 2 "RESERVED" 1 "ON" 0 "OFF" ;
VAL_ 2558626849 ADB_CMD_DirectionRearLeftLight 3 "NOT_AVAILABLE" 2 "BLINK" 1 "ON" 0 "OFF" ;
VAL_ 2558626849 ADB_CMD_LatLeftCameraPowerSup 3 "NOT_AVAILABLE" 2 "NOT_USED" 1 "ON" 0 "OFF" ;
VAL_ 2558626849 ADB_CMD_LatRightCameraPowerSup 3 "NOT_AVAILABLE" 2 "NOT_USED" 1 "ON" 0 "OFF" ;
VAL_ 2558626849 ADB_CMD_RearCameraPowerSup 3 "NOT_AVAILABLE" 2 "NOT_USED" 1 "ON" 0 "OFF" ;
VAL_ 2558626849 ADB_CMD_Payload_Dome_Light 3 "NOT_AVAILABLE" 2 "RESERVED" 1 "ON" 0 "OFF" ;
VAL_ 2558626849 ADB_CMD_Payload_Dome_War_Light 3 "NOT_AVAILABLE" 2 "RESERVED" 1 "ON" 0 "OFF" ;
VAL_ 2558626849 ADB_CMD_MarkerRearLeftLight 3 "NOT_AVAILABLE" 2 "RESERVED" 1 "ON" 0 "OFF" ;
VAL_ 2558626849 ADB_CMD_MarkerRearLeftWarLight 3 "NOT_AVAILABLE" 2 "RESERVED" 1 "ON" 0 "OFF" ;
VAL_ 2558626849 ADB_CMD_Stop_Left_War_Light 3 "NOT_AVAILABLE" 2 "BLINK" 1 "ON" 0 "OFF" ;
VAL_ 2558626849 ADB_CMD_Reverse_Left_Light 3 "NOT_AVAILABLE" 2 "RESERVED" 1 "ON" 0 "OFF" ;
VAL_ 2558626849 ADB_CMD_Stop_Left_Light 3 "NOT_AVAILABLE" 2 "BLINK" 1 "ON" 0 "OFF" ;
VAL_ 2558626849 ADB_CMD_HotWireStart_RUR 3 "NOT_AVAILABLE" 2 "RESERVED" 1 "ON" 0 "OFF" ;
VAL_ 2558561313 ADB_CMD_DirectionRearRightLight 3 "NOT_AVAILABLE" 2 "BLINK" 1 "ON" 0 "OFF" ;
VAL_ 2558561313 ADB_CMD_Stop_Right_Light 3 "NOT_AVAILABLE" 2 "BLINK" 1 "ON" 0 "OFF" ;
VAL_ 2558561313 ADB_CMD_Stop_Right_War_Light 3 "NOT_AVAILABLE" 2 "BLINK" 1 "ON" 0 "OFF" ;
VAL_ 2558561313 ADB_CMD_Camera_Washer_Pump_Rear 3 "NOT_AVAILABLE" 2 "RESERVED" 1 "ON" 0 "OFF" ;
VAL_ 2558561313 ADB_CMD_Reverse_Right_Light 3 "NOT_AVAILABLE" 2 "RESERVED" 1 "ON" 0 "OFF" ;
VAL_ 2558561313 ADB_CMD_SVS_PowerSupply 3 "NOT_AVAILABLE" 2 "RESERVED" 1 "ON" 0 "OFF" ;
VAL_ 2558561313 ADB_CMD_MarkerRearRightWarLight 3 "NOT_AVAILABLE" 2 "RESERVED" 1 "ON" 0 "OFF" ;
VAL_ 2558561313 ADB_CMD_MarkerRearRightLight 3 "NOT_AVAILABLE" 2 "RESERVED" 1 "ON" 0 "OFF" ;
VAL_ 2558561313 ADB_CMD_MarkerLatLeftRightLight 3 "NOT_AVAILABLE" 2 "RESERVED" 1 "ON" 0 "OFF" ;
VAL_ 2558561313 ADB_CMD_ALS_Left_Enable_SwPowSup 3 "NOT_AVAILABLE" 2 "RESERVED" 1 "ON" 0 "OFF" ;
VAL_ 2558561313 ADB_CMD_ALSRightEnableSwPowSup 3 "NOT_AVAILABLE" 2 "RESERVED" 1 "ON" 0 "OFF" ;
VAL_ 2558861705 ADB_STS_EngAreaHeaterWaterValve 3 "NOT_USED" 2 "OPEN_CIRCUIT" 1 "HIGH" 0 "LOW" ;
VAL_ 2558861705 ADB_STS_AC_Compressor_Clutch 3 "NOT_USED" 2 "OPEN_CIRCUIT" 1 "HIGH" 0 "LOW" ;
VAL_ 2558861705 ADB_STS_Air_Dryer 3 "NOT_USED" 2 "OPEN_CIRCUIT" 1 "HIGH" 0 "LOW" ;
VAL_ 2558861705 ADB_STS_Vacuum_pump_Valve 3 "NOT_USED" 2 "OPEN_CIRCUIT" 1 "HIGH" 0 "LOW" ;
VAL_ 2558861705 ADB_STS_Horn 3 "NOT_USED" 2 "OPEN_CIRCUIT" 1 "HIGH" 0 "LOW" ;
VAL_ 2558861705 ADB_STS_CrewAreaHeaterWaterValve 3 "NOT_USED" 2 "OPEN_CIRCUIT" 1 "HIGH" 0 "LOW" ;
VAL_ 2558861705 ADB_STS_MarkerFrontWarleftLights 3 "NOT_USED" 2 "OPEN_CIRCUIT" 1 "HIGH" 0 "LOW" ;
VAL_ 2558861705 ADB_STS_MarkerFrontWarRLights 3 "NOT_USED" 2 "OPEN_CIRCUIT" 1 "HIGH" 0 "LOW" ;
VAL_ 2558861705 ADB_STS_MechanicalPartsPresValve 3 "NOT_USED" 2 "OPEN_CIRCUIT" 1 "HIGH" 0 "LOW" ;
VAL_ 2558861705 ADB_STS_Front_Wheel_Drive_Valve 3 "NOT_USED" 2 "OPEN_CIRCUIT" 1 "HIGH" 0 "LOW" ;
VAL_ 2558861705 ADB_STS_Diff_Lock_Front_Valve 3 "NOT_USED" 2 "OPEN_CIRCUIT" 1 "HIGH" 0 "LOW" ;
VAL_ 2558861705 ADB_STS_Parking_Brake_Valve 3 "NOT_USED" 2 "OPEN_CIRCUIT" 1 "HIGH" 0 "LOW" ;
VAL_ 2558861705 ADB_STS_CentralCameraPowSup 3 "NOT_USED" 2 "OPEN_CIRCUIT" 1 "HIGH" 0 "LOW" ;
VAL_ 2558861705 ADB_STS_FrontCamerasPowSup 3 "NOT_USED" 2 "OPEN_CIRCUIT" 1 "HIGH" 0 "LOW" ;
VAL_ 2558796169 ADB_STS_SteeringValve 3 "NOT_USED" 2 "OPEN_CIRCUIT" 1 "HIGH" 0 "LOW" ;
VAL_ 2558796169 ADB_STS_Front_Fuel_Pump_1 3 "NOT_USED" 2 "OPEN_CIRCUIT" 1 "HIGH" 0 "LOW" ;
VAL_ 2558796169 ADB_STS_Front_Fuel_Pump_2 3 "NOT_USED" 2 "OPEN_CIRCUIT" 1 "HIGH" 0 "LOW" ;
VAL_ 2558796169 ADB_STS_LowBeam_Left_Light 3 "NOT_USED" 2 "OPEN_CIRCUIT" 1 "HIGH" 0 "LOW" ;
VAL_ 2558796169 ADB_STS_HighBeam_Left_Light 3 "NOT_USED" 2 "OPEN_CIRCUIT" 1 "HIGH" 0 "LOW" ;
VAL_ 2558796169 ADB_STS_LowBeam_Right_Light 3 "NOT_USED" 2 "OPEN_CIRCUIT" 1 "HIGH" 0 "LOW" ;
VAL_ 2558796169 ADB_STS_HighBeam_Right_Light 3 "NOT_USED" 2 "OPEN_CIRCUIT" 1 "HIGH" 0 "LOW" ;
VAL_ 2558796169 ADB_STS_ProjectorWarLeftLights 3 "NOT_USED" 2 "OPEN_CIRCUIT" 1 "HIGH" 0 "LOW" ;
VAL_ 2558796169 ADB_STS_Fuel_Circuit_Valve 3 "NOT_USED" 2 "OPEN_CIRCUIT" 1 "HIGH" 0 "LOW" ;
VAL_ 2558796169 ADB_STS_LockAlignRelValve 3 "NOT_USED" 2 "OPEN_CIRCUIT" 1 "HIGH" 0 "LOW" ;
VAL_ 2558796169 ADB_STS_DirectionRightLatLigh 3 "NOT_USED" 2 "OPEN_CIRCUIT" 1 "HIGH" 0 "LOW" ;
VAL_ 2558796169 ADB_STS_DirectionLeftLatLight 3 "NOT_USED" 2 "OPEN_CIRCUIT" 1 "HIGH" 0 "LOW" ;
VAL_ 2558796169 ADB_STS_DirectionRightFrontLight 3 "NOT_USED" 2 "OPEN_CIRCUIT" 1 "HIGH" 0 "LOW" ;
VAL_ 2558796169 ADB_STS_DirectionLeftFrontLight 3 "NOT_USED" 2 "OPEN_CIRCUIT" 1 "HIGH" 0 "LOW" ;
VAL_ 2558796169 ADB_STS_MarkerFrontleftLights 3 "NOT_USED" 2 "OPEN_CIRCUIT" 1 "HIGH" 0 "LOW" ;
VAL_ 2558796169 ADB_STS_MarkerFrontRightLights 3 "NOT_USED" 2 "OPEN_CIRCUIT" 1 "HIGH" 0 "LOW" ;
VAL_ 2558796169 ADB_STS_Dust_Extraction_Fan 3 "NOT_USED" 2 "OPEN_CIRCUIT" 1 "HIGH" 0 "LOW" ;
VAL_ 2558796169 ADB_STS_Engine_Bay_Bilge_Pump 3 "NOT_USED" 2 "OPEN_CIRCUIT" 1 "HIGH" 0 "LOW" ;
VAL_ 2558796169 ADB_STS_Fuel_Prefilter_Heater 3 "NOT_USED" 2 "OPEN_CIRCUIT" 1 "HIGH" 0 "LOW" ;
VAL_ 2558730634 ADB_IN_DIG_Cmd_K15 3 "NOT_AVAILABLE" 2 "NOT_USED" 1 "K15_ON" 0 "K15_OFF" ;
VAL_ 2558730634 ADB_IN_DIG_Cmd_NBC 3 "NOT_AVAILABLE" 2 "NOT_USED" 1 "NBC_ON" 0 "NBC_OFF" ;
VAL_ 2558730634 ADB_IN_DIG_DriverHatchSw2 3 "NOT_AVAILABLE" 2 "FAULT" 1 "OPEN" 0 "CLOSE" ;
VAL_ 2558730634 ADB_IN_DIG_DirectionLightsSwitch 3 "NOT_AVAILABLE" 2 "IDLE" 1 "LEFT" 0 "RIGHT" ;
VAL_ 2558730634 ADB_IN_DIG_HighBeamLightsSw 3 "NOT_AVAILABLE" 2 "IDLE" 1 "FLASH" 0 "HIGH_BEAM" ;
VAL_ 2558730634 ADB_IN_DIG_Fire_Ventilation 3 "NOT_AVAILABLE" 2 "NOT_USED" 1 "NOT_ALARM" 0 "ALARM" ;
VAL_ 2558730634 ADB_IN_DIG_PneumaticParkBrakeSw 3 "NOT_AVAILABLE" 2 "NOT_USED" 1 "BRAKED" 0 "NOT_BRAKED" ;
VAL_ 2558730634 ADB_IN_DIG_Engine_Start_Button 3 "NOT_AVAILABLE" 2 "NOT_USED" 1 "PRESSED" 0 "RELEASED" ;
VAL_ 2558730634 ADB_IN_DIG_Starter_Override 3 "NOT_AVAILABLE" 2 "NOT_USED" 1 "PRESSED" 0 "RELEASED" ;
VAL_ 2558730634 ADB_IN_DIG_Horn_Switch 3 "NOT_AVAILABLE" 2 "NOT_USED" 1 "PRESSED" 0 "RELEASED" ;
VAL_ 2558730634 ADB_IN_DIG_Front_Camera_Washer 3 "NOT_AVAILABLE" 2 "NOT_USED" 1 "RELEASED" 0 "PRESSED" ;
VAL_ 2558730634 ADB_IN_DIG_Central_Camera_Washer 3 "NOT_AVAILABLE" 2 "NOT_USED" 1 "RELEASED" 0 "PRESSED" ;
VAL_ 2558730634 ADB_IN_DIG_Lateral_Camera_Washer 3 "NOT_AVAILABLE" 2 "NOT_USED" 1 "RELEASED" 0 "PRESSED" ;
VAL_ 2558730634 ADB_BLACKOUT_GND_RUC 3 "NOT_AVAILABLE" 2 "NOT_USED" 1 "BLACKOUT" 0 "NO_BLACKOUT" ;
VAL_ 2558665097 ADB_IN_ANA_MechParkingBrakeSw 3 "NOT_AVAILABLE" 2 "NOT_USED" 1 "BRAKED" 0 "NOT_BRAKED" ;
VAL_ 2558665097 ADB_IN_ANA_FrontWheelDriveLeftSw 3 "NOT_USED" 2 "NOT_USED" 1 "NOT_ENGAGED" 0 "ENGAGED" ;
VAL_ 2558599561 ADB_IN_ANA_RearAxleAlignedLockSw 3 "NOT_AVAILABLE" 2 "NOT_USED" 1 "NOT_ALIGNED" 0 "ALIGNED" ;
VAL_ 2558599561 ADB_IN_ANA_AirFilter_Clogged 3 "NOT_AVAILABLE" 2 "NOT_USED" 1 "CLOGGED" 0 "NOT_CLOGGED" ;
VAL_ 2558599561 ADB_IN_ANA_FuelLevelHighFrontSw 3 "NOT_AVAILABLE" 2 "FAULT" 1 "HIGH_FUEL" 0 "OK" ;
VAL_ 2558626081 ADB_CMD_AC_Compressor_Clutch 3 "NOT_AVAILABLE" 2 "RESERVED" 1 "ON" 0 "OFF" ;
VAL_ 2558626081 ADB_CMD_Air_Dryer 3 "NOT_AVAILABLE" 2 "RESERVED" 1 "ON" 0 "OFF" ;
VAL_ 2558626081 ADB_CMD_Vacuum_pump_Valve 3 "NOT_AVAILABLE" 2 "RESERVED" 1 "ON" 0 "OFF" ;
VAL_ 2558626081 ADB_CMD_Horn 3 "NOT_AVAILABLE" 2 "RESERVED" 1 "ON" 0 "OFF" ;
VAL_ 2558626081 ADB_CMD_Camera_Washer_Pump_Front 3 "NOT_AVAILABLE" 2 "RESERVED" 1 "ON" 0 "OFF" ;
VAL_ 2558626081 ADB_CMD_EngAreaHeaterWaterValve 3 "NOT_AVAILABLE" 2 "RESERVED" 1 "ON" 0 "OFF" ;
VAL_ 2558626081 ADB_CMD_CrewAreaHeaterWaterValve 3 "NOT_AVAILABLE" 2 "RESERVED" 1 "ON" 0 "OFF" ;
VAL_ 2558626081 ADB_CMD_MarkerFrontWarLeftLights 3 "NOT_AVAILABLE" 2 "RESERVED" 1 "ON" 0 "OFF" ;
VAL_ 2558626081 ADB_CMD_MarkerFrontWarRLights 3 "NOT_AVAILABLE" 2 "RESERVED" 1 "ON" 0 "OFF" ;
VAL_ 2558626081 ADB_CMD_MechanicalPartsPresValve 3 "NOT_AVAILABLE" 2 "RESERVED" 1 "ON" 0 "OFF" ;
VAL_ 2558626081 ADB_CMD_Front_Wheel_Drive_Valve 3 "NOT_AVAILABLE" 2 "RESERVED" 1 "ON" 0 "OFF" ;
VAL_ 2558626081 ADB_CMD_Diff_Lock_Front_Valve 3 "NOT_AVAILABLE" 2 "RESERVED" 1 "ON" 0 "OFF" ;
VAL_ 2558626081 ADB_CMD_MechParking_Brake_Valve 3 "NOT_AVAILABLE" 2 "RESERVED" 1 "ON" 0 "OFF" ;
VAL_ 2558626081 ADB_CMD_HotWireStart_RUF 3 "NOT_AVAILABLE" 2 "RESERVED" 1 "ON" 0 "OFF" ;
VAL_ 2558626081 ADB_CMD_CentralCameraPowSup 3 "NOT_AVAILABLE" 2 "RESERVED" 1 "ON" 0 "OFF" ;
VAL_ 2558626081 ADB_CMD_FrontCamerasPowSup 3 "NOT_AVAILABLE" 2 "RESERVED" 1 "ON" 0 "OFF" ;
VAL_ 2558560545 ADB_CMD_Front_Fuel_Pump_1 3 "NOT_AVAILABLE" 2 "RESERVED" 1 "ON" 0 "OFF" ;
VAL_ 2558560545 ADB_CMD_Front_Fuel_Pump_2 3 "NOT_AVAILABLE" 2 "RESERVED" 1 "ON" 0 "OFF" ;
VAL_ 2558560545 ADB_CMD_LowBeam_Left_Light 3 "NOT_AVAILABLE" 2 "RESERVED" 1 "ON" 0 "OFF" ;
VAL_ 2558560545 ADB_CMD_HighBeam_Left_Light 3 "NOT_AVAILABLE" 2 "RESERVED" 1 "ON" 0 "OFF" ;
VAL_ 2558560545 ADB_CMD_LowBeam_Right_Light 3 "NOT_AVAILABLE" 2 "RESERVED" 1 "ON" 0 "OFF" ;
VAL_ 2558560545 ADB_CMD_HighBeam_Right_Light 3 "NOT_AVAILABLE" 2 "RESERVED" 1 "ON" 0 "OFF" ;
VAL_ 2558560545 ADB_CMD_ProjectorWarLights 3 "NOT_AVAILABLE" 2 "RESERVED" 1 "ON" 0 "OFF" ;
VAL_ 2558560545 ADB_CMD_Fuel_Circuit_Valve 3 "NOT_AVAILABLE" 2 "RESERVED" 1 "ON" 0 "OFF" ;
VAL_ 2558560545 ADB_CMD_LockAlignRelValve 3 "NOT_AVAILABLE" 2 "RESERVED" 1 "ON" 0 "OFF" ;
VAL_ 2558560545 ADB_CMD_DirectionRightLatLigh 3 "NOT_AVAILABLE" 2 "BLINK" 1 "ON" 0 "OFF" ;
VAL_ 2558560545 ADB_CMD_DirectionLeftLatLight 3 "NOT_AVAILABLE" 2 "BLINK" 1 "ON" 0 "OFF" ;
VAL_ 2558560545 ADB_CMD_DirectionRightFrontLight 3 "NOT_AVAILABLE" 2 "BLINK" 1 "ON" 0 "OFF" ;
VAL_ 2558560545 ADB_CMD_DirectionLeftFrontLight 3 "NOT_AVAILABLE" 2 "BLINK" 1 "ON" 0 "OFF" ;
VAL_ 2558560545 ADB_CMD_MarkerFrontLeftLights 3 "NOT_AVAILABLE" 2 "RESERVED" 1 "ON" 0 "OFF" ;
VAL_ 2558560545 ADB_CMD_MarkerFrontRightLights 3 "NOT_AVAILABLE" 2 "RESERVED" 1 "ON" 0 "OFF" ;
VAL_ 2558560545 ADB_CMD_Dust_Extraction_Fan 3 "NOT_AVAILABLE" 2 "RESERVED" 1 "ON" 0 "OFF" ;
VAL_ 2558560545 ADB_CMD_Engine_Bay_Bilge_Pump 3 "NOT_AVAILABLE" 2 "RESERVED" 1 "ON" 0 "OFF" ;
VAL_ 2558560545 ADB_CMD_Fuel_Prefilter_Heater 3 "NOT_AVAILABLE" 2 "RESERVED" 1 "ON" 0 "OFF" ;
VAL_ 2558861706 ADB_STS_Cmd_Heater 3 "NOT_USED" 2 "OPEN_CIRCUIT" 1 "HIGH" 0 "LOW" ;
VAL_ 2558861706 ADB_STS_Sights_Washer_Pump 3 "NOT_USED" 2 "OPEN_CIRCUIT" 1 "HIGH" 0 "LOW" ;
VAL_ 2558861706 ADB_STS_Camera_Washer_Pump_Cent 3 "NOT_USED" 2 "OPEN_CIRCUIT" 1 "HIGH" 0 "LOW" ;
VAL_ 2558861706 ADB_STS_LED_Enable 3 "NOT_AVAILABLE" 2 "ON_LOW" 1 "ON_HIGH" 0 "OFF" ;
VAL_ 2558861706 ADB_STS_Monitors_Supply 3 "NOT_USED" 2 "OPEN_CIRCUIT" 1 "HIGH" 0 "LOW" ;
VAL_ 2558861706 ADB_STS_Driver_Dome_Light 3 "NOT_USED" 2 "OPEN_CIRCUIT" 1 "HIGH" 0 "LOW" ;
VAL_ 2558861706 ADB_STS_Driver_Dome_War_Light 3 "NOT_USED" 2 "OPEN_CIRCUIT" 1 "HIGH" 0 "LOW" ;
VAL_ 2558861706 ADB_STS_Sights_Dryer_Valve 3 "NOT_USED" 2 "OPEN_CIRCUIT" 1 "HIGH" 0 "LOW" ;
VAL_ 2558861706 ADB_STS_Logbox_Supply 3 "NOT_USED" 2 "OPEN_CIRCUIT" 1 "HIGH" 0 "LOW" ;
VAL_ 2558796170 ADB_STS_Engine_Starter_Relay 3 "NOT_USED" 2 "OPEN_CIRCUIT" 1 "HIGH" 0 "LOW" ;
VAL_ 2558796170 ADB_STS_Main_Power_Relay 3 "NOT_USED" 2 "OPEN_CIRCUIT" 1 "HIGH" 0 "LOW" ;
VAL_ 2558796170 ADB_STS_Extra_battery_Relay 3 "NOT_USED" 2 "OPEN_CIRCUIT" 1 "HIGH" 0 "LOW" ;
VAL_ 2558796170 ADB_STS_NC_sensor_power_supply 3 "NOT_USED" 2 "OPEN_CIRCUIT" 1 "HIGH" 0 "LOW" ;
VAL_ 2558796170 ADB_STS_Alternator_IGN 3 "NOT_USED" 2 "OPEN_CIRCUIT" 1 "HIGH" 0 "LOW" ;
VAL_ 2558796170 ADB_STS_NBC_Press_Blackout 3 "NOT_USED" 2 "OPEN_CIRCUIT" 1 "HIGH" 0 "LOW" ;
VAL_ 2558796170 ADB_STS_CTIS_Supply 3 "NOT_USED" 2 "OPEN_CIRCUIT" 1 "HIGH" 0 "LOW" ;
VAL_ 2558796170 ADB_STS_Water_Purge_VM 3 "NOT_USED" 2 "OPEN_CIRCUIT" 1 "HIGH" 0 "LOW" ;
VAL_ 2558796170 ADB_STS_Buzzer 3 "NOT_USED" 2 "OPEN_CIRCUIT" 1 "HIGH" 0 "LOW" ;
VAL_ 2558796170 ADB_STS_NBC_Vent_160 3 "NOT_AVAILABLE" 2 "ON_LOW" 1 "ON_HIGH" 0 "OFF" ;
VAL_ 2558796170 ADB_STS_NBC_Vent_200 3 "NOT_AVAILABLE" 2 "ON_LOW" 1 "ON_HIGH" 0 "OFF" ;
VAL_ 2558730633 ADB_IN_DIG_BrakeCirc1LowOilPress 3 "NOT_AVAILABLE" 2 "FAULT" 1 "LOW_PRESSURE" 0 "PRESSURE_OK" ;
VAL_ 2558730633 ADB_IN_DIG_BrakeCirc2LowOilPress 3 "NOT_AVAILABLE" 2 "FAULT" 1 "LOW_PRESSURE" 0 "PRESSURE_OK" ;
VAL_ 2558730633 ADB_IN_DIG_BrakeOilLevelEngComp 3 "NOT_AVAILABLE" 2 "NOT_USED" 1 "LEVEL_OK" 0 "LOW_LEVEL" ;
VAL_ 2558730633 ADB_IN_DIG_DiffLockSwFrontAxle 3 "NOT_AVAILABLE" 2 "NOT_USED" 1 "NOT_ENGAGED" 0 "ENGAGED" ;
VAL_ 2558730633 ADB_IN_DIG_Front_Axle_Aligned 3 "NOT_AVAILABLE" 2 "NOT_USED" 1 "ALIGNED" 0 "NOT_ALIGNED" ;
VAL_ 2558730633 ADB_IN_DIG_FrontWheelDriveRSw 3 "NOT_AVAILABLE" 2 "NOT_USED" 1 "NOT_ENGAGED" 0 "ENGAGED" ;
VAL_ 2558730633 ADB_IN_DIG_FuelPreFilterClogSw 3 "NOT_AVAILABLE" 2 "NOT_USED" 1 "CLOGGED" 0 "FILTER_OK" ;
VAL_ 2558730633 ADB_IN_DIG_LowFlowPowSteeringSw 3 "NOT_AVAILABLE" 2 "NOT_USED" 1 "NO_ALARM" 0 "ALARM" ;
VAL_ 2558730633 ADB_IN_DIG_LowPressPowSteering1 3 "NOT_AVAILABLE" 2 "NOT_USED" 1 "PRESSURE_OK" 0 "LOW_PRESSURE" ;
VAL_ 2558730633 ADB_IN_DIG_LowPressPowSteering2 3 "NOT_AVAILABLE" 2 "NOT_USED" 1 "PRESSURE_OK" 0 "LOW_PRESSURE" ;
VAL_ 2558730633 ADB_IN_DIG_MechanicalPartsPresSw 3 "NOT_AVAILABLE" 2 "NOT_USED" 1 "NOT_PRESSURIZED" 0 "PRESSURIZED" ;
VAL_ 2558730633 ADB_IN_DIG_PowSteeringOilLevelSw 3 "NOT_AVAILABLE" 2 "NOT_USED" 1 "LOW_LEVEL" 0 "LEVEL_OK" ;
VAL_ 2558730633 ADB_IN_DIG_ServicesAirPressureSw 3 "NOT_AVAILABLE" 2 "NOT_USED" 1 "PRESSURE_OK" 0 "LOW_PRESSURE" ;
VAL_ 2558730633 ADB_BLACKOUT_GND_RUF 3 "NOT_AVAILABLE" 2 "NOT_USED" 1 "BLACKOUT" 0 "NO_BLACKOUT" ;
VAL_ 2558730633 ADB_IN_DIG_MechanicalParkBrake 3 "NOT_AVAILABLE" 2 "NOT_USED" 1 "NOT_REQUESTED" 0 "REQUESTED" ;
VAL_ 2558665098 ADB_IN_ANA_NBC_Fault 3 "NOT_AVAILABLE" 2 "NOT_USED" 1 "NO_ALARM" 0 "ALARM_OVERTEMPERATURE_OR_BLOCKED" ;
VAL_ 2558665098 ADB_IN_ANA_NBC_Low_Press 3 "NOT_AVAILABLE" 2 "NOT_USED" 1 "LOW_PRESSURE" 0 "PRESSURE_OK" ;
VAL_ 2558665098 ADB_IN_ANA_DriverHatchSw1 3 "NOT_AVAILABLE" 2 "FAULT" 1 "OPEN" 0 "CLOSE" ;
VAL_ 2558665098 ADB_IN_ANA_RetarderDown 3 "NOT_AVAILABLE" 2 "NOT_USED" 1 "NOT_REQUESTED" 0 "REQUESTED" ;
VAL_ 2558665098 ADB_IN_ANA_RetarderUp 3 "NOT_AVAILABLE" 2 "NOT_USED" 1 "NOT_REQUESTED" 0 "REQUESTED" ;
VAL_ 2558599562 ADB_IN_ANA_RetarderOnOff 3 "NOT_AVAILABLE" 2 "NOT_USED" 1 "NOT_REQUESTED" 0 "REQUESTED" ;
VAL_ 2558599562 ADB_IN_ANA_FireSensorEngineBay 3 "NOT_AVAILABLE" 2 "NOT_USED" 1 "ALARM" 0 "NOT_ALARM" ;
VAL_ 2558599562 ADB_IN_ANA_Main_power_switch 3 "NOT_AVAILABLE" 2 "NOT_USED" 1 "ACTIVE" 0 "NOT_ACTIVE" ;
VAL_ 2558599562 ADB_IN_ANA_Extra_battery_switch 3 "NOT_AVAILABLE" 2 "NOT_USED" 1 "ACTIVE" 0 "NOT_ACTIVE" ;
VAL_ 2558599562 ADB_IN_ANA_NBC_Prefilter_Clogged 3 "NOT_AVAILABLE" 2 "NOT_USED" 1 "NO_ALARM" 0 "ALARM" ;
VAL_ 2558599562 ADB_IN_ANA_NBC_Filter_Clogged 3 "NOT_AVAILABLE" 2 "NOT_USED" 1 "NO_ALARM" 0 "ALARM" ;
VAL_ 2558599562 ADB_IN_ANA_NBC_Mode 3 "NOT_AVAILABLE" 2 "NOT_USED" 1 "NBC_OFF" 0 "NBC_ON" ;
VAL_ 2558599562 ADB_IN_ANA_Sight_Washer_Request 3 "NOT_AVAILABLE" 2 "NOT_USED" 1 "NOT_REQUESTED" 0 "REQUESTED" ;
VAL_ 2558626337 ADB_CMD_Cmd_Heater 3 "NOT_AVAILABLE" 2 "RESERVED" 1 "ON" 0 "OFF" ;
VAL_ 2558626337 ADB_CMD_Sights_Washer_Pump 3 "NOT_AVAILABLE" 2 "RESERVED" 1 "ON" 0 "OFF" ;
VAL_ 2558626337 ADB_CMD_Camera_Washer_Pump_Cent 3 "NOT_AVAILABLE" 2 "RESERVED" 1 "ON" 0 "OFF" ;
VAL_ 2558626337 ADB_CMD_LED_Enable 3 "NOT_AVAILABLE" 2 "ON_LOW" 1 "ON_HIGH" 0 "OFF" ;
VAL_ 2558626337 ADB_CMD_Monitors_Supply 3 "NOT_AVAILABLE" 2 "RESERVED" 1 "ON" 0 "OFF" ;
VAL_ 2558626337 ADB_CMD_Driver_Dome_Light 3 "NOT_AVAILABLE" 2 "RESERVED" 1 "ON" 0 "OFF" ;
VAL_ 2558626337 ADB_CMD_Driver_Dome_War_Light 3 "NOT_AVAILABLE" 2 "RESERVED" 1 "ON" 0 "OFF" ;
VAL_ 2558626337 ADB_CMD_Sights_Dryer_Valve 3 "NOT_AVAILABLE" 2 "RESERVED" 1 "ON" 0 "OFF" ;
VAL_ 2558626337 ADB_CMD_Logbox_Supply 3 "NOT_AVAILABLE" 2 "RESERVED" 1 "ON" 0 "OFF" ;
VAL_ 2558626337 ADB_CMD_HotWireStart_RUC 3 "NOT_AVAILABLE" 2 "RESERVED" 1 "ON" 0 "OFF" ;
VAL_ 2558560801 ADB_CMD_Engine_Starter_Relay 3 "NOT_AVAILABLE" 2 "RESERVED" 1 "ON" 0 "OFF" ;
VAL_ 2558560801 ADB_CMD_Main_Power_Relay 3 "NOT_AVAILABLE" 2 "RESERVED" 1 "ON" 0 "OFF" ;
VAL_ 2558560801 ADB_CMD_Extra_battery_Relay 3 "NOT_AVAILABLE" 2 "RESERVED" 1 "ON" 0 "OFF" ;
VAL_ 2558560801 ADB_CMD_NC_sensor_power_supply 3 "NOT_AVAILABLE" 2 "RESERVED" 1 "ON" 0 "OFF" ;
VAL_ 2558560801 ADB_CMD_Alternator_IGN 3 "NOT_AVAILABLE" 2 "RESERVED" 1 "ON" 0 "OFF" ;
VAL_ 2558560801 ADB_CMD_NBC_Press_Blackout 3 "NOT_AVAILABLE" 2 "RESERVED" 1 "ON" 0 "OFF" ;
VAL_ 2558560801 ADB_CMD_CTIS_Supply 3 "NOT_AVAILABLE" 2 "RESERVED" 1 "ON" 0 "OFF" ;
VAL_ 2558560801 ADB_CMD_Water_Purge_VM 3 "NOT_AVAILABLE" 2 "RESERVED" 1 "ON" 0 "OFF" ;
VAL_ 2558560801 ADB_CMD_Buzzer 3 "NOT_AVAILABLE" 2 "RESERVED" 1 "ON" 0 "OFF" ;
VAL_ 2558560801 ADB_CMD_NBC_Vent_160 3 "NOT_AVAILABLE" 2 "ON_LOW" 1 "ON_HIGH" 0 "OFF" ;
VAL_ 2558560801 ADB_CMD_NBC_Vent_200 3 "NOT_AVAILABLE" 2 "ON_LOW" 1 "ON_HIGH" 0 "OFF" ;
VAL_ 2558534028 ADB_SW_Type_RUR 3 "NOT_OK" 2 "OK_x_C2" 1 "NOT_OK" 0 "NOT_OK" ;
VAL_ 2558534028 _nu_ADB_Network_Status_RUR 3 "NOT_USED" 2 "KEEP_ALIVE" 1 "READY_TO_SLEEP" 0 "NORMAL" ;
VAL_ 2558534026 ADB_SW_Type_RUC 3 "NOT_OK" 2 "OK_x_C2" 1 "NOT_OK" 0 "NOT_OK" ;
VAL_ 2558534026 _nu_ADB_Network_Status_RUC 3 "NOT_USED" 2 "KEEP_ALIVE" 1 "READY_TO_SLEEP" 0 "NORMAL" ;
VAL_ 2558534025 ADB_SW_Type_RUF 3 "NOT_OK" 2 "OK_x_C2" 1 "NOT_OK" 0 "NOT_OK" ;
VAL_ 2558534025 _nu_ADB_Network_Status_RUF 3 "NOT_USED" 2 "KEEP_ALIVE" 1 "READY_TO_SLEEP" 0 "NORMAL" ;
